VERSION "HNNBNNNYNNNNNNNNNNNNNNNNNNNNNNNNNNNNNNNNNN/4/%%%/4/'%**4NNN///"

NS_ :

BS_:

BU_: BAP_Tester BedienDisp_vo BedienSG_hi CGS DDA Gateway Gateway_PAG GurtMikrofon OTA_FC ZR_High ZR_LIMU ZR_MIB_TOP_ab_Gen3 ZR_Standard

BO_ 1626 BCM_01: 8 Gateway
 SG_ BCM_Bremsbelag_Sensor : 12|1@1+ (1.0,0.0) [0.0|1] ""  OTA_FC,ZR_High
 SG_ BCM_Bremsfluessigkeit_Sensor : 13|1@1+ (1.0,0.0) [0.0|1] ""  ZR_High
 SG_ BCM1_Licht_Warn : 14|1@1+ (1.0,0.0) [0.0|1] ""  Vector__XXX
 SG_ BCM_Waschwasser_Sensor : 15|1@1+ (1.0,0.0) [0.0|1] ""  OTA_FC,ZR_High
 SG_ BCM_Kuehlmittel_Sensor : 16|1@1+ (1.0,0.0) [0.0|1] ""  ZR_High
 SG_ BCM1_Kl_15_HW_erkannt : 17|1@1+ (1.0,0.0) [0.0|1] ""  Vector__XXX
 SG_ BCM1_Kl_15_Sig_HW_erkannt : 18|1@1+ (1.0,0.0) [0.0|1] ""  Vector__XXX
 SG_ BCM_Kuehlmittel_Sensor_02 : 19|1@1+ (1.0,0.0) [0.0|1] ""  ZR_High
 SG_ BCM1_Hinweis_Lichtnachlauf : 20|1@1+ (1.0,0.0) [0.0|1] ""  Vector__XXX
 SG_ BCM_Offroad_Taste : 21|1@1+ (1.0,0.0) [0.0|1] ""  Vector__XXX
 SG_ BCM_Hybrid_StSt_Taste_Fehler : 23|1@1+ (1.0,0.0) [0.0|1] ""  ZR_High
 SG_ BCM_Hybrid_StartStopp_Taste : 24|1@1+ (1.0,0.0) [0.0|1] ""  ZR_High
 SG_ BCM1_Warnblink_Taster : 25|1@1+ (1.0,0.0) [0.0|1] ""  ZR_High
 SG_ BCM1_Valet_Parking_Taster : 26|1@1+ (1.0,0.0) [0.0|1] ""  ZR_High
 SG_ BCM1_LDS_Stellung : 27|3@1+ (1.0,0.0) [0.0|7] ""  Vector__XXX
 SG_ BCM1_Rueckfahrlicht_Schalter : 30|1@1+ (1.0,0.0) [0.0|1] ""  Vector__XXX
 SG_ BCM1_MH_Schalter : 31|1@1+ (1.0,0.0) [0.0|1] ""  DDA,OTA_FC,ZR_High
 SG_ BCM1_MH_WIV_Schalter : 32|1@1+ (1.0,0.0) [0.0|1] ""  ZR_High
 SG_ BCM_Eco_Charisma_Taste : 33|1@1+ (1.0,0.0) [0.0|1] ""  Vector__XXX
 SG_ BCM1_NV_Taster : 34|1@1+ (1.0,0.0) [0.0|1] ""  ZR_High
 SG_ BCM1_AFS_Lampe : 35|1@1+ (1.0,0.0) [0.0|1] ""  ZR_High
 SG_ BCM1_Reisemodus_Texte : 36|2@1+ (1.0,0.0) [0.0|3] ""  ZR_High
 SG_ BCM1_Lichtwarn_Texte : 38|2@1+ (1.0,0.0) [0.0|3] ""  Vector__XXX
 SG_ Gong_TFL_Umschaltung : 40|1@1+ (1.0,0.0) [0.0|1] ""  Vector__XXX
 SG_ UGDO_Function_01 : 41|3@1+ (1.0,0.0) [0.0|7] ""  Vector__XXX
 SG_ APS_Tongeber_defekt : 44|1@1+ (1.0,0.0) [0.0|1] ""  Vector__XXX
 SG_ BCM1_EasyEntry_Status : 45|1@1+ (1.0,0.0) [0.0|1] ""  ZR_High
 SG_ BCM1_Lenksaeule_aktiv : 46|1@1+ (1.0,0.0) [0.0|1] ""  ZR_High
 SG_ BCM1_St_SW_Diebstahl_links : 47|1@1+ (1.0,0.0) [0.0|1] ""  ZR_High
 SG_ BCM1_St_SW_Diebstahl_rechts : 48|1@1+ (1.0,0.0) [0.0|1] ""  ZR_High
 SG_ ISP_Dimmung_ASP_02 : 49|6@1+ (0.0226,0) [0.0000|1.4012] "Unit_Volt"  Vector__XXX
 SG_ BCM1_Schluesselsuche_Anf : 55|1@1+ (1.0,0.0) [0.0|1] ""  Vector__XXX
 SG_ BCM1_Fahrlicht_Hinweis : 62|1@1+ (1.0,0.0) [0.0|1] ""  Vector__XXX
 SG_ BCM_HDF_betaetigt : 63|1@1+ (1.0,0.0) [0.0|1] ""  Vector__XXX

BO_ 672 BCM_02: 8 Gateway
 SG_ BCM_02_CRC : 0|8@1+ (1,0) [0|255] ""  Vector__XXX
 SG_ BCM_02_BZ : 8|4@1+ (1,0) [0|15] ""  Vector__XXX
 SG_ BCM2_Crashfall_erkannt : 12|1@1+ (1.0,0.0) [0.0|1] ""  Vector__XXX
 SG_ ZZH_Endlage_oben : 13|1@1+ (1.0,0.0) [0.0|1] ""  ZR_High
 SG_ ZZH_Endlage_unplausibel : 14|1@1+ (1.0,0.0) [0.0|1] ""  Vector__XXX
 SG_ ZZH_Endlage_unten : 15|1@1+ (1.0,0.0) [0.0|1] ""  ZR_High
 SG_ BCM2_Unterdr_Zuendungsmeldung : 16|1@1+ (1.0,0.0) [0.0|1] ""  Vector__XXX
 SG_ BCM2_SST_gedrueckt : 17|1@1+ (1.0,0.0) [0.0|1] ""  Vector__XXX
 SG_ BCM_Waehlhebel_P_Hinweis : 18|1@1+ (1.0,0.0) [0.0|1] ""  ZR_High
 SG_ BCM_ValetTaster_Fkts_LED : 19|1@1+ (1.0,0.0) [0.0|1] ""  ZR_High,ZR_LIMU,ZR_MIB_TOP_ab_Gen3,ZR_Standard
 SG_ BCM2_KL15_Absch_FT : 20|1@1+ (1.0,0.0) [0.0|1] ""  Vector__XXX
 SG_ Heckwischer_Status : 21|2@1+ (1.0,0.0) [0.0|3] ""  OTA_FC,ZR_High
 SG_ BCM2_P_verriegelt : 23|1@1+ (1.0,0.0) [0.0|1] ""  ZR_High
 SG_ FSH_LED : 24|1@1+ (1.0,0.0) [0.0|1] ""  ZR_High
 SG_ HSH_LED : 25|1@1+ (1.0,0.0) [0.0|1] ""  ZR_High
 SG_ Niveausensor_VL_verbaut : 26|1@1+ (1.0,0.0) [0.0|1] ""  Vector__XXX
 SG_ Niveausensor_HL_verbaut : 27|1@1+ (1.0,0.0) [0.0|1] ""  Vector__XXX
 SG_ FA_Hoehenwert_VL_01 : 28|8@1+ (0.4,0) [0.0|100.0] "Unit_PerCent"  Vector__XXX
 SG_ FA_Hoehenwert_HL_01 : 36|8@1+ (0.4,0) [0.0|100.0] "Unit_PerCent"  Vector__XXX
 SG_ BCM_Anf_Aussenwarnung : 44|1@1+ (1.0,0.0) [0.0|1] ""  Vector__XXX
 SG_ BCM_Aussenwarnung_Konfig : 45|3@1+ (1.0,0.0) [0.0|7] ""  Vector__XXX
 SG_ BCM2_Freigabe_Kofferr_Innenentr : 48|1@1+ (1.0,0.0) [0.0|1] ""  ZR_High
 SG_ BCM_RLU_Wakeup_Anforderung : 49|1@1+ (1.0,0.0) [0.0|1] ""  ZR_High,ZR_Standard
 SG_ Heckrollo_Privacy_aktiv : 50|1@1+ (1.0,0.0) [0.0|1] ""  BedienDisp_vo,ZR_High
 SG_ Heckrollo_Verfahrrichtung : 51|3@1+ (1.0,0.0) [0.0|7] ""  BedienDisp_vo,BedienSG_hi
 SG_ BCM2_TrunkEntrapment_Warn : 54|1@1+ (1.0,0.0) [0.0|1] ""  Vector__XXX
 SG_ BCM2_Quittierung_Warnton_aktiv : 55|1@1+ (1.0,0.0) [0.0|1] ""  Vector__XXX
 SG_ BCM_Handbremse_Hinweis : 56|1@1+ (1.0,0.0) [0.0|1] ""  Vector__XXX
 SG_ Remote_Rollo_HBFS_hoch : 57|1@1+ (1.0,0.0) [0.0|1] ""  Vector__XXX
 SG_ Remote_Rollo_HBFS_tief : 58|1@1+ (1.0,0.0) [0.0|1] ""  Vector__XXX
 SG_ Remote_Rollo_HFS_hoch : 59|1@1+ (1.0,0.0) [0.0|1] ""  Vector__XXX
 SG_ Remote_Rollo_HFS_tief : 60|1@1+ (1.0,0.0) [0.0|1] ""  Vector__XXX
 SG_ BCM2_T_Deckel_Vorne : 61|1@1+ (1.0,0.0) [0.0|1] ""  Vector__XXX

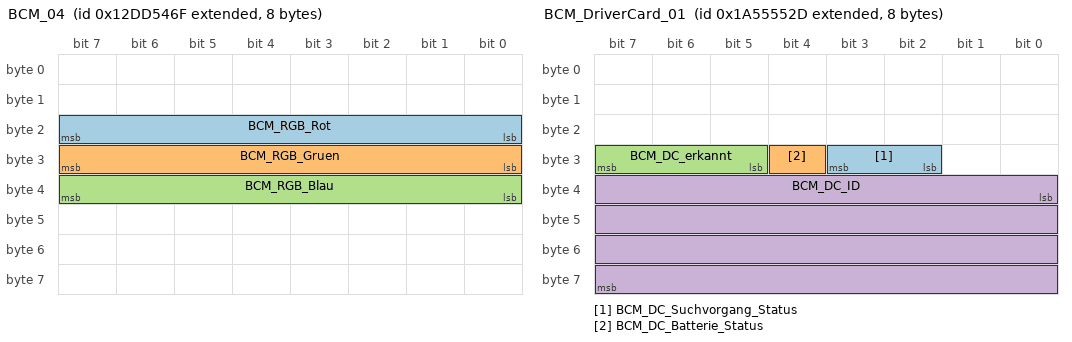
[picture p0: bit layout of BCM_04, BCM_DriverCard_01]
BO_ 2463978607 BCM_04: 8 Gateway
 SG_ BCM_RGB_Rot : 16|8@1+ (1,0) [0|255] ""  ZR_High
 SG_ BCM_RGB_Gruen : 24|8@1+ (1,0) [0|255] ""  ZR_High
 SG_ BCM_RGB_Blau : 32|8@1+ (1,0) [0|255] ""  ZR_High

BO_ 2589283629 BCM_DriverCard_01: 8 Gateway
 SG_ BCM_DC_Suchvorgang_Status : 26|2@1+ (1.0,0.0) [0.0|3] ""  ZR_High
 SG_ BCM_DC_Batterie_Status : 28|1@1+ (1.0,0.0) [0.0|1] ""  ZR_High
 SG_ BCM_DC_erkannt : 29|3@1+ (1.0,0.0) [0.0|7] ""  ZR_High
 SG_ BCM_DC_ID : 32|32@1+ (1,0) [0|4294967294] ""  Vector__XXX

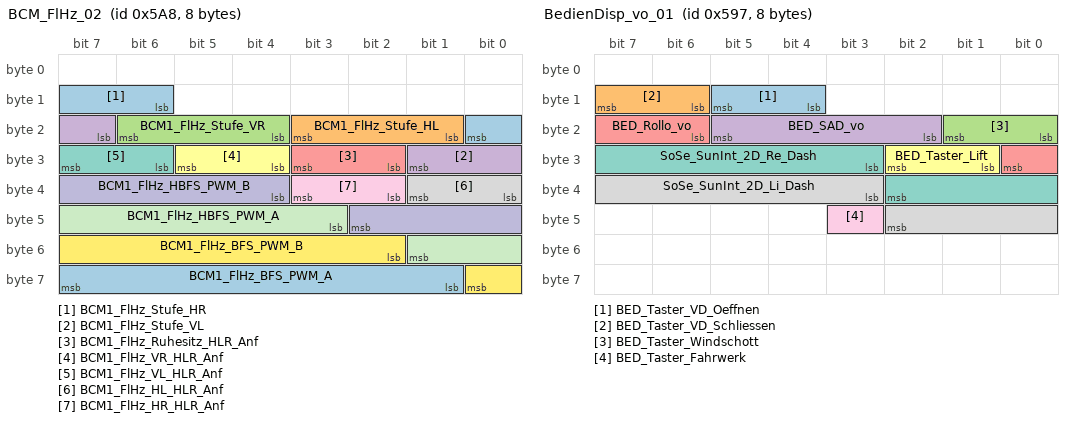
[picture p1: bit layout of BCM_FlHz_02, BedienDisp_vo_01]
BO_ 1448 BCM_FlHz_02: 8 Gateway
 SG_ BCM1_FlHz_Stufe_HR : 14|3@1+ (1.0,0.0) [0.0|7] ""  ZR_High
 SG_ BCM1_FlHz_Stufe_HL : 17|3@1+ (1.0,0.0) [0.0|7] ""  ZR_High
 SG_ BCM1_FlHz_Stufe_VR : 20|3@1+ (1.0,0.0) [0.0|7] ""  ZR_High
 SG_ BCM1_FlHz_Stufe_VL : 23|3@1+ (1.0,0.0) [0.0|7] ""  ZR_High
 SG_ BCM1_FlHz_Ruhesitz_HLR_Anf : 26|2@1+ (1.0,0.0) [0.0|3] ""  ZR_High
 SG_ BCM1_FlHz_VR_HLR_Anf : 28|2@1+ (1.0,0.0) [0.0|3] ""  ZR_High
 SG_ BCM1_FlHz_VL_HLR_Anf : 30|2@1+ (1.0,0.0) [0.0|3] ""  ZR_High
 SG_ BCM1_FlHz_HL_HLR_Anf : 32|2@1+ (1.0,0.0) [0.0|3] ""  ZR_High
 SG_ BCM1_FlHz_HR_HLR_Anf : 34|2@1+ (1.0,0.0) [0.0|3] ""  ZR_High
 SG_ BCM1_FlHz_HBFS_PWM_B : 36|7@1+ (1,0) [0|100] "Unit_PerCent"  Vector__XXX
 SG_ BCM1_FlHz_HBFS_PWM_A : 43|7@1+ (1,0) [0|100] "Unit_PerCent"  Vector__XXX
 SG_ BCM1_FlHz_BFS_PWM_B : 50|7@1+ (1,0) [0|100] "Unit_PerCent"  Vector__XXX
 SG_ BCM1_FlHz_BFS_PWM_A : 57|7@1+ (1,0) [0|100] "Unit_PerCent"  Vector__XXX

BO_ 961 BCM_Taster_01: 8 Gateway
 SG_ Heckrollo_2_Taster : 10|2@1+ (1.0,0.0) [0.0|3] ""  Vector__XXX
 SG_ APS_Taster : 12|2@1+ (1.0,0.0) [0.0|3] ""  ZR_High
 SG_ PLA_Taster : 14|2@1+ (1.0,0.0) [0.0|3] ""  ZR_High,ZR_LIMU,ZR_MIB_TOP_ab_Gen3,ZR_Standard
 SG_ ESP_Off_Taster : 16|2@1+ (1.0,0.0) [0.0|3] ""  OTA_FC,ZR_High
 SG_ HDC_Taster : 18|2@1+ (1.0,0.0) [0.0|3] ""  ZR_High
 SG_ AVH_Taster : 20|2@1+ (1.0,0.0) [0.0|3] ""  ZR_High
 SG_ Display_Taster : 22|2@1+ (1.0,0.0) [0.0|3] ""  ZR_High,ZR_LIMU,ZR_MIB_TOP_ab_Gen3,ZR_Standard
 SG_ Heckrollo_Taster : 24|2@1+ (1.0,0.0) [0.0|3] ""  ZR_High
 SG_ Spoiler_Taster : 26|2@1+ (1.0,0.0) [0.0|3] ""  OTA_FC,ZR_High
 SG_ Drivesel_1_Taster : 28|2@1+ (1.0,0.0) [0.0|3] ""  ZR_High
 SG_ Drivesel_2_Taster : 30|2@1+ (1.0,0.0) [0.0|3] ""  ZR_High
 SG_ Sideview_Taster : 32|2@1+ (1.0,0.0) [0.0|3] ""  ZR_High
 SG_ LIM_PAO_Alivesignal : 34|4@1+ (1,0) [0|15] ""  Vector__XXX
 SG_ LKS_Taster : 38|2@1+ (1.0,0.0) [0.0|3] ""  Vector__XXX
 SG_ SWA_Taster : 40|2@1+ (1.0,0.0) [0.0|3] ""  ZR_High
 SG_ LIM_bCall_Taster : 42|1@1+ (1.0,0.0) [0.0|1] ""  ZR_High
 SG_ eCall_Taste : 43|2@1+ (1.0,0.0) [0.0|3] ""  ZR_High,ZR_LIMU,ZR_MIB_TOP_ab_Gen3
 SG_ PLA_Taster_Fehler_Roh : 45|1@1+ (1.0,0.0) [0.0|1] ""  Vector__XXX
 SG_ LIM_PAO_ON_Status : 46|2@1+ (1.0,0.0) [0.0|3] ""  Vector__XXX
 SG_ LIM_PAO_OFF_Status : 48|2@1+ (1.0,0.0) [0.0|3] ""  Vector__XXX
 SG_ LIM_PAO_Schriftzug_Status : 50|2@1+ (1.0,0.0) [0.0|3] ""  Vector__XXX
 SG_ Spoiler_LED_Status : 52|2@1+ (1.0,0.0) [0.0|3] ""  Vector__XXX
 SG_ AVH_LED_Status : 54|2@1+ (1.0,0.0) [0.0|3] ""  Vector__XXX
 SG_ HDC_LED_Status : 56|2@1+ (1.0,0.0) [0.0|3] ""  Vector__XXX
 SG_ PLA_LED_Status : 60|2@1+ (1.0,0.0) [0.0|3] ""  Vector__XXX
 SG_ APS_LED_Status : 62|2@1+ (1.0,0.0) [0.0|3] ""  Vector__XXX

BO_ 1432 BCM_Taster_02: 8 Gateway
 SG_ BCM_BFS_Fernsteuerung_aktiv : 28|1@1+ (1.0,0.0) [0.0|1] ""  Vector__XXX
 SG_ BCM_Soundklappe_Taster : 29|1@1+ (1.0,0.0) [0.0|1] ""  Vector__XXX
 SG_ E_Sound_LED_Status : 30|2@1+ (1.0,0.0) [0.0|3] ""  Vector__XXX
 SG_ Pilot_Taster : 32|2@1+ (1.0,0.0) [0.0|3] ""  ZR_High
 SG_ BCM1_eSound_Taster : 34|2@1+ (1.0,0.0) [0.0|3] ""  ZR_High
 SG_ BCM_FS_Programmwippe : 37|1@1+ (1.0,0.0) [0.0|1] ""  ZR_High
 SG_ BCM_BFS_Programmwippe : 38|1@1+ (1.0,0.0) [0.0|1] ""  ZR_High
 SG_ BCM_FS_Multif_Taster : 39|1@1+ (1.0,0.0) [0.0|1] ""  ZR_High
 SG_ BCM_BFS_Multif_Taster : 40|1@1+ (1.0,0.0) [0.0|1] ""  ZR_High
 SG_ BCM_FS_Massage_Taster : 41|1@1+ (1.0,0.0) [0.0|1] ""  ZR_High
 SG_ BCM_BFS_Massage_Taster : 42|1@1+ (1.0,0.0) [0.0|1] ""  ZR_High
 SG_ BCM_FS_Pneumatik_Verstellung : 43|1@1+ (1.0,0.0) [0.0|1] ""  ZR_High
 SG_ BCM_BFS_Pneumatik_Verstellung : 44|1@1+ (1.0,0.0) [0.0|1] ""  ZR_High
 SG_ LIM_Rear_Mode : 45|1@1+ (1.0,0.0) [0.0|1] ""  Vector__XXX
 SG_ BCM1_NR_Ride_Height_Up_Taster : 46|2@1+ (1.0,0.0) [0.0|3] ""  ZR_High
 SG_ BCM1_NR_Ride_Height_Down_Taster : 48|2@1+ (1.0,0.0) [0.0|3] ""  ZR_High
 SG_ LIM_S_Rollo_vo : 50|3@1+ (1.0,0.0) [0.0|7] ""  ZR_High
 SG_ LIM_S_Rollo_hi : 53|3@1+ (1.0,0.0) [0.0|7] ""  ZR_High
 SG_ LIM_S_SAD_Vo : 56|4@1+ (1.0,0.0) [0.0|15] ""  ZR_High
 SG_ LIM_S_SAD_hi : 60|4@1+ (1.0,0.0) [0.0|15] ""  ZR_High

BO_ 1462 BEB_hi_01: 8 BedienDisp_vo
 SG_ BEB_hi_SAD_Rollo_AutoAuf : 12|1@1+ (1.0,0.0) [0.0|1] ""  Gateway,Gateway_PAG,ZR_High
 SG_ BEB_hi_SAD_Rollo_AutoZu : 13|1@1+ (1.0,0.0) [0.0|1] ""  Gateway,Gateway_PAG,ZR_High
 SG_ BEB_hi_SAD_Rollo_ManAuf : 14|1@1+ (1.0,0.0) [0.0|1] ""  Gateway,Gateway_PAG,ZR_High
 SG_ BEB_hi_SAD_Rollo_ManZu : 15|1@1+ (1.0,0.0) [0.0|1] ""  Gateway,Gateway_PAG,ZR_High
 SG_ BEB_hi_T_SIH_HL : 16|1@1+ (1.0,0.0) [0.0|1] ""  Gateway,Gateway_PAG,ZR_High
 SG_ BEB_hi_T_SIH_HR : 17|1@1+ (1.0,0.0) [0.0|1] ""  Gateway,Gateway_PAG,ZR_High
 SG_ BEB_hi_T_SIL_HL : 18|1@1+ (1.0,0.0) [0.0|1] ""  Gateway,Gateway_PAG,ZR_High
 SG_ BEB_hi_T_SIL_HR : 19|1@1+ (1.0,0.0) [0.0|1] ""  Gateway,Gateway_PAG,ZR_High
 SG_ SL1_Heckrollo_Taster : 20|2@1+ (1.0,0.0) [0.0|3] ""  Gateway,Gateway_PAG,ZR_High
 SG_ BEB_hi_SAD_Rollo_defekt : 22|1@1+ (1.0,0.0) [0.0|1] ""  Gateway,Gateway_PAG,ZR_High
 SG_ BEB_hi_SAD_Rollo_haengt : 23|1@1+ (1.0,0.0) [0.0|1] ""  Gateway,Gateway_PAG,ZR_High
 SG_ BEB_hi_T_Lueftung : 24|1@1+ (1.0,0.0) [0.0|1] ""  Gateway,Gateway_PAG,ZR_High
 SG_ BEB_hi_T_Lueftung_oben : 25|1@1+ (1.0,0.0) [0.0|1] ""  Gateway,Gateway_PAG,ZR_High
 SG_ BEB_hi_T_Lueftung_unten : 26|1@1+ (1.0,0.0) [0.0|1] ""  Gateway,Gateway_PAG,ZR_High
 SG_ BEB_hi_T_Lueftung_LZ_links : 27|1@1+ (1.0,0.0) [0.0|1] ""  Gateway,Gateway_PAG,ZR_High
 SG_ BEB_hi_T_Lueftung_LZ_rechts : 28|1@1+ (1.0,0.0) [0.0|1] ""  Gateway,Gateway_PAG,ZR_High
 SG_ BEB_hi_T_Lueftung_RZ_links : 29|1@1+ (1.0,0.0) [0.0|1] ""  Gateway,Gateway_PAG,ZR_High
 SG_ BEB_hi_T_Lueftung_RZ_rechts : 30|1@1+ (1.0,0.0) [0.0|1] ""  Gateway,Gateway_PAG,ZR_High
 SG_ BEB_hi_ResponseError : 63|1@1+ (1.0,0.0) [0.0|1] ""  Gateway,Gateway_PAG

BO_ 1431 BedienDisp_vo_01: 8 BedienDisp_vo
 SG_ BED_Taster_VD_Oeffnen : 12|2@1+ (1.0,0.0) [0.0|3] ""  Gateway,Gateway_PAG
 SG_ BED_Taster_VD_Schliessen : 14|2@1+ (1.0,0.0) [0.0|3] ""  Gateway,Gateway_PAG
 SG_ BED_Taster_Windschott : 16|2@1+ (1.0,0.0) [0.0|3] ""  Gateway,Gateway_PAG
 SG_ BED_SAD_vo : 18|4@1+ (1.0,0.0) [0.0|15] ""  Gateway,Gateway_PAG
 SG_ BED_Rollo_vo : 22|3@1+ (1.0,0.0) [0.0|7] ""  Gateway,Gateway_PAG
 SG_ BED_Taster_Lift : 25|2@1+ (1.0,0.0) [0.0|3] ""  Gateway,Gateway_PAG
 SG_ SoSe_SunInt_2D_Re_Dash : 27|8@1+ (5,0) [0|1200] "Unit_WattPerMeterSquar"  Gateway,Gateway_PAG
 SG_ SoSe_SunInt_2D_Li_Dash : 35|8@1+ (5,0) [0|1200] "Unit_WattPerMeterSquar"  Gateway,Gateway_PAG
 SG_ BED_Taster_Fahrwerk : 43|1@1+ (1.0,0.0) [0.0|1] ""  Gateway,Gateway_PAG

BO_ 870 Blinkmodi_02: 8 Gateway
 SG_ BM_ZV_auf : 12|1@1+ (1.0,0.0) [0.0|1] ""  ZR_High
 SG_ BM_ZV_zu : 13|1@1+ (1.0,0.0) [0.0|1] ""  ZR_High
 SG_ BM_DWA_ein : 14|1@1+ (1.0,0.0) [0.0|1] ""  ZR_High
 SG_ BM_DWA_Alarm : 15|1@1+ (1.0,0.0) [0.0|1] ""  ZR_High
 SG_ BM_Crash : 16|1@1+ (1.0,0.0) [0.0|1] ""  ZR_High
 SG_ BM_Panik : 17|1@1+ (1.0,0.0) [0.0|1] ""  ZR_High
 SG_ BM_Not_Bremsung : 18|1@1+ (1.0,0.0) [0.0|1] ""  ZR_High
 SG_ BM_GDO : 19|1@1+ (1.0,0.0) [0.0|1] ""  Vector__XXX
 SG_ BM_Warnblinken : 20|1@1+ (1.0,0.0) [0.0|1] ""  ZR_High
 SG_ BM_Taxi_Notalarm : 21|1@1+ (1.0,0.0) [0.0|1] ""  ZR_High
 SG_ BM_Telematik : 22|1@1+ (1.0,0.0) [0.0|1] ""  ZR_High
 SG_ BM_links : 23|1@1+ (1.0,0.0) [0.0|1] ""  ZR_High
 SG_ BM_rechts : 24|1@1+ (1.0,0.0) [0.0|1] ""  ZR_High
 SG_ Blinken_li_Fzg_Takt : 25|1@1+ (1.0,0.0) [0.0|1] ""  ZR_High
 SG_ Blinken_re_Fzg_Takt : 26|1@1+ (1.0,0.0) [0.0|1] ""  ZR_High
 SG_ Blinken_li_Kombi_Takt : 27|1@1+ (1.0,0.0) [0.0|1] ""  ZR_High,ZR_LIMU,ZR_MIB_TOP_ab_Gen3,ZR_Standard
 SG_ Blinken_re_Kombi_Takt : 28|1@1+ (1.0,0.0) [0.0|1] ""  ZR_High,ZR_LIMU,ZR_MIB_TOP_ab_Gen3,ZR_Standard
 SG_ BM_NBA_n_codiert_n_aktiv : 29|1@1+ (1.0,0.0) [0.0|1] ""  Vector__XXX
 SG_ BM_NBA_Status : 30|2@1+ (1.0,0.0) [0.0|3] ""  Vector__XXX
 SG_ BM_WBT_Beleuchtung : 32|1@1+ (1.0,0.0) [0.0|1] ""  ZR_High
 SG_ BM_HD_Oeffnung_angelernt : 33|1@1+ (1.0,0.0) [0.0|1] ""  Vector__XXX
 SG_ BM_Autobahn : 34|1@1+ (1.0,0.0) [0.0|1] ""  ZR_High,ZR_LIMU,ZR_MIB_TOP_ab_Gen3
 SG_ BM_Rollenmodus_Blinken : 35|1@1+ (1.0,0.0) [0.0|1] ""  Vector__XXX
 SG_ BM_Recas : 36|1@1+ (1.0,0.0) [0.0|1] ""  ZR_High
 SG_ BM_Wischblinken : 37|1@1+ (1.0,0.0) [0.0|1] ""  ZR_High
 SG_ BM_Telematik_Abbruchgrund : 38|6@1+ (1.0,0.0) [0.0|63] ""  Vector__XXX
 SG_ BM_PiloPa : 44|1@1+ (1.0,0.0) [0.0|1] ""  ZR_High
 SG_ DWA_Alarmquelle : 59|5@1+ (1.0,0.0) [0.0|31] ""  ZR_High

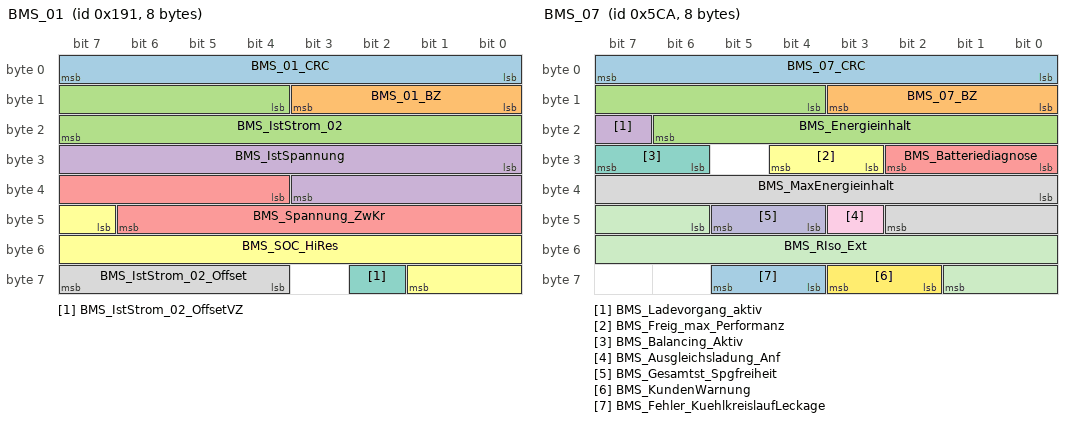
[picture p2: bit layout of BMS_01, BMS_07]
BO_ 401 BMS_01: 8 Gateway
 SG_ BMS_01_CRC : 0|8@1+ (1,0) [0|255] ""  Vector__XXX
 SG_ BMS_01_BZ : 8|4@1+ (1,0) [0|15] ""  Vector__XXX
 SG_ BMS_IstStrom_02 : 12|12@1+ (1,-2047) [-2047|2046] "Unit_Amper"  OTA_FC,ZR_High
 SG_ BMS_IstSpannung : 24|12@1+ (0.25,0) [0.00|1023.25] "Unit_Volt"  BedienSG_hi,OTA_FC,ZR_High
 SG_ BMS_Spannung_ZwKr : 36|11@1+ (0.5,0) [0.0|1022.5] "Unit_Volt"  OTA_FC,ZR_High
 SG_ BMS_SOC_HiRes : 47|11@1+ (0.05,0) [0.00|100.00] "Unit_PerCent"  OTA_FC,ZR_High
 SG_ BMS_IstStrom_02_OffsetVZ : 58|1@1+ (1.0,0.0) [0.0|1] ""  OTA_FC
 SG_ BMS_IstStrom_02_Offset : 60|4@1+ (0.0625,0) [0.0000|0.9375] "Unit_Amper"  OTA_FC

BO_ 1482 BMS_07: 8 Gateway
 SG_ BMS_07_CRC : 0|8@1+ (1,0) [0|255] ""  Vector__XXX
 SG_ BMS_07_BZ : 8|4@1+ (1,0) [0|15] ""  Vector__XXX
 SG_ BMS_Energieinhalt : 12|11@1+ (50,0) [0|102250] "Unit_WattHour"  OTA_FC
 SG_ BMS_Ladevorgang_aktiv : 23|1@1+ (1.0,0.0) [0.0|1] ""  OTA_FC,ZR_LIMU,ZR_MIB_TOP_ab_Gen3
 SG_ BMS_Batteriediagnose : 24|3@1+ (1.0,0.0) [0.0|7] ""  Vector__XXX
 SG_ BMS_Freig_max_Performanz : 27|2@1+ (1.0,0.0) [0.0|3] ""  Vector__XXX
 SG_ BMS_Balancing_Aktiv : 30|2@1+ (1.0,0.0) [0.0|3] ""  Vector__XXX
 SG_ BMS_MaxEnergieinhalt : 32|11@1+ (50,0) [0|102250] "Unit_WattHour"  OTA_FC
 SG_ BMS_Ausgleichsladung_Anf : 43|1@1+ (1.0,0.0) [0.0|1] ""  Vector__XXX
 SG_ BMS_Gesamtst_Spgfreiheit : 44|2@1+ (1.0,0.0) [0.0|3] ""  Vector__XXX
 SG_ BMS_RIso_Ext : 46|12@1+ (5,0) [0|20465] "Unit_KiloOhm"  Vector__XXX
 SG_ BMS_KundenWarnung : 58|2@1+ (1.0,0.0) [0.0|3] ""  Vector__XXX
 SG_ BMS_Fehler_KuehlkreislaufLeckage : 60|2@1+ (1.0,0.0) [0.0|3] ""  Vector__XXX

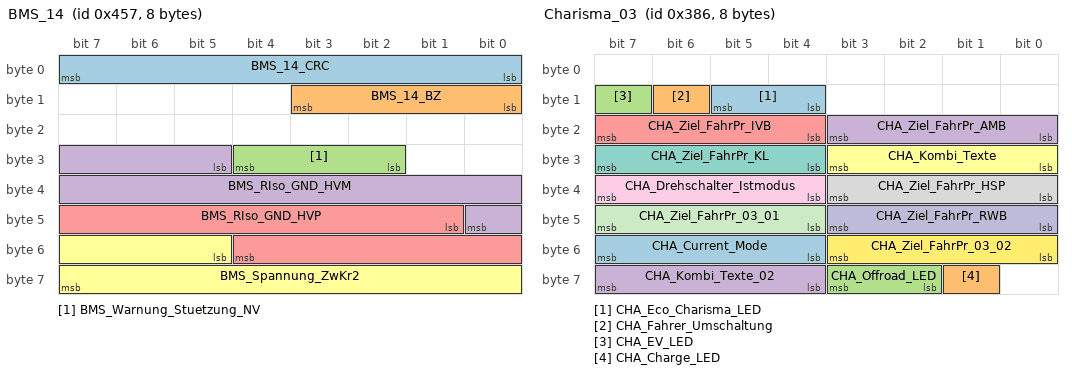
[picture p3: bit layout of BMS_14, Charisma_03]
BO_ 1111 BMS_14: 8 Gateway
 SG_ BMS_14_CRC : 0|8@1+ (1,0) [0|255] ""  Vector__XXX
 SG_ BMS_14_BZ : 8|4@1+ (1,0) [0|15] ""  Vector__XXX
 SG_ BMS_Warnung_Stuetzung_NV : 26|3@1+ (1.0,0.0) [0.0|7] ""  Vector__XXX
 SG_ BMS_RIso_GND_HVM : 29|12@1+ (5,-20465) [-20465|0] "Unit_KiloOhm"  Vector__XXX
 SG_ BMS_RIso_GND_HVP : 41|12@1+ (5,0) [0|20465] "Unit_KiloOhm"  Vector__XXX
 SG_ BMS_Spannung_ZwKr2 : 53|11@1+ (0.5,0) [0.0|1022.5] "Unit_Volt"  ZR_High

BO_ 823 CC_Einzelhindernis_01: 8 Gateway
 SG_ CC_MessZeitpunkt_OffsetHindernis : 0|2@1+ (5.08,0) [0.00|15.24] "Unit_Secon"  ZR_High,ZR_LIMU,ZR_MIB_TOP_ab_Gen3
 SG_ CC_MessZeitpunkt_Hindernis : 2|7@1+ (0.04,0) [0.00|5.04] "Unit_None"  ZR_High,ZR_LIMU,ZR_MIB_TOP_ab_Gen3
 SG_ CC_MessZeitpunkt_ms_Hindernis : 9|6@1+ (1,0) [0|39] "Unit_MilliSecon"  ZR_High,ZR_LIMU,ZR_MIB_TOP_ab_Gen3
 SG_ CC_Einzelhindernis_01 : 16|4@1+ (1.0,0.0) [0.0|15] ""  ZR_High,ZR_LIMU,ZR_MIB_TOP_ab_Gen3
 SG_ CC_CF_Einzelhindernis_01 : 20|2@1+ (1.0,0.0) [0.0|3] ""  ZR_High,ZR_LIMU,ZR_MIB_TOP_ab_Gen3
 SG_ CC_Einzelhindernis_02 : 22|4@1+ (1.0,0.0) [0.0|15] ""  ZR_High,ZR_LIMU,ZR_MIB_TOP_ab_Gen3
 SG_ CC_CF_Einzelhindernis_02 : 26|2@1+ (1.0,0.0) [0.0|3] ""  ZR_High,ZR_LIMU,ZR_MIB_TOP_ab_Gen3
 SG_ CC_Einzelhindernis_03 : 28|4@1+ (1.0,0.0) [0.0|15] ""  ZR_High,ZR_LIMU,ZR_MIB_TOP_ab_Gen3
 SG_ CC_CF_Einzelhindernis_03 : 32|2@1+ (1.0,0.0) [0.0|3] ""  ZR_High,ZR_LIMU,ZR_MIB_TOP_ab_Gen3
 SG_ CC_Einzelhindernis_04 : 34|4@1+ (1.0,0.0) [0.0|15] ""  ZR_High,ZR_LIMU,ZR_MIB_TOP_ab_Gen3
 SG_ CC_CF_Einzelhindernis_04 : 38|2@1+ (1.0,0.0) [0.0|3] ""  ZR_High,ZR_LIMU,ZR_MIB_TOP_ab_Gen3
 SG_ CC_Einzelhindernis_05 : 40|4@1+ (1.0,0.0) [0.0|15] ""  ZR_High,ZR_LIMU,ZR_MIB_TOP_ab_Gen3
 SG_ CC_CF_Einzelhindernis_05 : 44|2@1+ (1.0,0.0) [0.0|3] ""  ZR_High,ZR_LIMU,ZR_MIB_TOP_ab_Gen3
 SG_ CC_Einzelhindernis_06 : 46|4@1+ (1.0,0.0) [0.0|15] ""  ZR_High,ZR_LIMU,ZR_MIB_TOP_ab_Gen3
 SG_ CC_CF_Einzelhindernis_06 : 50|2@1+ (1.0,0.0) [0.0|3] ""  ZR_High,ZR_LIMU,ZR_MIB_TOP_ab_Gen3
 SG_ CC_Einzelhindernis_07 : 52|4@1+ (1.0,0.0) [0.0|15] ""  ZR_High,ZR_LIMU,ZR_MIB_TOP_ab_Gen3
 SG_ CC_CF_Einzelhindernis_07 : 56|2@1+ (1.0,0.0) [0.0|3] ""  ZR_High,ZR_LIMU,ZR_MIB_TOP_ab_Gen3
 SG_ CC_Einzelhindernis_08 : 58|4@1+ (1.0,0.0) [0.0|15] ""  ZR_High,ZR_LIMU,ZR_MIB_TOP_ab_Gen3
 SG_ CC_CF_Einzelhindernis_08 : 62|2@1+ (1.0,0.0) [0.0|3] ""  ZR_High,ZR_LIMU,ZR_MIB_TOP_ab_Gen3

BO_ 824 CC_Strassenkategorie_01: 8 Gateway
 SG_ CC_MessZeitpunkt_OffsetStrZustan : 0|2@1+ (5.08,0) [0.00|15.24] "Unit_Secon"  ZR_High,ZR_LIMU,ZR_MIB_TOP_ab_Gen3
 SG_ CC_MessZeitpunkt_Strassenzustand : 2|7@1+ (0.04,0) [0.00|5.04] "Unit_None"  ZR_High,ZR_LIMU,ZR_MIB_TOP_ab_Gen3
 SG_ CC_MessZeitpunkt_ms_StrZustand : 9|6@1+ (1,0) [0|39] "Unit_MilliSecon"  ZR_High,ZR_LIMU,ZR_MIB_TOP_ab_Gen3
 SG_ CC_Strassenkategorie_01 : 16|4@1+ (1.0,0.0) [0.0|15] ""  ZR_High,ZR_LIMU,ZR_MIB_TOP_ab_Gen3
 SG_ CC_CF_Strassenkategorie_01 : 20|2@1+ (1.0,0.0) [0.0|3] ""  ZR_High,ZR_LIMU,ZR_MIB_TOP_ab_Gen3
 SG_ CC_Strassenkategorie_02 : 22|4@1+ (1.0,0.0) [0.0|15] ""  ZR_High,ZR_LIMU,ZR_MIB_TOP_ab_Gen3
 SG_ CC_CF_Strassenkategorie_02 : 26|2@1+ (1.0,0.0) [0.0|3] ""  ZR_High,ZR_LIMU,ZR_MIB_TOP_ab_Gen3
 SG_ CC_Strassenkategorie_03 : 28|4@1+ (1.0,0.0) [0.0|15] ""  ZR_High,ZR_LIMU,ZR_MIB_TOP_ab_Gen3
 SG_ CC_CF_Strassenkategorie_03 : 32|2@1+ (1.0,0.0) [0.0|3] ""  ZR_High,ZR_LIMU,ZR_MIB_TOP_ab_Gen3
 SG_ CC_Strassenkategorie_04 : 34|4@1+ (1.0,0.0) [0.0|15] ""  ZR_High,ZR_LIMU,ZR_MIB_TOP_ab_Gen3
 SG_ CC_CF_Strassenkategorie_04 : 38|2@1+ (1.0,0.0) [0.0|3] ""  ZR_High,ZR_LIMU,ZR_MIB_TOP_ab_Gen3
 SG_ CC_Strassenkategorie_05 : 40|4@1+ (1.0,0.0) [0.0|15] ""  ZR_High,ZR_LIMU,ZR_MIB_TOP_ab_Gen3
 SG_ CC_CF_Strassenkategorie_05 : 44|2@1+ (1.0,0.0) [0.0|3] ""  ZR_High,ZR_LIMU,ZR_MIB_TOP_ab_Gen3
 SG_ CC_Strassenkategorie_06 : 46|4@1+ (1.0,0.0) [0.0|15] ""  ZR_High,ZR_LIMU,ZR_MIB_TOP_ab_Gen3
 SG_ CC_CF_Strassenkategorie_06 : 50|2@1+ (1.0,0.0) [0.0|3] ""  ZR_High,ZR_LIMU,ZR_MIB_TOP_ab_Gen3
 SG_ CC_Strassenkategorie_07 : 52|4@1+ (1.0,0.0) [0.0|15] ""  ZR_High,ZR_LIMU,ZR_MIB_TOP_ab_Gen3
 SG_ CC_CF_Strassenkategorie_07 : 56|2@1+ (1.0,0.0) [0.0|3] ""  ZR_High,ZR_LIMU,ZR_MIB_TOP_ab_Gen3
 SG_ CC_Strassenkategorie_08 : 58|4@1+ (1.0,0.0) [0.0|15] ""  ZR_High,ZR_LIMU,ZR_MIB_TOP_ab_Gen3
 SG_ CC_CF_Strassenkategorie_08 : 62|2@1+ (1.0,0.0) [0.0|3] ""  ZR_High,ZR_LIMU,ZR_MIB_TOP_ab_Gen3

BO_ 825 CC_Version_01: 8 Gateway
 SG_ CC_Version_Hindernis : 0|7@1+ (1,0) [1|127] "Unit_None"  ZR_High,ZR_LIMU,ZR_MIB_TOP_ab_Gen3
 SG_ CC_Version_Strassenkategorie : 7|7@1+ (1,0) [1|127] "Unit_None"  ZR_High,ZR_LIMU,ZR_MIB_TOP_ab_Gen3

BO_ 901 Charisma_01: 8 Gateway
 SG_ CHA_Ziel_FahrPr_AGA : 0|4@1+ (1.0,0.0) [0.0|15] ""  OTA_FC,ZR_High
 SG_ CHA_Ziel_FahrPr_ESP : 4|4@1+ (1.0,0.0) [0.0|15] ""  ZR_High
 SG_ CHA_Ziel_FahrPr_Freilauf : 8|4@1+ (1.0,0.0) [0.0|15] ""  ZR_High
 SG_ CHA_Fahrer_Umschaltung : 14|1@1+ (1.0,0.0) [0.0|1] ""  ZR_High
 SG_ CHA_Fahrer_Umschaltung_BMA : 15|1@1+ (1.0,0.0) [0.0|1] ""  ZR_High
 SG_ CHA_Ziel_FahrPr_MO : 16|4@1+ (1.0,0.0) [0.0|15] ""  ZR_High
 SG_ CHA_Ziel_FahrPr_GE : 20|4@1+ (1.0,0.0) [0.0|15] ""  ZR_High
 SG_ CHA_Ziel_FahrPr_ALR : 24|4@1+ (1.0,0.0) [0.0|15] ""  ZR_High
 SG_ CHA_Ziel_FahrPr_MO_BZS : 28|4@1+ (1.0,0.0) [0.0|15] ""  ZR_High
 SG_ CHA_Ziel_FahrPr_DR : 32|4@1+ (1.0,0.0) [0.0|15] ""  ZR_High
 SG_ CHA_Ziel_FahrPr_VAQ : 36|4@1+ (1.0,0.0) [0.0|15] ""  Vector__XXX
 SG_ CHA_Ziel_FahrPr_AFS : 40|4@1+ (1.0,0.0) [0.0|15] ""  ZR_High
 SG_ CHA_Ziel_FahrPr_PreCrash : 44|4@1+ (1.0,0.0) [0.0|15] ""  ZR_High
 SG_ CHA_Ziel_FahrPr_EPS : 48|4@1+ (1.0,0.0) [0.0|15] ""  ZR_High
 SG_ CHA_Ziel_FahrPr_ACC : 52|4@1+ (1.0,0.0) [0.0|15] ""  OTA_FC,ZR_High
 SG_ CHA_Ziel_FahrPr_SAK : 56|4@1+ (1.0,0.0) [0.0|15] ""  OTA_FC,ZR_High
 SG_ CHA_Ziel_FahrPr_MO_StSt : 60|4@1+ (1.0,0.0) [0.0|15] ""  ZR_High

BO_ 902 Charisma_03: 8 Gateway
 SG_ CHA_Eco_Charisma_LED : 12|2@1+ (1.0,0.0) [0.0|3] ""  Vector__XXX
 SG_ CHA_Fahrer_Umschaltung : 14|1@1+ (1.0,0.0) [0.0|1] ""  Vector__XXX
 SG_ CHA_EV_LED : 15|1@1+ (1.0,0.0) [0.0|1] ""  Vector__XXX
 SG_ CHA_Ziel_FahrPr_AMB : 16|4@1+ (1.0,0.0) [0.0|15] ""  Vector__XXX
 SG_ CHA_Ziel_FahrPr_IVB : 20|4@1+ (1.0,0.0) [0.0|15] ""  Vector__XXX
 SG_ CHA_Kombi_Texte : 24|4@1+ (1.0,0.0) [0.0|15] ""  Vector__XXX
 SG_ CHA_Ziel_FahrPr_KL : 28|4@1+ (1.0,0.0) [0.0|15] ""  Vector__XXX
 SG_ CHA_Ziel_FahrPr_HSP : 32|4@1+ (1.0,0.0) [0.0|15] ""  OTA_FC
 SG_ CHA_Drehschalter_Istmodus : 36|4@1+ (1.0,0.0) [0.0|15] ""  Vector__XXX
 SG_ CHA_Ziel_FahrPr_RWB : 40|4@1+ (1.0,0.0) [0.0|15] ""  OTA_FC
 SG_ CHA_Ziel_FahrPr_03_01 : 44|4@1+ (1.0,0.0) [0.0|15] ""  Vector__XXX
 SG_ CHA_Ziel_FahrPr_03_02 : 48|4@1+ (1.0,0.0) [0.0|15] ""  Vector__XXX
 SG_ CHA_Current_Mode : 52|4@1+ (1.0,0.0) [0.0|15] ""  OTA_FC
 SG_ CHA_Charge_LED : 57|1@1+ (1.0,0.0) [0.0|1] ""  Vector__XXX
 SG_ CHA_Offroad_LED : 58|2@1+ (1.0,0.0) [0.0|3] ""  ZR_High
 SG_ CHA_Kombi_Texte_02 : 60|4@1+ (1.0,0.0) [0.0|15] ""  Vector__XXX

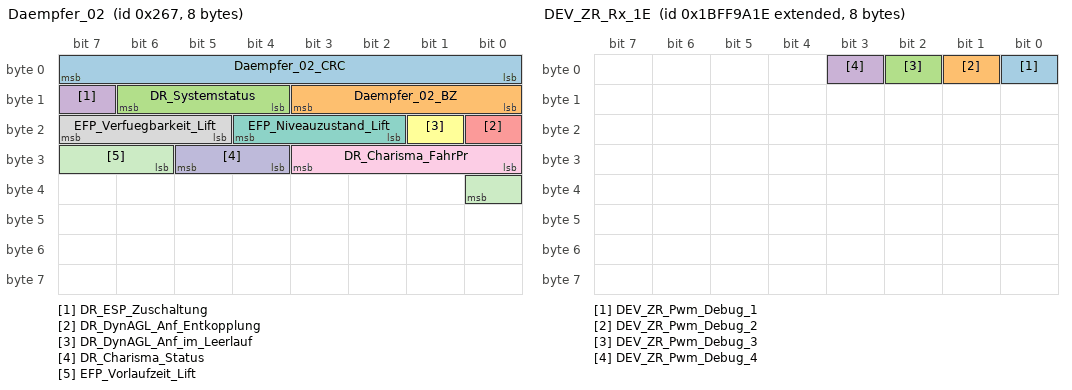
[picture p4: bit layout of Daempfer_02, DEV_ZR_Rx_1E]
BO_ 615 Daempfer_02: 8 Gateway
 SG_ Daempfer_02_CRC : 0|8@1+ (1,0) [0|255] ""  Vector__XXX
 SG_ Daempfer_02_BZ : 8|4@1+ (1,0) [0|15] ""  Vector__XXX
 SG_ DR_Systemstatus : 12|3@1+ (1.0,0.0) [0.0|7] ""  OTA_FC,ZR_High
 SG_ DR_ESP_Zuschaltung : 15|1@1+ (1.0,0.0) [0.0|1] ""  ZR_High
 SG_ DR_DynAGL_Anf_Entkopplung : 16|1@1+ (1.0,0.0) [0.0|1] ""  Vector__XXX
 SG_ DR_DynAGL_Anf_im_Leerlauf : 17|1@1+ (1.0,0.0) [0.0|1] ""  Vector__XXX
 SG_ EFP_Niveauzustand_Lift : 18|3@1+ (1.0,0.0) [0.0|7] ""  Vector__XXX
 SG_ EFP_Verfuegbarkeit_Lift : 21|3@1+ (1.0,0.0) [0.0|7] ""  Vector__XXX
 SG_ DR_Charisma_FahrPr : 24|4@1+ (1.0,0.0) [0.0|15] ""  OTA_FC
 SG_ DR_Charisma_Status : 28|2@1+ (1.0,0.0) [0.0|3] ""  Vector__XXX
 SG_ EFP_Vorlaufzeit_Lift : 30|3@1+ (1,3) [3|8] "Unit_Secon"  Vector__XXX

BO_ 2617012992 DEV_BedienDisp_vo_Resp_00: 8 BedienDisp_vo
 SG_ DEV_BedienDisp_vo_Resp_00_Data : 0|64@1+ (1.0,0.0) [0.0|18446744073709551615] ""  Vector__XXX

BO_ 2617013247 DEV_BedienDisp_vo_Resp_FF: 8 BedienDisp_vo
 SG_ DEV_BedienDisp_vo_Resp_FF_Data : 0|64@1+ (1.0,0.0) [0.0|18446744073709551615] ""  Vector__XXX

BO_ 2617023232 DEV_BedienSG_hi_Resp_00: 8 BedienSG_hi
 SG_ DEV_BedienSG_hi_Resp_00_Data : 0|64@1+ (1.0,0.0) [0.0|18446744073709551615] ""  Vector__XXX

BO_ 2617023487 DEV_BedienSG_hi_Resp_FF: 8 BedienSG_hi
 SG_ DEV_BedienSG_hi_Resp_FF_Data : 0|64@1+ (1.0,0.0) [0.0|18446744073709551615] ""  Vector__XXX

BO_ 2617103104 DEV_DDA_Req_00: 8 Vector__XXX
 SG_ DEV_DDA_Req_00_Data : 0|64@1+ (1.0,0.0) [0.0|18446744073709551615] ""  DDA

BO_ 2617103359 DEV_DDA_Resp_FF: 8 DDA
 SG_ DEV_DDA_Resp_FF_Data : 0|64@1+ (1.0,0.0) [0.0|18446744073709551615] ""  Vector__XXX

BO_ 2617219613 DEV_ZR_Produktion_1_Rx_1D: 8 Vector__XXX
 SG_ DEV_ZR_Produktion_1_Rx_1D_Data : 0|64@1+ (1,0) [0|1] ""  ZR_High,ZR_MIB_TOP_ab_Gen3,ZR_Standard

BO_ 2617219612 DEV_ZR_Produktion_1_Tx_1C: 8 ZR_High
 SG_ DEV_ZR_Produktion_1_Tx_1C_Data : 0|64@1+ (1,0) [0|1] ""  Vector__XXX

BO_ 2617219597 DEV_ZR_Req_0D: 8 Vector__XXX
 SG_ DEV_ZR_Req_0D_Data : 0|64@1+ (1,0) [0|1] ""  ZR_High,ZR_MIB_TOP_ab_Gen3,ZR_Standard

BO_ 2617219584 DEV_ZR_Resp_00: 8 ZR_High
 SG_ DEV_ZR_Resp_00_Data : 0|64@1+ (1,0) [0|1] ""  Vector__XXX

BO_ 2617219614 DEV_ZR_Rx_1E: 8 Vector__XXX
 SG_ DEV_ZR_Pwm_Debug_1 : 0|1@1+ (1.0,0.0) [0.0|1] ""  ZR_High,ZR_MIB_TOP_ab_Gen3,ZR_Standard
 SG_ DEV_ZR_Pwm_Debug_2 : 1|1@1+ (1.0,0.0) [0.0|1] ""  ZR_High,ZR_MIB_TOP_ab_Gen3,ZR_Standard
 SG_ DEV_ZR_Pwm_Debug_3 : 2|1@1+ (1.0,0.0) [0.0|1] ""  ZR_High,ZR_MIB_TOP_ab_Gen3,ZR_Standard
 SG_ DEV_ZR_Pwm_Debug_4 : 3|1@1+ (1.0,0.0) [0.0|1] ""  ZR_High,ZR_MIB_TOP_ab_Gen3,ZR_Standard

BO_ 2617219604 DEV_ZR_Tx_14: 8 ZR_High
 SG_ DEV_ZR_Tx_14_Data : 0|64@1+ (1,0) [0|1] ""  Vector__XXX

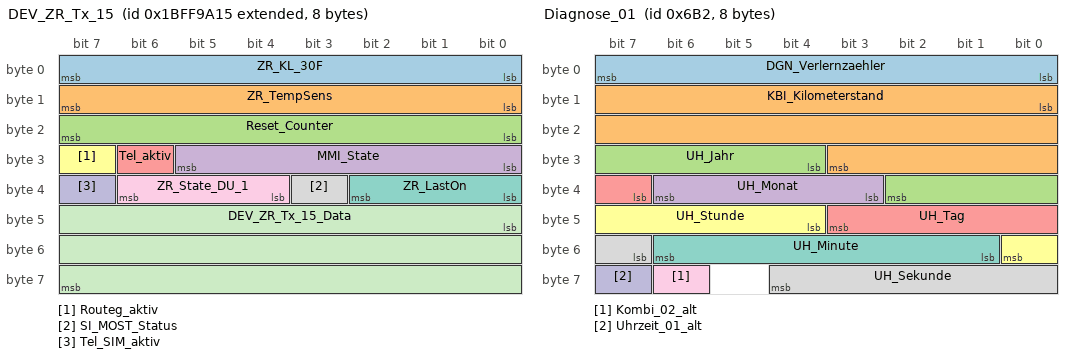
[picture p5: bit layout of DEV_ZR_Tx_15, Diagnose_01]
BO_ 2617219605 DEV_ZR_Tx_15: 8 ZR_High
 SG_ ZR_KL_30F : 0|8@1+ (0.1,0) [0.0|25.3] "Unit_Volt"  Vector__XXX
 SG_ ZR_TempSens : 8|8@1+ (1,-55) [-55|127] "Unit_DegreCelsi"  Vector__XXX
 SG_ Reset_Counter : 16|8@1+ (1,0) [0|253] ""  Vector__XXX
 SG_ MMI_State : 24|6@1+ (1.0,0.0) [0.0|63] ""  Vector__XXX
 SG_ Tel_aktiv : 30|1@1+ (1.0,0.0) [0.0|1] ""  Vector__XXX
 SG_ Routeg_aktiv : 31|1@1+ (1.0,0.0) [0.0|1] ""  Vector__XXX
 SG_ ZR_LastOn : 32|3@1+ (1,0) [0|6] ""  Vector__XXX
 SG_ SI_MOST_Status : 35|1@1+ (1.0,0.0) [0.0|1] ""  Vector__XXX
 SG_ ZR_State_DU_1 : 36|3@1+ (1.0,0.0) [0.0|7] ""  Vector__XXX
 SG_ Tel_SIM_aktiv : 39|1@1+ (1.0,0.0) [0.0|1] ""  Vector__XXX
 SG_ DEV_ZR_Tx_15_Data : 40|24@1+ (1,0) [0|1] ""  Vector__XXX

BO_ 2549880610 DIA_SCON1_Req: 8 Gateway
 SG_ DIA_SCON1_Req_Data : 0|64@1+ (1.0,0.0) [0.0|18446744073709551615] ""  ZR_High,ZR_MIB_TOP_ab_Gen3

BO_ 2550011682 DIA_SCON1_Resp: 8 ZR_High
 SG_ DIA_SCON1_Resp_Data : 0|64@1+ (1.0,0.0) [0.0|18446744073709551615] ""  Gateway,Gateway_PAG

BO_ 2549880611 DIA_SCON2_Req: 8 Gateway
 SG_ DIA_SCON2_Req_Data : 0|64@1+ (1.0,0.0) [0.0|18446744073709551615] ""  ZR_High,ZR_MIB_TOP_ab_Gen3

BO_ 2550011683 DIA_SCON2_Resp: 8 ZR_High
 SG_ DIA_SCON2_Resp_Data : 0|64@1+ (1.0,0.0) [0.0|18446744073709551615] ""  Gateway,Gateway_PAG

BO_ 2549880473 DIA_SD3_Req: 8 Gateway
 SG_ DIA_SD3_Req_Data : 0|64@1+ (1.0,0.0) [0.0|18446744073709551615] ""  ZR_High,ZR_MIB_TOP_ab_Gen3

BO_ 2550011545 DIA_SD3_Resp: 8 ZR_High
 SG_ DIA_SD3_Resp_Data : 0|64@1+ (1.0,0.0) [0.0|18446744073709551615] ""  Gateway,Gateway_PAG

BO_ 2549880474 DIA_SD4_Req: 8 Gateway
 SG_ DIA_SD4_Req_Data : 0|64@1+ (1.0,0.0) [0.0|18446744073709551615] ""  ZR_High,ZR_MIB_TOP_ab_Gen3

BO_ 2550011546 DIA_SD4_Resp: 8 ZR_High
 SG_ DIA_SD4_Resp_Data : 0|64@1+ (1.0,0.0) [0.0|18446744073709551615] ""  Gateway,Gateway_PAG

BO_ 1714 Diagnose_01: 8 Gateway
 SG_ DGN_Verlernzaehler : 0|8@1+ (1,0) [0|254] ""  BedienDisp_vo,BedienSG_hi,DDA,GurtMikrofon,OTA_FC,ZR_High,ZR_LIMU,ZR_MIB_TOP_ab_Gen3,ZR_Standard
 SG_ KBI_Kilometerstand : 8|20@1+ (1,0) [0|1048573] "Unit_KiloMeter"  BedienDisp_vo,BedienSG_hi,DDA,GurtMikrofon,OTA_FC,ZR_High,ZR_LIMU,ZR_MIB_TOP_ab_Gen3,ZR_Standard
 SG_ UH_Jahr : 28|7@1+ (1,2000) [2000|2127] "Unit_Year"  BedienDisp_vo,BedienSG_hi,DDA,GurtMikrofon,OTA_FC,ZR_High,ZR_LIMU,ZR_MIB_TOP_ab_Gen3,ZR_Standard
 SG_ UH_Monat : 35|4@1+ (1,0) [1|12] "Unit_Month"  BedienDisp_vo,BedienSG_hi,DDA,GurtMikrofon,OTA_FC,ZR_High,ZR_LIMU,ZR_MIB_TOP_ab_Gen3,ZR_Standard
 SG_ UH_Tag : 39|5@1+ (1,0) [1|31] "Unit_Day"  BedienDisp_vo,BedienSG_hi,DDA,GurtMikrofon,OTA_FC,ZR_High,ZR_LIMU,ZR_MIB_TOP_ab_Gen3,ZR_Standard
 SG_ UH_Stunde : 44|5@1+ (1,0) [0|23] "Unit_Hours"  BedienDisp_vo,BedienSG_hi,DDA,GurtMikrofon,OTA_FC,ZR_High,ZR_LIMU,ZR_MIB_TOP_ab_Gen3,ZR_Standard
 SG_ UH_Minute : 49|6@1+ (1,0) [0|59] "Unit_Minut"  BedienDisp_vo,BedienSG_hi,DDA,GurtMikrofon,OTA_FC,ZR_High,ZR_LIMU,ZR_MIB_TOP_ab_Gen3,ZR_Standard
 SG_ UH_Sekunde : 55|6@1+ (1,0) [0|59] "Unit_Secon"  BedienDisp_vo,BedienSG_hi,DDA,GurtMikrofon,OTA_FC,ZR_High,ZR_LIMU,ZR_MIB_TOP_ab_Gen3,ZR_Standard
 SG_ Kombi_02_alt : 62|1@1+ (1.0,0.0) [0.0|1] ""  OTA_FC,ZR_High,ZR_LIMU,ZR_MIB_TOP_ab_Gen3
 SG_ Uhrzeit_01_alt : 63|1@1+ (1.0,0.0) [0.0|1] ""  BedienDisp_vo,OTA_FC,ZR_High,ZR_LIMU,ZR_MIB_TOP_ab_Gen3

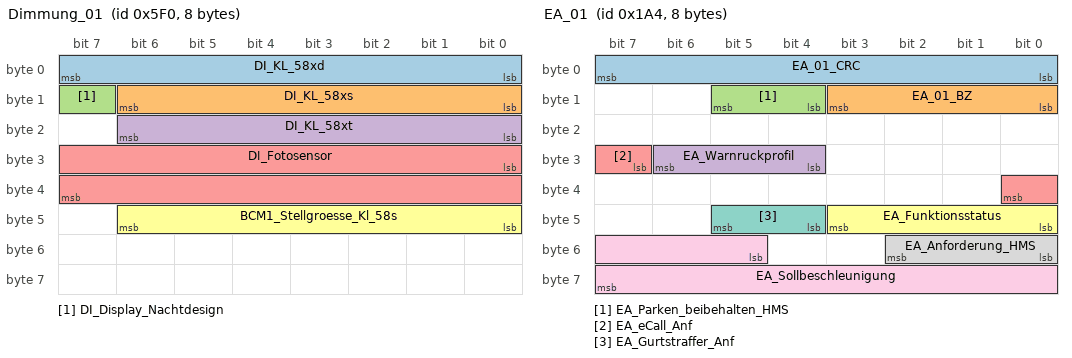
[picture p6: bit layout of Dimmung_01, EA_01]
BO_ 1520 Dimmung_01: 8 Gateway
 SG_ DI_KL_58xd : 0|8@1+ (1,0) [0|253] ""  BedienDisp_vo,BedienSG_hi,OTA_FC,ZR_High,ZR_LIMU,ZR_MIB_TOP_ab_Gen3,ZR_Standard
 SG_ DI_KL_58xs : 8|7@1+ (1,0) [0|100] "Unit_PerCent"  BedienDisp_vo,BedienSG_hi,ZR_High,ZR_LIMU,ZR_MIB_TOP_ab_Gen3,ZR_Standard
 SG_ DI_Display_Nachtdesign : 15|1@1+ (1.0,0.0) [0.0|1] ""  BedienSG_hi,ZR_High,ZR_LIMU,ZR_MIB_TOP_ab_Gen3,ZR_Standard
 SG_ DI_KL_58xt : 16|7@1+ (1,0) [0|100] "Unit_PerCent"  BedienDisp_vo,BedienSG_hi,ZR_High,ZR_LIMU,ZR_MIB_TOP_ab_Gen3,ZR_Standard
 SG_ DI_Fotosensor : 24|16@1+ (1,0) [0|65535] ""  BedienSG_hi,ZR_High,ZR_LIMU,ZR_MIB_TOP_ab_Gen3,ZR_Standard
 SG_ BCM1_Stellgroesse_Kl_58s : 40|7@1+ (1,0) [0|100] ""  ZR_High,ZR_LIMU,ZR_MIB_TOP_ab_Gen3,ZR_Standard

BO_ 420 EA_01: 8 Gateway
 SG_ EA_01_CRC : 0|8@1+ (1,0) [0|255] ""  Vector__XXX
 SG_ EA_01_BZ : 8|4@1+ (1,0) [0|15] ""  Vector__XXX
 SG_ EA_Parken_beibehalten_HMS : 12|2@1+ (1.0,0.0) [0.0|3] ""  Vector__XXX
 SG_ EA_Warnruckprofil : 28|3@1+ (1.0,0.0) [0.0|7] ""  Vector__XXX
 SG_ EA_eCall_Anf : 31|2@1+ (1.0,0.0) [0.0|3] ""  ZR_High
 SG_ EA_Funktionsstatus : 40|4@1+ (1.0,0.0) [0.0|15] ""  ZR_High
 SG_ EA_Gurtstraffer_Anf : 44|2@1+ (1.0,0.0) [0.0|3] ""  Vector__XXX
 SG_ EA_Anforderung_HMS : 48|3@1+ (1.0,0.0) [0.0|7] ""  Vector__XXX
 SG_ EA_Sollbeschleunigung : 53|11@1+ (0.005,-7.22) [-7.220|3.005] "Unit_MeterPerSeconSquar"  Vector__XXX

BO_TX_BU_ 1626 :Gateway,Gateway_PAG;
BO_TX_BU_ 672 :Gateway,Gateway_PAG;
BO_TX_BU_ 2463978607 :Gateway,Gateway_PAG;
BO_TX_BU_ 2589283629 :Gateway,Gateway_PAG;
BO_TX_BU_ 1448 :Gateway,Gateway_PAG;
BO_TX_BU_ 961 :Gateway,Gateway_PAG;
BO_TX_BU_ 1432 :Gateway,Gateway_PAG;
BO_TX_BU_ 1462 :BedienDisp_vo,BedienSG_hi;
BO_TX_BU_ 870 :Gateway,Gateway_PAG;
BO_TX_BU_ 401 :Gateway,Gateway_PAG;
BO_TX_BU_ 1482 :Gateway,Gateway_PAG;
BO_TX_BU_ 1111 :Gateway,Gateway_PAG;
BO_TX_BU_ 823 :Gateway,Gateway_PAG;
BO_TX_BU_ 824 :Gateway,Gateway_PAG;
BO_TX_BU_ 825 :Gateway,Gateway_PAG;
BO_TX_BU_ 902 :Gateway,Gateway_PAG;
BO_TX_BU_ 615 :Gateway,Gateway_PAG;
BO_TX_BU_ 2617219612 :ZR_High,ZR_MIB_TOP_ab_Gen3,ZR_Standard;
BO_TX_BU_ 2617219584 :ZR_High,ZR_MIB_TOP_ab_Gen3,ZR_Standard;
BO_TX_BU_ 2617219604 :ZR_High,ZR_MIB_TOP_ab_Gen3,ZR_Standard;
BO_TX_BU_ 2617219605 :ZR_High,ZR_MIB_TOP_ab_Gen3,ZR_Standard;
BO_TX_BU_ 2549880610 :Gateway,Gateway_PAG;
BO_TX_BU_ 2550011682 :ZR_High,ZR_MIB_TOP_ab_Gen3;
BO_TX_BU_ 2549880611 :Gateway,Gateway_PAG;
BO_TX_BU_ 2550011683 :ZR_High,ZR_MIB_TOP_ab_Gen3;
BO_TX_BU_ 2549880473 :Gateway,Gateway_PAG;
BO_TX_BU_ 2550011545 :ZR_High,ZR_MIB_TOP_ab_Gen3;
BO_TX_BU_ 2549880474 :Gateway,Gateway_PAG;
BO_TX_BU_ 2550011546 :ZR_High,ZR_MIB_TOP_ab_Gen3;
BO_TX_BU_ 1714 :Gateway,Gateway_PAG;
BO_TX_BU_ 1520 :Gateway,Gateway_PAG;
BO_TX_BU_ 420 :Gateway,Gateway_PAG;
CM_ BO_ 870 "Nur die Kombination des statischen und toggelnden Signals ergibt den Blinktakt für die Hell & Dunkelphase";
CM_ BO_ 901 "ab MQB ohne CHK und mit geänderter Sendeart";
CM_ BO_ 902 "ab MQB 7.2.1";
CM_ BO_ 2549880610 "Drahtloses Bedienteil 1 für Multimediasystem Request Channel";
CM_ BO_ 2550011682 "Drahtloses Bedienteil 1 für Multimediasystem Response Channel";
CM_ BO_ 2549880611 "Drahtloses Bedienteil 2 für Multimediasystem Request Channel";
CM_ BO_ 2550011683 "Drahtloses Bedienteil 2 für Multimediasystem Response Channel";
CM_ BO_ 2549880473 "Anzeingeeinheit 3 für Multimediasystem Request Channel";
CM_ BO_ 2550011545 "Anzeingeeinheit 3 für Multimediasystem Response Channel";
CM_ BO_ 2549880474 "Anzeingeeinheit 4 für Multimediasystem Request Channel";
CM_ BO_ 2550011546 "Anzeingeeinheit 4 für Multimediasystem Response Channel";
CM_ BO_ 1520 "ab MQB nach abgestimmten FLH Dimmung";

CM_ SG_ 1626 APS_Tongeber_defekt "Status APS-Tongeber zur HMI-Ansteuerng der RCTA-Funktion";
CM_ SG_ 1626 BCM1_AFS_Lampe "Ansteuerung der AFS-Fehlermeldung im Kombi";
CM_ SG_ 1626 BCM1_EasyEntry_Status "Status EasyEntry für Lenksäule (wird auch von IVB verwendet)";
CM_ SG_ 1626 BCM1_Fahrlicht_Hinweis "Signal zum Kombi um den Hinweis 'Bitte Fahrlicht einschalten' anzufordern";
CM_ SG_ 1626 BCM1_Hinweis_Lichtnachlauf "Signal dient der Anzeige eines aktiven Lichtnachlaufes beim automatischen Abschalten der Klemme S und Klemme 15. Der Lichtnachlauf wird gestartet, wenn die Klemme 15 bei aktivem Fahrlicht deaktiviert wird.";
CM_ SG_ 1626 BCM1_Kl_15_HW_erkannt "Erkennung Klemme 15 (Hardware) vom BCM1
";
CM_ SG_ 1626 BCM1_Kl_15_Sig_HW_erkannt "Erkennung Klemme 15 Signal (Hardware) vom BCM1";
CM_ SG_ 1626 BCM1_LDS_Stellung "Das Signal wird vom AFS / LWR Steuergerät empfangen und dient der Verifizierung der Lichtdrehschalterstellung. Intelligente Lichtfunktionen wie dyn. KL und gleitende Leuchtweite (GLW) nur bei LDS = 'AUTO'.";
CM_ SG_ 1626 BCM1_Lenksaeule_aktiv "Lenksaeulenverstellung aktiv";
CM_ SG_ 1626 BCM1_Licht_Warn "Lichtwarnung";
CM_ SG_ 1626 BCM1_Lichtwarn_Texte "Anforderung von Lichtwarnungen vom BCM1 zum Kombi
MLB: nur Werte 0..2";
CM_ SG_ 1626 BCM1_MH_Schalter "Motorhaubenkontakt";
CM_ SG_ 1626 BCM1_MH_WIV_Schalter "Bewerteter Motorhaubenkontakt fuer WIV";
CM_ SG_ 1626 BCM1_NV_Taster "BCM1_NV_Taster gibt an, ob der NightVision-Taster im Lichtdrehschalter-Modul aktuell betaetigt wird.";
CM_ SG_ 1626 BCM1_Reisemodus_Texte "Ansteuerung der Reisemodus-Texte im Kombi";
CM_ SG_ 1626 BCM1_Rueckfahrlicht_Schalter "Rückfahrlichtschalter
ab MQB/ MLBevo: Die Ganginformation wird unentprellt übertragen, im AT-Getriebe wird evtl. kurzzeitig der R-Gang angezeigt. Eine Entprellung muß im Empfänger erfolgen (typisch 400ms).";
CM_ SG_ 1626 BCM1_Schluesselsuche_Anf "Anforderung von BCM1 an BCM2:
Schlüsselpolling aktivieren

Nötig bei z.B. aktiviertem Annäherungslicht";
CM_ SG_ 1626 BCM1_St_SW_Diebstahl_links "Signal zur Anzeige, dass der linke Scheinwerfer gestohlen wurde";
CM_ SG_ 1626 BCM1_St_SW_Diebstahl_rechts "Signal zur Anzeige, dass der rechte Scheinwerfer gestohlen wurde";
CM_ SG_ 1626 BCM1_Valet_Parking_Taster "Valet Parking Taster ";
CM_ SG_ 1626 BCM1_Warnblink_Taster "Warnblinktaster";
CM_ SG_ 1626 BCM_Bremsbelag_Sensor "Sensorsignal der Stromschleife  für Bremsbelagverschleiß aktuell, entstört, unbewertet";
CM_ SG_ 1626 BCM_Bremsfluessigkeit_Sensor "Kontaktsignal des Sensorschalters für die Bremsflüssigkeitsreserve aktuell, entstört, unbewertet";
CM_ SG_ 1626 BCM_Eco_Charisma_Taste "Betätigung Taster ECO alias BlueKey oder Charisma";
CM_ SG_ 1626 BCM_HDF_betaetigt "Betätigung Taster für Heckdeckelfernentriegelung in Mittelkonsole";
CM_ SG_ 1626 BCM_Hybrid_StartStopp_Taste "Betaetigung Taster 'Hybrid' oder alternativ Taster 'Start/Stopp Deaktivierung', je nach Verbau";
CM_ SG_ 1626 BCM_Hybrid_StSt_Taste_Fehler "Fehlerflag, wenn Tasterdiagnose im BCM für den StSt-Taster anschlägt.";
CM_ SG_ 1626 BCM_Kuehlmittel_Sensor "Signal der Sensorelektroden für die Kühlmittelreserve aktuell, entstört, bewertet (OK/Mangel)";
CM_ SG_ 1626 BCM_Kuehlmittel_Sensor_02 "Signal der zweiten Sensorelektroden für die Kühlmittelreserve aktuell, entstört, bewertet (OK/Mangel)";
CM_ SG_ 1626 BCM_Offroad_Taste "Betätigung der Offroad-Taste";
CM_ SG_ 1626 BCM_Waschwasser_Sensor "Signal der Sensorelektroden für die Waschwasserreserve aktuell, entstört, bewertet (OK/Mangel)";
CM_ SG_ 1626 Gong_TFL_Umschaltung "Aktivierung / Deaktivierung des TFL per Affengriff wird mit einem Gong im Kombi quittiert.";
CM_ SG_ 1626 ISP_Dimmung_ASP_02 "Dimmwertvorgabe für Aussenspiegel
Es wird 1:1 die Spannung am Innenspiegel nach außen übertragen.";
CM_ SG_ 1626 UGDO_Function_01 "UGDO_Sender = LIN-Slave BCM1
bei Kl.15 AUS wird für 4s noch der letzte Wert gesendet, danach wird der Wert 7 (= Fehler gesendet)";

CM_ SG_ 672 BCM2_Crashfall_erkannt "Crasherkennung BCM2";
CM_ SG_ 672 BCM2_Freigabe_Kofferr_Innenentr "Freigabe Kofferraum-Innenentriegelung (TrunkEntrapment)

Das iEZS prüft als 2. Instanz die Geschwindigkeit und kann die Ansteuerung der Sekundärverriegelung freigeben (FUSI-Anforderungen).
Das Signal muss über eine E2E-Absicherung verfügen.";
CM_ SG_ 672 BCM2_KL15_Absch_FT "Signalisierung, dass die KL15 über das Verlassen des Fahrzeuges deaktiviert wurde (über Fahrertürtrigger).";
CM_ SG_ 672 BCM2_P_verriegelt "Nicht plausibilisiertes Rohsignal des P-Verriegeltschalters vom Wählhebel zur exklusiven Nutzung für Getriebesteuergeräte:
";
CM_ SG_ 672 BCM2_Quittierung_Warnton_aktiv "Quittierungs-/Warnton Sounder/Einfachhorn aktiv

Info:
- Ausgelöst durch akustische Rückmeldung der Zentralverriegelung
- Aussenwarnung KlSt
- Akustische Rückmeldung bei offenem Alarmkontakt 
- etc.";
CM_ SG_ 672 BCM2_SST_gedrueckt "Betätigung Start-Stop-Taster (Kessy-Fahrzeug)";
CM_ SG_ 672 BCM2_T_Deckel_Vorne "Taster Deckel vorne betätigt";
CM_ SG_ 672 BCM2_TrunkEntrapment_Warn "Das Signal triggert eine Warnmeldung im Kombi zur Anzeige von diagnostizierten schleichenden Fehlern an den Aktoren oder Sensoren von TrunkEntrapment.";
CM_ SG_ 672 BCM2_Unterdr_Zuendungsmeldung "Bei aktivem Signal soll die Zündungsmeldung durch das Kombi unterdrückt werden.";
CM_ SG_ 672 BCM_02_BZ "4bit Botschaftszaehler; wird in jeder Sendebotschaft inkrementiert";
CM_ SG_ 672 BCM_02_CRC "Für MLB:
'Berechnung siehe Lastenheft 'Kommunikationsabsicherung für FlexRay und CAN''

Ab MQB und MLBevo:
'Berechnung siehe Lastenheft 'End-to-End Kommunikationsabsicherung''

Endwerte siehe Begleitdokument 'S-PDU Kennungsfolgen'
";
CM_ SG_ 672 BCM_Anf_Aussenwarnung "Anforderung einer akustischen Aussenwarnung über Hupe an das BCM1";
CM_ SG_ 672 BCM_Aussenwarnung_Konfig "Konfigurationsbyte für die Aussenwarnung
0: Anforderungssignal wird 1:1 übernommen
1..6: Anzahl der Warntöne
7: Sequenz des BCM1 wird solange wiederholt, wie das Anforderungssignal ansteht ";
CM_ SG_ 672 BCM_Handbremse_Hinweis "Infotext fuer das Kombiinstrument zur Oeffnung der elektr. Heckklappe.";
CM_ SG_ 672 BCM_RLU_Wakeup_Anforderung "Anforderung an MIB das Telefonmodul zu aktivieren. Funktion Remote Lock Unlock";
CM_ SG_ 672 BCM_ValetTaster_Fkts_LED "Im MQB beschreibt das Signal nur den Zustand der Funktion Valet Parking (aktiv/ inaktiv)
Im MLBevo wird über das Signal zusätzlich die ValetTaster_Fkts_LED (an/ aus) gesteuert";
CM_ SG_ 672 BCM_Waehlhebel_P_Hinweis "Infotext NAR für die Vorbedingung 'Waehlhebel in P' für Öffnen der Heckklappe über den Fahrerrauminnentaster.";
CM_ SG_ 672 FA_Hoehenwert_HL_01 "Aktueller Höhenwert (Rohwerte) Hinten Links; ungefiltertes Signal
Einheit, Offset und Faktor sind abhänig von 'FA_Hoehenwert_kalibriert'";
CM_ SG_ 672 FA_Hoehenwert_VL_01 "Aktueller Höhenwert (Rohwerte) Vorne Links; ungefiltertes Signal
Einheit, Offset und Faktor sind abhänig von 'FA_Hoehenwert_kalibriert'";
CM_ SG_ 672 FSH_LED "LED Ansteuerung Frontscheibenheizung";
CM_ SG_ 672 Heckrollo_Privacy_aktiv "Anzeige einer aktivierten  Privacy Rollo Funktion";
CM_ SG_ 672 Heckrollo_Verfahrrichtung "Anzeige der aktuellen Heckrolloverfahrrichtung oder der erreichten Endlage.";
CM_ SG_ 672 Heckwischer_Status "Diagnosestatus des Heckwischerausgangs";
CM_ SG_ 672 HSH_LED "LED Ansteuerung Heckscheibenheizung";
CM_ SG_ 672 Niveausensor_HL_verbaut "Signal wird gesetzt, wenn Niveausensor_hinten codiert wird.";
CM_ SG_ 672 Niveausensor_VL_verbaut "Signal wird gesetzt, wenn Niveausensor_vorne codiert wird.";
CM_ SG_ 672 Remote_Rollo_HBFS_hoch "Anforderung für Seitenrollo HBFS in Richtung hoch zu verfahren";
CM_ SG_ 672 Remote_Rollo_HBFS_tief "Anforderung für Seitenrollo HBFS in Richtung tief zu verfahren";
CM_ SG_ 672 Remote_Rollo_HFS_hoch "Anforderung für Seitenrollo HFS in Richtung hoch zu verfahren";
CM_ SG_ 672 Remote_Rollo_HFS_tief "Anforderung für Seitenrollo HFS in Richtung tief zu verfahren";
CM_ SG_ 672 ZZH_Endlage_oben "obere Endlagenerkennung ZZH
";
CM_ SG_ 672 ZZH_Endlage_unplausibel "Erkennungung unplausible Endlage ZZH
";
CM_ SG_ 672 ZZH_Endlage_unten "untere Endlagenerkennung ZZH
";

CM_ SG_ 2463978607 BCM_RGB_Blau "Farbanteil 'Blau'";
CM_ SG_ 2463978607 BCM_RGB_Gruen "Farbanteil 'Grün'";
CM_ SG_ 2463978607 BCM_RGB_Rot "Farbanteil 'Rot'";

CM_ SG_ 2589283629 BCM_DC_Batterie_Status "Batteriestatus des Drivercard Schlüssels";
CM_ SG_ 2589283629 BCM_DC_erkannt "Rückmeldung gefundene Drivercard ID";
CM_ SG_ 2589283629 BCM_DC_ID "Rückmeldung einer gefundenen Drivercard (Transponder ID)
gekoppelt
BCM_St_Suche_Drivercard_ID
";
CM_ SG_ 2589283629 BCM_DC_Suchvorgang_Status "Rückmeldung Status/Fehlerfall für Drivercardsuche";

CM_ SG_ 1448 BCM1_FlHz_BFS_PWM_A "Flächenheizung: Leistungsvorgabe
0-100: PWM in Prozent (spannungskompensiert)
101: 100 % PWM nicht spannungskompensiert
";
CM_ SG_ 1448 BCM1_FlHz_BFS_PWM_B "Flächenheizung: Leistungsvorgabe
0-100: PWM in Prozent (spannungskompensiert)
101: 100 % PWM nicht spannungskompensiert
";
CM_ SG_ 1448 BCM1_FlHz_HBFS_PWM_A "Flächenheizung: Leistungsvorgabe
0-100: PWM in Prozent (spannungskompensiert)
101: 100 % PWM nicht spannungskompensiert
";
CM_ SG_ 1448 BCM1_FlHz_HBFS_PWM_B "Flächenheizung: Leistungsvorgabe
0-100: PWM in Prozent (spannungskompensiert)
101: 100 % PWM nicht spannungskompensiert
";
CM_ SG_ 1448 BCM1_FlHz_HL_HLR_Anf "Anforderung eines prozentualen Leistungskontingents für die Flächenheizung hinten links";
CM_ SG_ 1448 BCM1_FlHz_HR_HLR_Anf "Anforderung eines prozentualen Leistungskontingents für die Flächenheizung hinten rechts";
CM_ SG_ 1448 BCM1_FlHz_Ruhesitz_HLR_Anf "Anforderung eines prozentualen Leistungskontingents für die Flächenheizung des Ruhesitz";
CM_ SG_ 1448 BCM1_FlHz_Stufe_HL "Statusmeldung Flächenheizung hinten links";
CM_ SG_ 1448 BCM1_FlHz_Stufe_HR "Statusmeldung Flächenheizung hinten rechts";
CM_ SG_ 1448 BCM1_FlHz_Stufe_VL "Statusmeldung Flächenheizung vorne links";
CM_ SG_ 1448 BCM1_FlHz_Stufe_VR "Statusmeldung Flächenheizung vorne rechts";
CM_ SG_ 1448 BCM1_FlHz_VL_HLR_Anf "Anforderung eines prozentualen Leistungskontingents für die Flächenheizung vorne links";
CM_ SG_ 1448 BCM1_FlHz_VR_HLR_Anf "Anforderung eines prozentualen Leistungskontingents für die Flächenheizung vorne rechts";

CM_ SG_ 961 APS_LED_Status "Das Signal beschreibt den Zustand der APS LED für die Einparkhilfe, die im MLBevo vom BCM1 oder LIN Schalterleiste (BCM1 Slave) angesteuert wird.";
CM_ SG_ 961 APS_Taster "Das Signal beschreibt den Zustand der Taste, die im MLBevo vom BCM1 eingelesen wird.";
CM_ SG_ 961 AVH_LED_Status "Das Signal beschreibt den Zustand der AVH LED, die im MLBevo vom BCM1 oder LIN Schalterleiste (BCM1 Slave) angesteuert wird.
";
CM_ SG_ 961 AVH_Taster "Das Signal beschreibt den Zustand der AVH Taste, die im MLBevo vom BCM1 eingelesen wird.
";
CM_ SG_ 961 Display_Taster "Taster für Display Klappung";
CM_ SG_ 961 Drivesel_1_Taster "Taster 1 für Drive Select Betätigung";
CM_ SG_ 961 Drivesel_2_Taster "Taster 2 für Drive Select Betätigung";
CM_ SG_ 961 eCall_Taste "Status der eCall-Taste. 
(Emergency Call / SOS Hilferuf)";
CM_ SG_ 961 ESP_Off_Taster "Das Signal beschreibt den Zustand der ESP Taste, die im MLBevo vom BCM1 eingelesen wird.
";
CM_ SG_ 961 HDC_LED_Status "Das Signal beschreibt den Zustand der HDC LED, die im MLBevo vom BCM1 oder LIN Schalterleiste (BCM1 Slave) angesteuert wird.	";
CM_ SG_ 961 HDC_Taster "Das Signal beschreibt den Zustand der HDC Taste, die im MLBevo vom BCM1 eingelesen wird
0 = Taste nicht betätigt
1 = Taste entprellt betätigt
2 = Init oder Taste nicht verbaut
3 = Fehler";
CM_ SG_ 961 Heckrollo_2_Taster "Taster 2 für Heckrollo Betätigung";
CM_ SG_ 961 Heckrollo_Taster "Taster für Heckrollo Betätigung";
CM_ SG_ 961 LIM_bCall_Taster "Statusinformation des Service Call Tasters im Dachmodul";
CM_ SG_ 961 LIM_PAO_Alivesignal "Alive-Information zur Absicherung von Timeouterkennung bei Routing über mehrere Bussegmente";
CM_ SG_ 961 LIM_PAO_OFF_Status "Istwert für LED 'OFF' in Anzeige Passenger Airbag On/Off";
CM_ SG_ 961 LIM_PAO_ON_Status "Istwert für LED 'ON' in Anzeige Passenger Airbag On/Off";
CM_ SG_ 961 LIM_PAO_Schriftzug_Status "Istwert für LED 'PASSENGER AIRBAG' in Anzeige Passenger Airbag On/Off";
CM_ SG_ 961 LKS_Taster "Taste zum de-/aktivieren der Funktion LKS (Lane Keeping System)

0 - Taste nicht betätigt
1 - Taste betätigt
2 - INIT oder Taste nicht verbaut
3 - Fehler (Timeout, hängender Taster)";
CM_ SG_ 961 PLA_LED_Status "Das Signal beschreibt den Zustand der PLA LED, die im MLBevo vom BCM1 oder LIN Schalterleiste (BCM1 Slave) angesteuert wird.";
CM_ SG_ 961 PLA_Taster "Das Signal beschreibt den Zustand der PLA (Parklenkassisten) Taste, die im MLBevo vom BCM1 eingelesen wird.";
CM_ SG_ 961 PLA_Taster_Fehler_Roh "PLA Taster Fehlerstatus als ungefiltertes Signal für eine schnelle Fehlererkennung und Verarbeitung im IPA";
CM_ SG_ 961 Sideview_Taster "Taster für SIDEVIEW Betätigung";
CM_ SG_ 961 Spoiler_LED_Status "Status der Funktions LED SPOILER Ein/Ausfahren.";
CM_ SG_ 961 Spoiler_Taster "Taster für SPOILER Betätigung";
CM_ SG_ 961 SWA_Taster "SWA Taster vom BCM1 (quelle LDS)";

CM_ SG_ 1432 BCM1_eSound_Taster "Das Signal beschreibt den Zustand der eSound Taste, die im MLBevo vom BCM1 eingelesen wird
0 = Taste nicht betätigt
1 = Taste entprellt betätigt
2 = Init oder Taste nicht verbaut
3 = Fehler";
CM_ SG_ 1432 BCM1_NR_Ride_Height_Down_Taster "Tastersignal zum Absenken des Fahrzeugs bei höhenverstellbaren Fahrzeugen (Taster/Bedieneinheit an Schalterleiste 2  BCM1)
";
CM_ SG_ 1432 BCM1_NR_Ride_Height_Up_Taster "Tastersignal zum Anheben des Fahrzeugs bei höhenverstellbaren Fahrzeugen (Taster/Bedieneinheit an Schalterleiste 2  BCM1";
CM_ SG_ 1432 BCM_BFS_Fernsteuerung_aktiv "Fernsteuerung BFS aktiv";
CM_ SG_ 1432 BCM_BFS_Massage_Taster "Ansteuerungs-Signalisierung der Pneumatik-Funktionen";
CM_ SG_ 1432 BCM_BFS_Multif_Taster "Ansteuerungs-Signalisierung der Pneumatik-Funktionen";
CM_ SG_ 1432 BCM_BFS_Pneumatik_Verstellung "Ansteuerungs-Signalisierung der Pneumatik-Funktionen";
CM_ SG_ 1432 BCM_BFS_Programmwippe "Ansteuerungs-Signalisierung der Pneumatik-Funktionen";
CM_ SG_ 1432 BCM_FS_Massage_Taster "Ansteuerungs-Signalisierung der Pneumatik-Funktionen";
CM_ SG_ 1432 BCM_FS_Multif_Taster "Ansteuerungs-Signalisierung der Pneumatik-Funktionen";
CM_ SG_ 1432 BCM_FS_Pneumatik_Verstellung "Ansteuerungs-Signalisierung der Pneumatik-Funktionen";
CM_ SG_ 1432 BCM_FS_Programmwippe "Ansteuerungs-Signalisierung der Pneumatik-Funktionen";
CM_ SG_ 1432 BCM_Soundklappe_Taster "Status Soundklappe Taste";
CM_ SG_ 1432 E_Sound_LED_Status "Das Signal beschreibt den Zustand der eSound LED, die im MLBevo vom BCM1 oder LIN Schalterleiste (BCM1 Slave) angesteuert wird.";
CM_ SG_ 1432 LIM_S_Rollo_hi "Schalterfeld LIM für Sonnenrolle Schiebedach hinten";
CM_ SG_ 1432 LIM_S_Rollo_vo "Schalterfeld LIM für Sonnenrolle Schiebedach vorne";
CM_ SG_ 1432 LIM_S_SAD_hi "Schalterfeld LIM für SAD hinten";
CM_ SG_ 1432 LIM_S_SAD_Vo "Schalterfeld LIM für SAD vorne";
CM_ SG_ 1432 Pilot_Taster "Das Signal beschreibt den Zustand der Pilot Taste, die im MLBevo vom BCM1 eingelesen wird
0 = Taste nicht betätigt
1 = Taste entprellt betätigt
2 = Init oder Taste nicht verbaut
3 = Fehler";

CM_ SG_ 1462 BEB_hi_ResponseError "siehe LIN2.0-Specification
(Darf nicht über ein Fehlergueltigkeitsbit abgesichtert werden!)";
CM_ SG_ 1462 BEB_hi_SAD_Rollo_AutoAuf "Rollo Fond Panoramadach öffnen Automatikmodus";
CM_ SG_ 1462 BEB_hi_SAD_Rollo_AutoZu "Bedienung Rollo Panoramadach Fond Automodus schliessen. ";
CM_ SG_ 1462 BEB_hi_SAD_Rollo_defekt "Taster für Rollo hinten defekt";
CM_ SG_ 1462 BEB_hi_SAD_Rollo_haengt "Taste für Rollo hinten haengt";
CM_ SG_ 1462 BEB_hi_SAD_Rollo_ManAuf "Rollo Panoramadach Fond manuell öffnen";
CM_ SG_ 1462 BEB_hi_SAD_Rollo_ManZu "Schliessen Rollo Panoramadach manuell";
CM_ SG_ 1462 BEB_hi_T_Lueftung "Elektrische Mitteldüse - Ausströmer öffnen/schließen";
CM_ SG_ 1462 BEB_hi_T_Lueftung_LZ_links "Einstellung der elektrischen Lüftungsdüse. Verstellung Linke Zone nach links";
CM_ SG_ 1462 BEB_hi_T_Lueftung_LZ_rechts "Einstellung der elektrischen Lüftungsdüse. Verstellung Linke Zone nach rechts";
CM_ SG_ 1462 BEB_hi_T_Lueftung_oben "Einstellung der elektrischen Lüftungsdüse. Verstellung nach oben";
CM_ SG_ 1462 BEB_hi_T_Lueftung_RZ_links "Einstellung der elektrischen Lüftungsdüse. Verstellung rechte Zone nach links";
CM_ SG_ 1462 BEB_hi_T_Lueftung_RZ_rechts "Einstellung der elektrischen Lüftungsdüse. Verstellung rechte Zone nach rechts";
CM_ SG_ 1462 BEB_hi_T_Lueftung_unten "Einstellung der elektrischen Lüftungsdüse. Verstellung nach unten";
CM_ SG_ 1462 BEB_hi_T_SIH_HL "Status Taster Sitzheizung Hinten Links im Fond MSB";
CM_ SG_ 1462 BEB_hi_T_SIH_HR "Status Taster Sitzheizung Hinten Rechts im Fond MSB";
CM_ SG_ 1462 BEB_hi_T_SIL_HL "Status Taster Sitzlueftung Hinten Links im Fond MSB";
CM_ SG_ 1462 BEB_hi_T_SIL_HR "Status Taster Sitzlueftung Hinten Rechts im Fond MSB";
CM_ SG_ 1462 SL1_Heckrollo_Taster "Status Heckrollo Taste";

CM_ SG_ 1431 BED_Rollo_vo "Schalterfeld MIKO für Sonnenrollo Schiebedach vorne";
CM_ SG_ 1431 BED_SAD_vo "Bedienschalter für Schiebe / Ausstelldach vorne";
CM_ SG_ 1431 BED_Taster_Fahrwerk "Beschreibt den Fahrwerkstaster";
CM_ SG_ 1431 BED_Taster_Lift "Betätigungsstatus der Lift - Taste";
CM_ SG_ 1431 BED_Taster_VD_Oeffnen "Signal des Verdecktasters zum Oeffnen des Verdecks";
CM_ SG_ 1431 BED_Taster_VD_Schliessen "Signal des Verdecktasters zum Schliessen des Verdecks";
CM_ SG_ 1431 BED_Taster_Windschott "Bedientaster zum Aufstellen und Ablegen des Windschott";
CM_ SG_ 1431 SoSe_SunInt_2D_Li_Dash "Sonnenintensität links (2D Sensor) Dashboard";
CM_ SG_ 1431 SoSe_SunInt_2D_Re_Dash "Sonnenintensität rechts (2D Sensor) Dashboard";

CM_ SG_ 870 Blinken_li_Fzg_Takt "Fzg-Takt Blinker links

";
CM_ SG_ 870 Blinken_li_Kombi_Takt "Kombi-Takt Blinker links

";
CM_ SG_ 870 Blinken_re_Fzg_Takt "Fzg-Takt Blinker rechts

";
CM_ SG_ 870 Blinken_re_Kombi_Takt "Kombi-Takt Blinker rechts

";
CM_ SG_ 870 BM_Autobahn "Status Autobahnblinken
";
CM_ SG_ 870 BM_Crash "Status Crashblinken
";
CM_ SG_ 870 BM_DWA_Alarm "Status DWA-Alarmblinken
";
CM_ SG_ 870 BM_DWA_ein "Status Quittierungsblinken DWA";
CM_ SG_ 870 BM_GDO "Blinken bei UGDO anlernen

";
CM_ SG_ 870 BM_HD_Oeffnung_angelernt "HD_Rueckmeld_prog eine Blinkerquittierung wird beim BCM2 angefordert.
Wenn die Geschwindigkeit kleiner einer vorgegebenen Schwelle (default 2km/h) ist wird das Signal BM_HD_Öffnung_angelernt versendet und die Blinkerquittierung ausgelöst";
CM_ SG_ 870 BM_links "Richtungsblinken links

";
CM_ SG_ 870 BM_NBA_n_codiert_n_aktiv "Notbremsanzeige nicht codiert/nicht aktiv (Fehler)";
CM_ SG_ 870 BM_NBA_Status "Notbremsanzeige Status nicht aktiv / BRL Dunkelphase / BRL Hellphase";
CM_ SG_ 870 BM_Not_Bremsung "Notbremsblinken

";
CM_ SG_ 870 BM_Panik "Panikblinken
";
CM_ SG_ 870 BM_PiloPa "Quittierungsblinken bei pilotierten Parkvorgängen";
CM_ SG_ 870 BM_Recas "Blinkermodus RECAS  (RearEndCollisionAlertSignal)";
CM_ SG_ 870 BM_rechts "Richtungsblinken rechts

";
CM_ SG_ 870 BM_Rollenmodus_Blinken "Das Signal wird statisch gesetzt, wenn die Blinkerart Rollenmodus_Blinken aktiv ist.";
CM_ SG_ 870 BM_Taxi_Notalarm "Blinken bei Taxi-Not-Alarm

";
CM_ SG_ 870 BM_Telematik "Telematikblinken
";
CM_ SG_ 870 BM_Telematik_Abbruchgrund "Gibt bei erwaretem aber ausbleibendem Flankenanstieg der BM_Telematik an wieso die Ausführung verhindert wurde. Bei Flankenabfall der BM_Telematik wird angegeben wieso die Ausführung beendet wurde.

Bei nicht bereitem Sender soll 'init' gesendet werden,";
CM_ SG_ 870 BM_Warnblinken "Warnblinken

";
CM_ SG_ 870 BM_WBT_Beleuchtung "Aktivierung Warnblinktasterfunktionsbeleuchtung
Warnblinktasterfunktionsbeleuchtung soll aktiviert werden (statisch auf 1)";
CM_ SG_ 870 BM_Wischblinken "Blinkermodus Wisch_Blinken";
CM_ SG_ 870 BM_ZV_auf "Blinken bei ZV auf

";
CM_ SG_ 870 BM_ZV_zu "Blinken bei ZV zu

";
CM_ SG_ 870 DWA_Alarmquelle "Signalisiert den Auslösegrund der DWA";

CM_ SG_ 401 BMS_01_BZ "Botschaft asynchron geroutet. Zählerwert kann springen.";
CM_ SG_ 401 BMS_01_CRC "Für MLB:
'Berechnung siehe Lastenheft 'Kommunikationsabsicherung für FlexRay und CAN''

Ab MQB und MLBevo:
'Berechnung siehe Lastenheft 'End-to-End Kommunikationsabsicherung''

Endwerte siehe Begleitdokument 'S-PDU Kennungsfolgen'";
CM_ SG_ 401 BMS_IstSpannung "actual voltage of the battery / Momentanwert: Batteriespannung";
CM_ SG_ 401 BMS_IstStrom_02 "Momentanwert: Batteriestrom
Stromrichtung: ein Ladestrom wird mit positiven, ein Entladestrom mit negativen Werten angegeben";
CM_ SG_ 401 BMS_IstStrom_02_Offset "Nachkommastelle des BMS_IstStrom_02";
CM_ SG_ 401 BMS_IstStrom_02_OffsetVZ "Vorzeichen des Offsets, bzw. der Nachkommastelle";
CM_ SG_ 401 BMS_SOC_HiRes "State of Charge / aktueller Ladezustand der Batterie (höhere Auflösung)";
CM_ SG_ 401 BMS_Spannung_ZwKr "Momentanwert: 
Spannung an den Batterie-HV-Anschlüssen";

CM_ SG_ 1482 BMS_07_CRC "Für MLB:
'Berechnung siehe Lastenheft 'Kommunikationsabsicherung für FlexRay und CAN''

Ab MQB und MLBevo:
'Berechnung siehe Lastenheft 'End-to-End Kommunikationsabsicherung''

Endwerte siehe Begleitdokument 'S-PDU Kennungsfolgen'";
CM_ SG_ 1482 BMS_Ausgleichsladung_Anf "BMS wünscht eine Ausgleichsladung
Flag derzeit ungenutzt, da BalancingModus im Detail noch nicht geklärt.";
CM_ SG_ 1482 BMS_Balancing_Aktiv "Signal zeigt an, ob mindestens eine Zelle der HV Batterie balanciert wird";
CM_ SG_ 1482 BMS_Batteriediagnose "Anzeige von Textwarnungen";
CM_ SG_ 1482 BMS_Energieinhalt "aktuell nutzbarer Energieinhalt der HV-Batterie
(bezogen auf ein definiertes mittleres Belastungsprofil)";
CM_ SG_ 1482 BMS_Fehler_KuehlkreislaufLeckage "Bei einer Leckage im Kühlkreislauf wird dieser Fehler gesetzt.";
CM_ SG_ 1482 BMS_Freig_max_Performanz "Freigabe der Komponente, dass eine maximale Leistung zur Verfügung gestellt werden kann.";
CM_ SG_ 1482 BMS_Gesamtst_Spgfreiheit "0 = Funktion nicht aktiviert
1 = HV-System spannungsfrei (U_Zwkr von BMS, LE und Ladegerät < 20V, DCLadestecker nicht gesteckt und Service Disconnect entriegelt)
2 = HV-System nicht spannungsfrei (U_Zwkr von BMS, LE und Ladegerät >= 20V, Ladestecker ges";
CM_ SG_ 1482 BMS_KundenWarnung "Kunden Warnung aufgrund eines Batteriefehlers";
CM_ SG_ 1482 BMS_Ladevorgang_aktiv "Signalisiert aktiven Ladevorgang, Ladegerät und DC/DC aktiv.
Signal bleibt nach Kl.15 ein aktiv, bis ESP_Stillstandsflag gelöscht.

Abhängigkeit zu BMS_Energieinhalt";
CM_ SG_ 1482 BMS_MaxEnergieinhalt "maximaler nutzbarer Energieinhalt der HV-Batterie (bezogen auf Last KBI_RWDS_Lastprofil bei SOC=100%)
Abhängig von KBI_RWDS_Lastprofil";
CM_ SG_ 1482 BMS_RIso_Ext "Minimum des Isolationswiderstands zwischen Batteriegehäuse und HV+ bzw. Batteriegehäuse und HV- bei geschlossenen Schützen (externe Iso Messung)";

CM_ SG_ 1111 BMS_14_BZ "4bit Botschaftszähler, wird mit jeder Sendebotschaft inkrementiert
Botschaft asynchron geroutet. Zählerwert kann springen.";
CM_ SG_ 1111 BMS_14_CRC "Für MLB:
Berechnung siehe Lastenheft 'Kommunikationsabsicherung für FlexRay und CAN'
Ab MQB und MLBevo:
Berechnung siehe Lastenheft 'End-to-End Kommunikationsabsicherung'

Endwerte siehe Begleitdokument 'S-PDU Kennungsfolgen'";
CM_ SG_ 1111 BMS_RIso_GND_HVM "Iso-Widerstand
negative Werte = Isowiderstand GND zu HV-
Nur relevant für Fahrzeuge (z.B. PO513/xxx_B) mit HV-Ladebooster (DCDC_HV_02)";
CM_ SG_ 1111 BMS_RIso_GND_HVP "Iso-Widerstand
positive Werte = Isowiderstand GND zu HV+
Nur relevant für Fahrzeuge (z.B. PO513/xxx_B) mit HV-Ladebooster (DCDC_HV_02)";
CM_ SG_ 1111 BMS_Spannung_ZwKr2 "Momentanwert: 
Zweite Zwischenkreisspannung für Batterien mit zwei HV Abgaengen (zwei HV Kreise)
MLBevo PAG:
BMS_Spannung_ZwKr    vordere LE
BMS_Spannung_ZwKr2  hintere LE";
CM_ SG_ 1111 BMS_Warnung_Stuetzung_NV "Warnung an das Energiemanagement zur Verfügbarkeit der sicherheitsrelevanten NV-Stützung.

Bei Stuetzung_iO kann die HV-Batterie zum aktuellen Zeitpunkt für die vorgegebene Dauer die notwendige Leistung/Energie zur Stützung des NV-Systems zur Verfügung ";

CM_ SG_ 823 CC_CF_Einzelhindernis_01 "Konfidenzwert Hindernistyp/Verortung";
CM_ SG_ 823 CC_CF_Einzelhindernis_02 "Konfidenzwert Hindernishöhe";
CM_ SG_ 823 CC_CF_Einzelhindernis_03 "Konfidenzwert Hindernislänge";
CM_ SG_ 823 CC_CF_Einzelhindernis_04 "Konfidenzwert Steigung Flanke (Anfang)";
CM_ SG_ 823 CC_CF_Einzelhindernis_05 "Konfidenzwert Steigung Flanke (Ende)";
CM_ SG_ 823 CC_CF_Einzelhindernis_06 "Connected Chassis Einzelhindernis (Schlagloch/Speedbump) Confidence";
CM_ SG_ 823 CC_CF_Einzelhindernis_07 "Connected Chassis Einzelhindernis (Schlagloch/Speedbump) Confidence";
CM_ SG_ 823 CC_CF_Einzelhindernis_08 "Connected Chassis Einzelhindernis (Schlagloch/Speedbump) Confidence";
CM_ SG_ 823 CC_Einzelhindernis_01 "Hindernistyp inklusive laterale Verortung";
CM_ SG_ 823 CC_Einzelhindernis_02 "Hindernishöhe";
CM_ SG_ 823 CC_Einzelhindernis_03 "Hindernislänge";
CM_ SG_ 823 CC_Einzelhindernis_04 "Steigung Flanke (Anfang)";
CM_ SG_ 823 CC_Einzelhindernis_05 "Steigung Flanke (Ende)";
CM_ SG_ 823 CC_Einzelhindernis_06 "Connected Chassis Einzelhindernis (Schlagloch/Speedbump)";
CM_ SG_ 823 CC_Einzelhindernis_07 "Connected Chassis Einzelhindernis (Schlagloch/Speedbump)";
CM_ SG_ 823 CC_Einzelhindernis_08 "Connected Chassis Einzelhindernis (Schlagloch/Speedbump)";
CM_ SG_ 823 CC_MessZeitpunkt_Hindernis "Messzeitpunkt des Hindernisses (Anteil Sekunden) bezogen auf AirbagMastertime";
CM_ SG_ 823 CC_MessZeitpunkt_ms_Hindernis "Messzeitpunkt des Hindernisses (Anteil Millisekunden) bezogen auf AirbagMastertime";
CM_ SG_ 823 CC_MessZeitpunkt_OffsetHindernis "Messzeitpunkt des Hindernisses (Anteil Offset) bezogen auf AirbagMastertimeOffset";

CM_ SG_ 824 CC_CF_Strassenkategorie_01 "Konfidenzwert Straßenkategorie";
CM_ SG_ 824 CC_CF_Strassenkategorie_02 "Konfidenzwert (Dominante Frequenz)";
CM_ SG_ 824 CC_CF_Strassenkategorie_03 "Konfidenzwert Periodizitätsfaktor";
CM_ SG_ 824 CC_CF_Strassenkategorie_04 "Konfidenzwert Reibwert";
CM_ SG_ 824 CC_CF_Strassenkategorie_05 "Connected Chassis Strassenzustandskategorie Confidence";
CM_ SG_ 824 CC_CF_Strassenkategorie_06 "Connected Chassis Strassenzustandskategorie Confidence";
CM_ SG_ 824 CC_CF_Strassenkategorie_07 "Connected Chassis Strassenzustandskategorie Confidence";
CM_ SG_ 824 CC_CF_Strassenkategorie_08 "Connected Chassis Strassenzustandskategorie Confidence";
CM_ SG_ 824 CC_MessZeitpunkt_ms_StrZustand "Messzeitpunkt des Straßenkategorie (Anteil Millisekunden) bezogen auf AirbagMastertime";
CM_ SG_ 824 CC_MessZeitpunkt_OffsetStrZustan "Messzeitpunkt des Straßenkategorie (Anteil Offset) bezogen auf AirbagMastertimeOffset";
CM_ SG_ 824 CC_MessZeitpunkt_Strassenzustand "Messzeitpunkt des Straßenkategorie (Anteil Sekunden) bezogen auf AirbagMastertime";
CM_ SG_ 824 CC_Strassenkategorie_01 "Straßenkategorie";
CM_ SG_ 824 CC_Strassenkategorie_02 "Dominante Frequenz";
CM_ SG_ 824 CC_Strassenkategorie_03 "Periodizitätsfaktor";
CM_ SG_ 824 CC_Strassenkategorie_04 "Parameter Reibwert";
CM_ SG_ 824 CC_Strassenkategorie_05 "Connected Chassis Strassenzustandskategorie";
CM_ SG_ 824 CC_Strassenkategorie_06 "Connected Chassis Strassenzustandskategorie";
CM_ SG_ 824 CC_Strassenkategorie_07 "Connected Chassis Strassenzustandskategorie";
CM_ SG_ 824 CC_Strassenkategorie_08 "Connected Chassis Strassenzustandskategorie";

CM_ SG_ 825 CC_Version_Hindernis "Version Kodierung für Hindernistyp";
CM_ SG_ 825 CC_Version_Strassenkategorie "Version Kodierung für Straßenkategorie";

CM_ SG_ 901 CHA_Fahrer_Umschaltung "Die manuelle Umschaltung durch den Fahrer soll signalisiert werden, um zu automatischen Umschaltungen (z.B. Retries) differenzieren zu können.";
CM_ SG_ 901 CHA_Fahrer_Umschaltung_BMA "Die manuelle Umschaltung der Betriebsmodusauswahl durch den Fahrer soll signalisiert werden, um zu automatischen Umschaltungen (z.B. Retries) differenzieren zu können.";
CM_ SG_ 901 CHA_Ziel_FahrPr_ACC "MQB
Anforderung Ziel-Fahrprogramm ACC";
CM_ SG_ 901 CHA_Ziel_FahrPr_AFS "Anforderung Ziel-Fahrprogramm AFS";
CM_ SG_ 901 CHA_Ziel_FahrPr_AGA "Anforderung Ziel-Fahrprogramm AGA/SAK2 (Aussensound)";
CM_ SG_ 901 CHA_Ziel_FahrPr_ALR "Anforderung Ziel-Fahrprogramm Allrad";
CM_ SG_ 901 CHA_Ziel_FahrPr_DR "Anforderung Ziel-Fahrprogramm Dämpfer";
CM_ SG_ 901 CHA_Ziel_FahrPr_EPS "Anforderung Ziel-Fahrprogramm Elektrische Lenkhilfe";
CM_ SG_ 901 CHA_Ziel_FahrPr_ESP "Anforderung Ziel-Fahrprogramm ESP";
CM_ SG_ 901 CHA_Ziel_FahrPr_Freilauf "Anforderung Ziel-Fahrprogramm Funktion Freilauf";
CM_ SG_ 901 CHA_Ziel_FahrPr_GE "Anforderung Ziel-Fahrprogramm Getriebe";
CM_ SG_ 901 CHA_Ziel_FahrPr_MO "Anforderung Ziel-Fahrprogramm Motor";
CM_ SG_ 901 CHA_Ziel_FahrPr_MO_BZS "Anforderung Zielfahrprogramm Motor-Betriebszusände";
CM_ SG_ 901 CHA_Ziel_FahrPr_MO_StSt "Anforderung Ziel-Fahrprogramm Funktion Motor Start-Stopp";
CM_ SG_ 901 CHA_Ziel_FahrPr_PreCrash "Anforderung Ziel-Fahrprogramm PreCrash";
CM_ SG_ 901 CHA_Ziel_FahrPr_SAK "Anforderung Ziel-Fahrprogramm Soundaktuator";
CM_ SG_ 901 CHA_Ziel_FahrPr_VAQ "Anforderung Ziel-Fahrprogramm VAQ";

CM_ SG_ 902 CHA_Charge_LED "Ansteuerung der LED am Charge-Taster durch Charisma im PHEV";
CM_ SG_ 902 CHA_Current_Mode "Aktuell eingestelltes Charisma Fahrprogramm";
CM_ SG_ 902 CHA_Drehschalter_Istmodus "Aktuell eingestellte Vorgabe für Schalterposition des CHA-Drehschalters";
CM_ SG_ 902 CHA_Eco_Charisma_LED "Ansteuerung der Funktions-LED der ECO alias Bluekey Taste bzw. Charisma-Taste.
Der Master der Fahrmodus-Funktion soll die Funktionsleuchte ansteuern, in der MQB Architektur ist der Master im Gateway untergebracht.";
CM_ SG_ 902 CHA_EV_LED "Ansteuerung der LED am EV-Taster durch Charisma im PHEV";
CM_ SG_ 902 CHA_Fahrer_Umschaltung "Die manuelle Umschaltung durch den Fahrer soll signalisiert werden, um zu automatischen Umschaltungen (z.B. Retries) differenzieren zu können.";
CM_ SG_ 902 CHA_Kombi_Texte "Anzeige des aktuellen Charisma-Fahrprofiles im Kombi.
Die Texte werden HUT-Spezifisch in einem Schnittstellen-LAH definiert.";
CM_ SG_ 902 CHA_Kombi_Texte_02 "Anzeige von Hinweistexten bzgl. Charismaumschaltungen im Kombi.
Die Texte werden HUT-Spezifisch in einem Schnittstellen-LAH definiert.";
CM_ SG_ 902 CHA_Offroad_LED "Ansteuerung der Offroad-LED";
CM_ SG_ 902 CHA_Ziel_FahrPr_03_01 "reserviert für Anforderung Ziel-Fahrprogramm";
CM_ SG_ 902 CHA_Ziel_FahrPr_03_02 "reserviert für Anforderung Ziel-Fahrprogramm";
CM_ SG_ 902 CHA_Ziel_FahrPr_AMB "Anforderung Ziel-Fahrprogramm Ambientelichtmodul";
CM_ SG_ 902 CHA_Ziel_FahrPr_HSP "Anforderung Ziel-Fahrprogramm Heckspoiler";
CM_ SG_ 902 CHA_Ziel_FahrPr_IVB "Anforderung Ziel-Fahrprogramm IVB";
CM_ SG_ 902 CHA_Ziel_FahrPr_KL "Anforderung Ziel-Fahrprogramm Klima";
CM_ SG_ 902 CHA_Ziel_FahrPr_RWB "Anforderung Zielfahrprogramm Reichweitenberechnung (RWB)";

CM_ SG_ 615 Daempfer_02_BZ "Botschaft asynchron geroutet. Zählerwert kann springen.";
CM_ SG_ 615 Daempfer_02_CRC "Für MLB:
'Berechnung siehe Lastenheft 'Kommunikationsabsicherung für FlexRay und CAN''

Ab MQB und MLBevo:
'Berechnung siehe Lastenheft 'End-to-End Kommunikationsabsicherung''

Endwerte siehe Begleitdokument 'S-PDU Kennungsfolgen'";
CM_ SG_ 615 DR_Charisma_FahrPr "MLBevo: Aktuelles Fahrprogramm des Charisma-Teilnehmers (siehe Systemlastenheft Drive Select)
MQB: Istwert der Kennlinie (siehe Systemlastenheft MQB FPA)";
CM_ SG_ 615 DR_Charisma_Status "Charisma Systemstatus des Charisma-Teilnehmers

Wert 0x3 ist nur für Fahrzeuge ab MQB relevant";
CM_ SG_ 615 DR_DynAGL_Anf_Entkopplung "Nur PO44x
Dynamische Aggregatelagerung
Anforderung zusätzliche Entkopplung für Getriebelager";
CM_ SG_ 615 DR_DynAGL_Anf_im_Leerlauf "Nur PO44x
Anforderung zusätzliche Entkopplung des Motorlagers im Leerlauf";
CM_ SG_ 615 DR_ESP_Zuschaltung "Zwangsweise Aktivierung ESP-Funktionalität durch die Dämpferregelung, Anforderung erfolgt auch bei Passivtastung.";
CM_ SG_ 615 DR_Systemstatus "Bei Statusänderung wird der Soll-Zustand ausgegeben. Der Status beschreibt einen Parametersatz: Temporäre Änderung der Dämpfereinstellungen werden hier nicht abgebildet. 
";
CM_ SG_ 615 EFP_Niveauzustand_Lift "Rückmeldung Niveauzustand Liftfunktionalität";
CM_ SG_ 615 EFP_Verfuegbarkeit_Lift "Verfuegbarkeit der Liftfunktionalitaet";
CM_ SG_ 615 EFP_Vorlaufzeit_Lift "Vorlaufzeit Heben für Smartlift";

CM_ SG_ 2617219614 DEV_ZR_Pwm_Debug_1 "Powermanagement Debug 1 aktivieren";
CM_ SG_ 2617219614 DEV_ZR_Pwm_Debug_2 "Powermanagement Debug 1 aktivieren";
CM_ SG_ 2617219614 DEV_ZR_Pwm_Debug_3 "Powermanagement Debug 1 aktivieren";
CM_ SG_ 2617219614 DEV_ZR_Pwm_Debug_4 "Powermanagement Debug 1 aktivieren";

CM_ SG_ 2617219605 MMI_State "Powerstate des Zentralrechners. MMI_Off wird im Zustand dead mode gesendet.";
CM_ SG_ 2617219605 Routeg_aktiv "Routenführung aktiv
";
CM_ SG_ 2617219605 SI_MOST_Status "Das Signal gibt den Zustand des MOST wieder.";
CM_ SG_ 2617219605 Tel_aktiv "Aktives Telefonat oder mute pin aktiv
";
CM_ SG_ 2617219605 Tel_SIM_aktiv "SimKarte eingelegt

";
CM_ SG_ 2617219605 ZR_KL_30F "Gemessene Versorgungsspannung des Zentralrechners.
";
CM_ SG_ 2617219605 ZR_LastOn "LastOn state des Zentralrechners";
CM_ SG_ 2617219605 ZR_State_DU_1 "Kontrollbit für Display, Hintergrundbeleuchtung aus, Hintergrundbeleuchtung an, Energiesparmodus.
";
CM_ SG_ 2617219605 ZR_TempSens "Aktueller Temperaturwert des Zentralrechners";

CM_ SG_ 1714 DGN_Verlernzaehler "wrap around 254 --> 0";
CM_ SG_ 1714 KBI_Kilometerstand "Fehler wird ausgegeben, falls Kilometerstand nicht restaurierbar
";
CM_ SG_ 1714 UH_Minute "0x3C- 0x3f = Werte ungültig";
CM_ SG_ 1714 UH_Monat "0x0D, 0xF =  Werte ungültig
0x0E = Relatives Datum (nur VW)";
CM_ SG_ 1714 UH_Sekunde "0x3C- 0x3f = Werte ungültig";
CM_ SG_ 1714 UH_Stunde "0x18 - 0x1F = Werte ungültig";
CM_ SG_ 1714 UH_Tag "0x0: reserviert bei VW";
CM_ SG_ 1714 Uhrzeit_01_alt "
";

CM_ SG_ 1520 BCM1_Stellgroesse_Kl_58s "Rohwert Dimmpoti";
CM_ SG_ 1520 DI_Display_Nachtdesign "Für Displays sind oft  automatische Umschaltungen von Tag-/Nachtdesign vorgesehen.
Es gibt jedoch Zustände, an denen auch tagsüber das Abblendlicht eingeschaltet ist.
z.B. Dauerfahrlicht, Geschwindigkeitsabhängiges 'Licht-An-Bei-Autobahn', 'Regenlicht',";
CM_ SG_ 1520 DI_Fotosensor "Helligkeitswert Fotosensor
Für die Dimmung relevanter Wert zur Sensierung der Umgebungshelligkeit
Im Detail beschrieben im 'Funktionslastenheft Dimmung MQB'.";
CM_ SG_ 1520 DI_KL_58xd "Klemme 58xd Display- und Funktionsbeleuchtung
Mit der Klemme 58xd wird die Helligkeit der Display- und der Funktionsbeleuchtungen der Schalter gesteuert.
Im Detail beschrieben im 'Funktionslastenheft Dimmung MQB'.";
CM_ SG_ 1520 DI_KL_58xs "Suchbeleuchtung Schalter
EIN-AUS-Schaltalgorithmus der allgemeinen Schaltersuchbeleuchtung. 
Im Detail beschrieben im 'Funktionslastenheft Dimmung MQB'.
";
CM_ SG_ 1520 DI_KL_58xt "Timergesteuerte Suchbeleuchtung
Der EIN-AUS-Schaltalgorithmus für die vor- und nachlaufende Schaltersuchbeleuchtungen beim Ein- & Aussteigen; z.B.: Start/Stop-Taster.
Im Detail beschrieben im 'Funktionslastenheft Dimmung MQB'.";

CM_ SG_ 420 EA_01_BZ "EA Botschaftszähler
Botschaft asynchron geroutet. Zählerwert kann springen.";
CM_ SG_ 420 EA_01_CRC "Ab MQB und MLBevo:
'Berechnung siehe Lastenheft 'End-to-End Kommunikationsabsicherung''";
CM_ SG_ 420 EA_Anforderung_HMS "Emergency Assist Anforderung an HMS";
CM_ SG_ 420 EA_eCall_Anf "Emergency Assist Anforderung eCall";
CM_ SG_ 420 EA_Funktionsstatus "Emergency Assist Funktionsstatus";
CM_ SG_ 420 EA_Gurtstraffer_Anf "Emergency Assist Anforderung reversibler Gurtstraffer";
CM_ SG_ 420 EA_Parken_beibehalten_HMS "Anforderung um automatisches lösen der Parkbremse zu verhindern";
CM_ SG_ 420 EA_Sollbeschleunigung "Emergency Assist Beschleunigungsanforderung";
CM_ SG_ 420 EA_Warnruckprofil "Emergency Assist Anforderung an ESP, welcher Ruck verwendet werden soll.";
BA_DEF_REL_ BU_SG_REL_  "GenSigTimeoutTime" INT 0 65535;
BA_DEF_ BO_  "DiagRequest" ENUM "No", "Yes";
BA_DEF_ BO_  "DiagResponse" ENUM "No", "Yes";
BA_DEF_ BO_  "DiagState" ENUM "No", "Yes";
BA_DEF_ BO_  "GenMsgChkConstant" HEX 0 4095;
BA_DEF_ BO_  "GenMsgCycleTime" INT 0 65535;
BA_DEF_ BO_  "GenMsgCycleTimeFast" INT 0 65535;
BA_DEF_ BO_  "GenMsgDelayTime" INT 0 100000;
BA_DEF_ BO_  "GenMsgILSupport" ENUM "No", "Yes";
BA_DEF_ BO_  "GenMsgNrOfRepetition" INT 0 100;
BA_DEF_ BO_  "GenMsgPDUConstants" STRING;
BA_DEF_ BO_  "GenMsgSendType" ENUM "Cyclic", "not_used", "not_used", "not_used", "not_used", "not_used", "not_used", "IfActive", "NoMsgSendType";
BA_DEF_ BO_  "GenMsgStartDelayTime" INT 0 100000;
BA_DEF_ BO_  "NmMessage" ENUM "No", "Yes";
BA_DEF_ BO_  "NmhMessage" ENUM "No", "Yes";
BA_DEF_ BO_  "MsgType" ENUM "Application", "NM ", "NMH", "TP2.0", "ISO-TP ", "BAP", "EID", "KS", "XCP_PRE_CONFIGURED", "XCP_RUNTIME_CONFIGURED";
BA_DEF_ BO_  "VAGTP20_API" HEX 0 255;
BA_DEF_ BO_  "VAGTP20_DynConnection" ENUM "No", "Yes";
BA_DEF_ BO_  "VAGTP20_DynSetup" ENUM "No", "Yes";
BA_DEF_ BO_  "VAGTP20_StatConnection" ENUM "No", "Yes";
BA_DEF_ SG_  "GenSigActiveRepetitions" INT -2147483648 2147483647;
BA_DEF_ SG_  "GenSigInactiveValue" INT -2147483648 2147483647;
BA_DEF_ SG_  "GenSigSendType" ENUM "Cyclic", "OnWrite", "OnWriteWithRepetition", "OnChange", "OnChangeWithRepetition", "IfActive", "IfActiveWithRepetition", "NoSigSendType", "OnChangeAndIfActive", "OnChangeAndIfActiveWithRepetition";
BA_DEF_ SG_  "GenSigStartValue" INT -2147483648 2147483647;
BA_DEF_ SG_  "NWM-WakeupAllowed" ENUM "No", "Yes";
BA_DEF_ SG_  "GenSigFuncType" ENUM "NoFunction", "MsgCounter", "CRC-8", "XOR", "XOR-2", "DatedBit", "SW-Kl15", "CHK", "Constant", "Protocol", "CRC-8-SAE_J1850", "CRC-32", "DataLength", "DataID", "MsgCounter16", "SOK-Signatur", "Cluster";
BA_DEF_ SG_  "GenSigSwitchedByIgnition" ENUM "No", "Yes";
BA_DEF_ SG_  "Fehlerwert" HEX 0 2147483647;
BA_DEF_ SG_  "GenSigMissingSourceValue" HEX 0 2147483647;
BA_DEF_DEF_REL_  "GenSigTimeoutTime" 0;
BA_DEF_DEF_  "DiagRequest" "No";
BA_DEF_DEF_  "DiagResponse" "No";
BA_DEF_DEF_  "DiagState" "No";
BA_DEF_DEF_  "GenMsgChkConstant" 0;
BA_DEF_DEF_  "GenMsgCycleTime" 0;
BA_DEF_DEF_  "GenMsgCycleTimeFast" 0;
BA_DEF_DEF_  "GenMsgDelayTime" 0;
BA_DEF_DEF_  "GenMsgILSupport" "No";
BA_DEF_DEF_  "GenMsgNrOfRepetition" 0;
BA_DEF_DEF_  "GenMsgPDUConstants" "";
BA_DEF_DEF_  "GenMsgSendType" "NoMsgSendType";
BA_DEF_DEF_  "GenMsgStartDelayTime" 0;
BA_DEF_DEF_  "NmMessage" "No";
BA_DEF_DEF_  "NmhMessage" "No";
BA_DEF_DEF_  "MsgType" "Application";
BA_DEF_DEF_  "VAGTP20_API" 0;
BA_DEF_DEF_  "VAGTP20_DynConnection" "No";
BA_DEF_DEF_  "VAGTP20_DynSetup" "No";
BA_DEF_DEF_  "VAGTP20_StatConnection" "No";
BA_DEF_DEF_  "GenSigActiveRepetitions" 0;
BA_DEF_DEF_  "GenSigInactiveValue" 0;
BA_DEF_DEF_  "GenSigSendType" "NoSigSendType";
BA_DEF_DEF_  "GenSigStartValue" 0;
BA_DEF_DEF_  "NWM-WakeupAllowed" "No";
BA_DEF_DEF_  "GenSigFuncType" "NoFunction";
BA_DEF_DEF_  "GenSigSwitchedByIgnition" "Yes";
BA_DEF_DEF_  "Fehlerwert" 0;
BA_DEF_DEF_  "GenSigMissingSourceValue" 0;
BA_ "GenMsgCycleTime" BO_ 1626 1000;
BA_ "GenMsgCycleTimeFast" BO_ 1626 100;
BA_ "GenMsgDelayTime" BO_ 1626 50;
BA_ "GenMsgILSupport" BO_ 1626 1;
BA_ "GenMsgNrOfRepetition" BO_ 1626 10;
BA_ "GenMsgSendType" BO_ 1626 0;
BA_ "GenMsgCycleTime" BO_ 672 200;
BA_ "GenMsgCycleTimeFast" BO_ 672 20;
BA_ "GenMsgDelayTime" BO_ 672 20;
BA_ "GenMsgILSupport" BO_ 672 1;
BA_ "GenMsgNrOfRepetition" BO_ 672 5;
BA_ "GenMsgPDUConstants" BO_ 672 "0x6a,0x65,0x16,0x26,0xd9,0x99,0xd1,0x84,0xf3,0x9c,0xa4,0xaa,0x07,0xea,0xc2,0xcb";
BA_ "GenMsgSendType" BO_ 672 0;
BA_ "GenMsgCycleTime" BO_ 2463978607 200;
BA_ "GenMsgDelayTime" BO_ 2463978607 20;
BA_ "GenMsgILSupport" BO_ 2463978607 1;
BA_ "GenMsgSendType" BO_ 2463978607 0;
BA_ "GenMsgCycleTime" BO_ 2589283629 1000;
BA_ "GenMsgDelayTime" BO_ 2589283629 100;
BA_ "GenMsgILSupport" BO_ 2589283629 1;
BA_ "GenMsgSendType" BO_ 2589283629 0;
BA_ "GenMsgCycleTime" BO_ 1448 500;
BA_ "GenMsgDelayTime" BO_ 1448 50;
BA_ "GenMsgILSupport" BO_ 1448 1;
BA_ "GenMsgSendType" BO_ 1448 0;
BA_ "GenMsgStartDelayTime" BO_ 1448 60;
BA_ "GenMsgCycleTime" BO_ 961 200;
BA_ "GenMsgCycleTimeFast" BO_ 961 20;
BA_ "GenMsgDelayTime" BO_ 961 20;
BA_ "GenMsgILSupport" BO_ 961 1;
BA_ "GenMsgNrOfRepetition" BO_ 961 5;
BA_ "GenMsgSendType" BO_ 961 0;
BA_ "GenMsgCycleTime" BO_ 1432 1000;
BA_ "GenMsgCycleTimeFast" BO_ 1432 100;
BA_ "GenMsgDelayTime" BO_ 1432 50;
BA_ "GenMsgILSupport" BO_ 1432 1;
BA_ "GenMsgNrOfRepetition" BO_ 1432 5;
BA_ "GenMsgSendType" BO_ 1432 0;
BA_ "GenMsgCycleTime" BO_ 1462 1000;
BA_ "GenMsgCycleTimeFast" BO_ 1462 100;
BA_ "GenMsgDelayTime" BO_ 1462 50;
BA_ "GenMsgILSupport" BO_ 1462 1;
BA_ "GenMsgNrOfRepetition" BO_ 1462 5;
BA_ "GenMsgSendType" BO_ 1462 0;
BA_ "GenMsgCycleTime" BO_ 1431 500;
BA_ "GenMsgCycleTimeFast" BO_ 1431 50;
BA_ "GenMsgDelayTime" BO_ 1431 20;
BA_ "GenMsgILSupport" BO_ 1431 1;
BA_ "GenMsgNrOfRepetition" BO_ 1431 3;
BA_ "GenMsgSendType" BO_ 1431 0;
BA_ "GenMsgCycleTime" BO_ 870 1000;
BA_ "GenMsgCycleTimeFast" BO_ 870 50;
BA_ "GenMsgDelayTime" BO_ 870 10;
BA_ "GenMsgILSupport" BO_ 870 1;
BA_ "GenMsgNrOfRepetition" BO_ 870 5;
BA_ "GenMsgSendType" BO_ 870 0;
BA_ "GenMsgCycleTime" BO_ 401 100;
BA_ "GenMsgILSupport" BO_ 401 1;
BA_ "GenMsgPDUConstants" BO_ 401 "0x7d,0x0e,0xaf,0x0b,0x24,0x58,0x88,0x9e,0x89,0x3a,0x81,0x61,0x4e,0xe3,0x04,0x1f";
BA_ "GenMsgSendType" BO_ 401 0;
BA_ "GenMsgChkConstant" BO_ 1482 67;
BA_ "GenMsgCycleTime" BO_ 1482 500;
BA_ "GenMsgDelayTime" BO_ 1482 50;
BA_ "GenMsgILSupport" BO_ 1482 1;
BA_ "GenMsgPDUConstants" BO_ 1482 "0x43,0x43,0x43,0x43,0x43,0x43,0x43,0x43,0x43,0x43,0x43,0x43,0x43,0x43,0x43,0x43";
BA_ "GenMsgSendType" BO_ 1482 0;
BA_ "GenMsgCycleTime" BO_ 1111 200;
BA_ "GenMsgILSupport" BO_ 1111 1;
BA_ "GenMsgPDUConstants" BO_ 1111 "0x82,0x79,0xee,0xb9,0xf9,0x67,0x97,0xad,0xb1,0xd5,0xcb,0xf7,0xb6,0x70,0x13,0xaa";
BA_ "GenMsgSendType" BO_ 1111 0;
BA_ "GenMsgCycleTimeFast" BO_ 823 80;
BA_ "GenMsgDelayTime" BO_ 823 80;
BA_ "GenMsgILSupport" BO_ 823 1;
BA_ "GenMsgSendType" BO_ 823 7;
BA_ "GenMsgCycleTimeFast" BO_ 824 80;
BA_ "GenMsgDelayTime" BO_ 824 80;
BA_ "GenMsgILSupport" BO_ 824 1;
BA_ "GenMsgSendType" BO_ 824 7;
BA_ "GenMsgCycleTime" BO_ 825 960;
BA_ "GenMsgILSupport" BO_ 825 1;
BA_ "GenMsgSendType" BO_ 825 0;
BA_ "GenMsgCycleTime" BO_ 901 1000;
BA_ "GenMsgDelayTime" BO_ 901 50;
BA_ "GenMsgILSupport" BO_ 901 1;
BA_ "GenMsgSendType" BO_ 901 0;
BA_ "GenMsgCycleTime" BO_ 902 1000;
BA_ "GenMsgDelayTime" BO_ 902 50;
BA_ "GenMsgILSupport" BO_ 902 1;
BA_ "GenMsgSendType" BO_ 902 0;
BA_ "GenMsgStartDelayTime" BO_ 902 50;
BA_ "GenMsgCycleTime" BO_ 615 1000;
BA_ "GenMsgDelayTime" BO_ 615 80;
BA_ "GenMsgILSupport" BO_ 615 1;
BA_ "GenMsgPDUConstants" BO_ 615 "0xc7,0x7d,0x4c,0x0e,0x19,0xaf,0x2e,0x0b,0x8d,0x24,0x62,0x58,0x67,0x88,0x93,0x9e";
BA_ "GenMsgSendType" BO_ 615 0;
BA_ "MsgType" BO_ 2617012992 6;
BA_ "MsgType" BO_ 2617013247 6;
BA_ "MsgType" BO_ 2617023232 6;
BA_ "MsgType" BO_ 2617023487 6;
BA_ "MsgType" BO_ 2617103104 6;
BA_ "MsgType" BO_ 2617103359 6;
BA_ "MsgType" BO_ 2617219613 6;
BA_ "MsgType" BO_ 2617219612 6;
BA_ "MsgType" BO_ 2617219597 6;
BA_ "MsgType" BO_ 2617219584 6;
BA_ "MsgType" BO_ 2617219614 6;
BA_ "MsgType" BO_ 2617219604 6;
BA_ "GenMsgCycleTime" BO_ 2617219605 1000;
BA_ "GenMsgDelayTime" BO_ 2617219605 40;
BA_ "MsgType" BO_ 2617219605 6;
BA_ "DiagRequest" BO_ 2549880610 1;
BA_ "MsgType" BO_ 2549880610 4;
BA_ "DiagResponse" BO_ 2550011682 1;
BA_ "MsgType" BO_ 2550011682 4;
BA_ "DiagRequest" BO_ 2549880611 1;
BA_ "MsgType" BO_ 2549880611 4;
BA_ "DiagResponse" BO_ 2550011683 1;
BA_ "MsgType" BO_ 2550011683 4;
BA_ "DiagRequest" BO_ 2549880473 1;
BA_ "MsgType" BO_ 2549880473 4;
BA_ "DiagResponse" BO_ 2550011545 1;
BA_ "MsgType" BO_ 2550011545 4;
BA_ "DiagRequest" BO_ 2549880474 1;
BA_ "MsgType" BO_ 2549880474 4;
BA_ "DiagResponse" BO_ 2550011546 1;
BA_ "MsgType" BO_ 2550011546 4;
BA_ "GenMsgCycleTime" BO_ 1714 1000;
BA_ "GenMsgILSupport" BO_ 1714 1;
BA_ "GenMsgSendType" BO_ 1714 0;
BA_ "GenMsgStartDelayTime" BO_ 1714 55;
BA_ "GenMsgCycleTime" BO_ 1520 200;
BA_ "GenMsgDelayTime" BO_ 1520 50;
BA_ "GenMsgILSupport" BO_ 1520 1;
BA_ "GenMsgSendType" BO_ 1520 0;
BA_ "GenMsgCycleTime" BO_ 420 500;
BA_ "GenMsgILSupport" BO_ 420 1;
BA_ "GenMsgPDUConstants" BO_ 420 "0x69,0xbb,0x54,0xe6,0x4e,0x46,0x8d,0x7b,0xea,0x87,0xe9,0xb3,0x63,0xce,0xf8,0xbf";
BA_ "GenMsgSendType" BO_ 420 0;
BA_ "GenMsgStartDelayTime" BO_ 420 130;
BA_ "GenSigSendType" SG_ 1626 APS_Tongeber_defekt 3;
BA_ "GenSigSwitchedByIgnition" SG_ 1626 APS_Tongeber_defekt 0;
BA_ "GenSigSendType" SG_ 1626 BCM1_AFS_Lampe 3;
BA_ "GenSigSwitchedByIgnition" SG_ 1626 BCM1_AFS_Lampe 0;
BA_ "GenSigSendType" SG_ 1626 BCM1_EasyEntry_Status 3;
BA_ "GenSigSwitchedByIgnition" SG_ 1626 BCM1_EasyEntry_Status 0;
BA_ "GenSigSendType" SG_ 1626 BCM1_Fahrlicht_Hinweis 3;
BA_ "GenSigSwitchedByIgnition" SG_ 1626 BCM1_Fahrlicht_Hinweis 0;
BA_ "GenSigSendType" SG_ 1626 BCM1_Hinweis_Lichtnachlauf 3;
BA_ "GenSigSwitchedByIgnition" SG_ 1626 BCM1_Hinweis_Lichtnachlauf 0;
BA_ "GenSigSendType" SG_ 1626 BCM1_Kl_15_HW_erkannt 3;
BA_ "GenSigSwitchedByIgnition" SG_ 1626 BCM1_Kl_15_HW_erkannt 0;
BA_ "GenSigSendType" SG_ 1626 BCM1_Kl_15_Sig_HW_erkannt 3;
BA_ "GenSigSwitchedByIgnition" SG_ 1626 BCM1_Kl_15_Sig_HW_erkannt 0;
BA_ "GenSigSendType" SG_ 1626 BCM1_LDS_Stellung 3;
BA_ "GenSigSwitchedByIgnition" SG_ 1626 BCM1_LDS_Stellung 0;
BA_ "Fehlerwert" SG_ 1626 BCM1_LDS_Stellung 7;
BA_ "GenSigSendType" SG_ 1626 BCM1_Lenksaeule_aktiv 3;
BA_ "GenSigSwitchedByIgnition" SG_ 1626 BCM1_Lenksaeule_aktiv 0;
BA_ "GenSigSendType" SG_ 1626 BCM1_Licht_Warn 3;
BA_ "GenSigSwitchedByIgnition" SG_ 1626 BCM1_Licht_Warn 0;
BA_ "GenSigSendType" SG_ 1626 BCM1_Lichtwarn_Texte 3;
BA_ "GenSigSwitchedByIgnition" SG_ 1626 BCM1_Lichtwarn_Texte 0;
BA_ "GenSigSendType" SG_ 1626 BCM1_MH_Schalter 3;
BA_ "GenSigSwitchedByIgnition" SG_ 1626 BCM1_MH_Schalter 0;
BA_ "GenSigSendType" SG_ 1626 BCM1_MH_WIV_Schalter 3;
BA_ "GenSigSwitchedByIgnition" SG_ 1626 BCM1_MH_WIV_Schalter 0;
BA_ "GenSigActiveRepetitions" SG_ 1626 BCM1_NV_Taster 10;
BA_ "GenSigSendType" SG_ 1626 BCM1_NV_Taster 4;
BA_ "GenSigSwitchedByIgnition" SG_ 1626 BCM1_NV_Taster 0;
BA_ "GenSigSendType" SG_ 1626 BCM1_Reisemodus_Texte 3;
BA_ "GenSigSwitchedByIgnition" SG_ 1626 BCM1_Reisemodus_Texte 0;
BA_ "GenSigSendType" SG_ 1626 BCM1_Rueckfahrlicht_Schalter 3;
BA_ "GenSigSwitchedByIgnition" SG_ 1626 BCM1_Rueckfahrlicht_Schalter 0;
BA_ "GenSigSendType" SG_ 1626 BCM1_Schluesselsuche_Anf 0;
BA_ "GenSigSwitchedByIgnition" SG_ 1626 BCM1_Schluesselsuche_Anf 0;
BA_ "GenSigSendType" SG_ 1626 BCM1_St_SW_Diebstahl_links 3;
BA_ "GenSigSwitchedByIgnition" SG_ 1626 BCM1_St_SW_Diebstahl_links 0;
BA_ "GenSigSendType" SG_ 1626 BCM1_St_SW_Diebstahl_rechts 3;
BA_ "GenSigSwitchedByIgnition" SG_ 1626 BCM1_St_SW_Diebstahl_rechts 0;
BA_ "GenSigActiveRepetitions" SG_ 1626 BCM1_Valet_Parking_Taster 10;
BA_ "GenSigSendType" SG_ 1626 BCM1_Valet_Parking_Taster 4;
BA_ "GenSigSwitchedByIgnition" SG_ 1626 BCM1_Valet_Parking_Taster 0;
BA_ "GenSigActiveRepetitions" SG_ 1626 BCM1_Warnblink_Taster 10;
BA_ "GenSigSendType" SG_ 1626 BCM1_Warnblink_Taster 4;
BA_ "GenSigSwitchedByIgnition" SG_ 1626 BCM1_Warnblink_Taster 0;
BA_ "GenSigSendType" SG_ 1626 BCM_Bremsbelag_Sensor 3;
BA_ "GenSigSwitchedByIgnition" SG_ 1626 BCM_Bremsbelag_Sensor 0;
BA_ "GenSigSendType" SG_ 1626 BCM_Bremsfluessigkeit_Sensor 3;
BA_ "GenSigSwitchedByIgnition" SG_ 1626 BCM_Bremsfluessigkeit_Sensor 0;
BA_ "GenSigSendType" SG_ 1626 BCM_Eco_Charisma_Taste 3;
BA_ "GenSigSwitchedByIgnition" SG_ 1626 BCM_Eco_Charisma_Taste 0;
BA_ "GenSigSendType" SG_ 1626 BCM_HDF_betaetigt 3;
BA_ "GenSigSwitchedByIgnition" SG_ 1626 BCM_HDF_betaetigt 0;
BA_ "GenSigActiveRepetitions" SG_ 1626 BCM_Hybrid_StartStopp_Taste 10;
BA_ "GenSigSendType" SG_ 1626 BCM_Hybrid_StartStopp_Taste 4;
BA_ "GenSigSwitchedByIgnition" SG_ 1626 BCM_Hybrid_StartStopp_Taste 0;
BA_ "GenSigSendType" SG_ 1626 BCM_Hybrid_StSt_Taste_Fehler 0;
BA_ "GenSigSwitchedByIgnition" SG_ 1626 BCM_Hybrid_StSt_Taste_Fehler 0;
BA_ "GenSigSendType" SG_ 1626 BCM_Kuehlmittel_Sensor 3;
BA_ "GenSigSwitchedByIgnition" SG_ 1626 BCM_Kuehlmittel_Sensor 0;
BA_ "GenSigSendType" SG_ 1626 BCM_Kuehlmittel_Sensor_02 3;
BA_ "GenSigSwitchedByIgnition" SG_ 1626 BCM_Kuehlmittel_Sensor_02 0;
BA_ "GenSigSendType" SG_ 1626 BCM_Offroad_Taste 3;
BA_ "GenSigSwitchedByIgnition" SG_ 1626 BCM_Offroad_Taste 0;
BA_ "GenSigSendType" SG_ 1626 BCM_Waschwasser_Sensor 3;
BA_ "GenSigSwitchedByIgnition" SG_ 1626 BCM_Waschwasser_Sensor 0;
BA_ "GenSigSendType" SG_ 1626 Gong_TFL_Umschaltung 3;
BA_ "GenSigSwitchedByIgnition" SG_ 1626 Gong_TFL_Umschaltung 0;
BA_ "GenSigSendType" SG_ 1626 ISP_Dimmung_ASP_02 3;
BA_ "GenSigSendType" SG_ 1626 UGDO_Function_01 3;
BA_ "Fehlerwert" SG_ 1626 UGDO_Function_01 7;
BA_ "GenSigActiveRepetitions" SG_ 672 BCM2_Crashfall_erkannt 5;
BA_ "GenSigSendType" SG_ 672 BCM2_Crashfall_erkannt 6;
BA_ "GenSigSwitchedByIgnition" SG_ 672 BCM2_Crashfall_erkannt 0;
BA_ "GenSigSendType" SG_ 672 BCM2_Freigabe_Kofferr_Innenentr 0;
BA_ "GenSigSwitchedByIgnition" SG_ 672 BCM2_Freigabe_Kofferr_Innenentr 0;
BA_ "GenSigSendType" SG_ 672 BCM2_KL15_Absch_FT 3;
BA_ "GenSigSwitchedByIgnition" SG_ 672 BCM2_KL15_Absch_FT 0;
BA_ "GenSigSendType" SG_ 672 BCM2_P_verriegelt 3;
BA_ "GenSigSwitchedByIgnition" SG_ 672 BCM2_P_verriegelt 0;
BA_ "GenSigActiveRepetitions" SG_ 672 BCM2_Quittierung_Warnton_aktiv 5;
BA_ "GenSigSendType" SG_ 672 BCM2_Quittierung_Warnton_aktiv 4;
BA_ "GenSigSwitchedByIgnition" SG_ 672 BCM2_Quittierung_Warnton_aktiv 0;
BA_ "GenSigSendType" SG_ 672 BCM2_SST_gedrueckt 3;
BA_ "GenSigSwitchedByIgnition" SG_ 672 BCM2_SST_gedrueckt 0;
BA_ "GenSigActiveRepetitions" SG_ 672 BCM2_T_Deckel_Vorne 11;
BA_ "GenSigSendType" SG_ 672 BCM2_T_Deckel_Vorne 4;
BA_ "GenSigSwitchedByIgnition" SG_ 672 BCM2_T_Deckel_Vorne 0;
BA_ "GenSigSendType" SG_ 672 BCM2_TrunkEntrapment_Warn 0;
BA_ "GenSigSwitchedByIgnition" SG_ 672 BCM2_TrunkEntrapment_Warn 0;
BA_ "GenSigSendType" SG_ 672 BCM2_Unterdr_Zuendungsmeldung 3;
BA_ "GenSigSwitchedByIgnition" SG_ 672 BCM2_Unterdr_Zuendungsmeldung 0;
BA_ "GenSigSendType" SG_ 672 BCM_02_BZ 0;
BA_ "GenSigFuncType" SG_ 672 BCM_02_BZ 1;
BA_ "GenSigSwitchedByIgnition" SG_ 672 BCM_02_BZ 0;
BA_ "GenSigSendType" SG_ 672 BCM_02_CRC 0;
BA_ "GenSigFuncType" SG_ 672 BCM_02_CRC 2;
BA_ "GenSigSwitchedByIgnition" SG_ 672 BCM_02_CRC 0;
BA_ "GenSigActiveRepetitions" SG_ 672 BCM_Anf_Aussenwarnung 5;
BA_ "GenSigSendType" SG_ 672 BCM_Anf_Aussenwarnung 4;
BA_ "GenSigSwitchedByIgnition" SG_ 672 BCM_Anf_Aussenwarnung 0;
BA_ "GenSigSendType" SG_ 672 BCM_Aussenwarnung_Konfig 3;
BA_ "GenSigSwitchedByIgnition" SG_ 672 BCM_Aussenwarnung_Konfig 0;
BA_ "GenSigSendType" SG_ 672 BCM_Handbremse_Hinweis 3;
BA_ "GenSigSwitchedByIgnition" SG_ 672 BCM_Handbremse_Hinweis 0;
BA_ "GenSigSendType" SG_ 672 BCM_RLU_Wakeup_Anforderung 0;
BA_ "GenSigSwitchedByIgnition" SG_ 672 BCM_RLU_Wakeup_Anforderung 0;
BA_ "GenSigSendType" SG_ 672 BCM_ValetTaster_Fkts_LED 3;
BA_ "GenSigSwitchedByIgnition" SG_ 672 BCM_ValetTaster_Fkts_LED 0;
BA_ "GenSigActiveRepetitions" SG_ 672 BCM_Waehlhebel_P_Hinweis 5;
BA_ "GenSigSendType" SG_ 672 BCM_Waehlhebel_P_Hinweis 4;
BA_ "GenSigSwitchedByIgnition" SG_ 672 BCM_Waehlhebel_P_Hinweis 0;
BA_ "GenSigSendType" SG_ 672 FA_Hoehenwert_HL_01 3;
BA_ "GenSigStartValue" SG_ 672 FA_Hoehenwert_HL_01 254;
BA_ "Fehlerwert" SG_ 672 FA_Hoehenwert_HL_01 255;
BA_ "GenSigSendType" SG_ 672 FA_Hoehenwert_VL_01 3;
BA_ "GenSigStartValue" SG_ 672 FA_Hoehenwert_VL_01 254;
BA_ "Fehlerwert" SG_ 672 FA_Hoehenwert_VL_01 255;
BA_ "GenSigSendType" SG_ 672 FSH_LED 3;
BA_ "GenSigSwitchedByIgnition" SG_ 672 FSH_LED 0;
BA_ "GenSigActiveRepetitions" SG_ 672 Heckrollo_Privacy_aktiv 25;
BA_ "GenSigSendType" SG_ 672 Heckrollo_Privacy_aktiv 4;
BA_ "GenSigSwitchedByIgnition" SG_ 672 Heckrollo_Privacy_aktiv 0;
BA_ "GenSigActiveRepetitions" SG_ 672 Heckrollo_Verfahrrichtung 25;
BA_ "GenSigSendType" SG_ 672 Heckrollo_Verfahrrichtung 4;
BA_ "GenSigSwitchedByIgnition" SG_ 672 Heckrollo_Verfahrrichtung 0;
BA_ "GenSigSendType" SG_ 672 Heckwischer_Status 3;
BA_ "GenSigSwitchedByIgnition" SG_ 672 Heckwischer_Status 0;
BA_ "GenSigSendType" SG_ 672 HSH_LED 3;
BA_ "GenSigSwitchedByIgnition" SG_ 672 HSH_LED 0;
BA_ "GenSigSendType" SG_ 672 Niveausensor_HL_verbaut 3;
BA_ "GenSigSwitchedByIgnition" SG_ 672 Niveausensor_HL_verbaut 0;
BA_ "GenSigSendType" SG_ 672 Niveausensor_VL_verbaut 3;
BA_ "GenSigSwitchedByIgnition" SG_ 672 Niveausensor_VL_verbaut 0;
BA_ "GenSigActiveRepetitions" SG_ 672 Remote_Rollo_HBFS_hoch 10;
BA_ "GenSigSendType" SG_ 672 Remote_Rollo_HBFS_hoch 4;
BA_ "GenSigSwitchedByIgnition" SG_ 672 Remote_Rollo_HBFS_hoch 0;
BA_ "GenSigActiveRepetitions" SG_ 672 Remote_Rollo_HBFS_tief 10;
BA_ "GenSigSendType" SG_ 672 Remote_Rollo_HBFS_tief 4;
BA_ "GenSigSwitchedByIgnition" SG_ 672 Remote_Rollo_HBFS_tief 0;
BA_ "GenSigActiveRepetitions" SG_ 672 Remote_Rollo_HFS_hoch 10;
BA_ "GenSigSendType" SG_ 672 Remote_Rollo_HFS_hoch 4;
BA_ "GenSigSwitchedByIgnition" SG_ 672 Remote_Rollo_HFS_hoch 0;
BA_ "GenSigActiveRepetitions" SG_ 672 Remote_Rollo_HFS_tief 10;
BA_ "GenSigSendType" SG_ 672 Remote_Rollo_HFS_tief 4;
BA_ "GenSigSwitchedByIgnition" SG_ 672 Remote_Rollo_HFS_tief 0;
BA_ "GenSigSendType" SG_ 672 ZZH_Endlage_oben 3;
BA_ "GenSigSwitchedByIgnition" SG_ 672 ZZH_Endlage_oben 0;
BA_ "GenSigSendType" SG_ 672 ZZH_Endlage_unplausibel 3;
BA_ "GenSigSwitchedByIgnition" SG_ 672 ZZH_Endlage_unplausibel 0;
BA_ "GenSigSendType" SG_ 672 ZZH_Endlage_unten 3;
BA_ "GenSigSwitchedByIgnition" SG_ 672 ZZH_Endlage_unten 0;
BA_ "GenSigSendType" SG_ 2463978607 BCM_RGB_Blau 3;
BA_ "GenSigSwitchedByIgnition" SG_ 2463978607 BCM_RGB_Blau 0;
BA_ "GenSigSendType" SG_ 2463978607 BCM_RGB_Gruen 3;
BA_ "GenSigSwitchedByIgnition" SG_ 2463978607 BCM_RGB_Gruen 0;
BA_ "GenSigSendType" SG_ 2463978607 BCM_RGB_Rot 3;
BA_ "GenSigSwitchedByIgnition" SG_ 2463978607 BCM_RGB_Rot 0;
BA_ "GenSigSendType" SG_ 2589283629 BCM_DC_Batterie_Status 3;
BA_ "GenSigSwitchedByIgnition" SG_ 2589283629 BCM_DC_Batterie_Status 0;
BA_ "GenSigSendType" SG_ 2589283629 BCM_DC_erkannt 3;
BA_ "GenSigSwitchedByIgnition" SG_ 2589283629 BCM_DC_erkannt 0;
BA_ "GenSigSendType" SG_ 2589283629 BCM_DC_ID 3;
BA_ "GenSigSwitchedByIgnition" SG_ 2589283629 BCM_DC_ID 0;
BA_ "GenSigSendType" SG_ 2589283629 BCM_DC_Suchvorgang_Status 3;
BA_ "GenSigSwitchedByIgnition" SG_ 2589283629 BCM_DC_Suchvorgang_Status 0;
BA_ "GenSigSendType" SG_ 1448 BCM1_FlHz_BFS_PWM_A 3;
BA_ "GenSigSwitchedByIgnition" SG_ 1448 BCM1_FlHz_BFS_PWM_A 0;
BA_ "GenSigSendType" SG_ 1448 BCM1_FlHz_BFS_PWM_B 3;
BA_ "GenSigSwitchedByIgnition" SG_ 1448 BCM1_FlHz_BFS_PWM_B 0;
BA_ "GenSigSendType" SG_ 1448 BCM1_FlHz_HBFS_PWM_A 3;
BA_ "GenSigSwitchedByIgnition" SG_ 1448 BCM1_FlHz_HBFS_PWM_A 0;
BA_ "GenSigSendType" SG_ 1448 BCM1_FlHz_HBFS_PWM_B 3;
BA_ "GenSigSwitchedByIgnition" SG_ 1448 BCM1_FlHz_HBFS_PWM_B 0;
BA_ "GenSigSendType" SG_ 1448 BCM1_FlHz_HL_HLR_Anf 3;
BA_ "GenSigSwitchedByIgnition" SG_ 1448 BCM1_FlHz_HL_HLR_Anf 0;
BA_ "GenSigSendType" SG_ 1448 BCM1_FlHz_HR_HLR_Anf 3;
BA_ "GenSigSwitchedByIgnition" SG_ 1448 BCM1_FlHz_HR_HLR_Anf 0;
BA_ "GenSigSendType" SG_ 1448 BCM1_FlHz_Ruhesitz_HLR_Anf 3;
BA_ "GenSigSwitchedByIgnition" SG_ 1448 BCM1_FlHz_Ruhesitz_HLR_Anf 0;
BA_ "GenSigSendType" SG_ 1448 BCM1_FlHz_Stufe_HL 3;
BA_ "GenSigSwitchedByIgnition" SG_ 1448 BCM1_FlHz_Stufe_HL 0;
BA_ "GenSigSendType" SG_ 1448 BCM1_FlHz_Stufe_HR 3;
BA_ "GenSigSwitchedByIgnition" SG_ 1448 BCM1_FlHz_Stufe_HR 0;
BA_ "GenSigSendType" SG_ 1448 BCM1_FlHz_Stufe_VL 3;
BA_ "GenSigSwitchedByIgnition" SG_ 1448 BCM1_FlHz_Stufe_VL 0;
BA_ "GenSigSendType" SG_ 1448 BCM1_FlHz_Stufe_VR 3;
BA_ "GenSigSwitchedByIgnition" SG_ 1448 BCM1_FlHz_Stufe_VR 0;
BA_ "GenSigSendType" SG_ 1448 BCM1_FlHz_VL_HLR_Anf 3;
BA_ "GenSigSwitchedByIgnition" SG_ 1448 BCM1_FlHz_VL_HLR_Anf 0;
BA_ "GenSigSendType" SG_ 1448 BCM1_FlHz_VR_HLR_Anf 3;
BA_ "GenSigSwitchedByIgnition" SG_ 1448 BCM1_FlHz_VR_HLR_Anf 0;
BA_ "GenSigActiveRepetitions" SG_ 961 APS_LED_Status 5;
BA_ "GenSigSendType" SG_ 961 APS_LED_Status 4;
BA_ "GenSigSwitchedByIgnition" SG_ 961 APS_LED_Status 0;
BA_ "Fehlerwert" SG_ 961 APS_LED_Status 3;
BA_ "GenSigActiveRepetitions" SG_ 961 APS_Taster 5;
BA_ "GenSigSendType" SG_ 961 APS_Taster 4;
BA_ "GenSigStartValue" SG_ 961 APS_Taster 2;
BA_ "GenSigSwitchedByIgnition" SG_ 961 APS_Taster 0;
BA_ "Fehlerwert" SG_ 961 APS_Taster 3;
BA_ "GenSigActiveRepetitions" SG_ 961 AVH_LED_Status 5;
BA_ "GenSigSendType" SG_ 961 AVH_LED_Status 4;
BA_ "GenSigSwitchedByIgnition" SG_ 961 AVH_LED_Status 0;
BA_ "Fehlerwert" SG_ 961 AVH_LED_Status 3;
BA_ "GenSigActiveRepetitions" SG_ 961 AVH_Taster 5;
BA_ "GenSigSendType" SG_ 961 AVH_Taster 4;
BA_ "GenSigStartValue" SG_ 961 AVH_Taster 2;
BA_ "GenSigSwitchedByIgnition" SG_ 961 AVH_Taster 0;
BA_ "Fehlerwert" SG_ 961 AVH_Taster 3;
BA_ "GenSigActiveRepetitions" SG_ 961 Display_Taster 5;
BA_ "GenSigSendType" SG_ 961 Display_Taster 4;
BA_ "GenSigStartValue" SG_ 961 Display_Taster 2;
BA_ "GenSigSwitchedByIgnition" SG_ 961 Display_Taster 0;
BA_ "Fehlerwert" SG_ 961 Display_Taster 3;
BA_ "GenSigActiveRepetitions" SG_ 961 Drivesel_1_Taster 5;
BA_ "GenSigSendType" SG_ 961 Drivesel_1_Taster 4;
BA_ "GenSigStartValue" SG_ 961 Drivesel_1_Taster 2;
BA_ "GenSigSwitchedByIgnition" SG_ 961 Drivesel_1_Taster 0;
BA_ "Fehlerwert" SG_ 961 Drivesel_1_Taster 3;
BA_ "GenSigActiveRepetitions" SG_ 961 Drivesel_2_Taster 5;
BA_ "GenSigSendType" SG_ 961 Drivesel_2_Taster 4;
BA_ "GenSigStartValue" SG_ 961 Drivesel_2_Taster 2;
BA_ "GenSigSwitchedByIgnition" SG_ 961 Drivesel_2_Taster 0;
BA_ "Fehlerwert" SG_ 961 Drivesel_2_Taster 3;
BA_ "GenSigActiveRepetitions" SG_ 961 eCall_Taste 5;
BA_ "GenSigSendType" SG_ 961 eCall_Taste 4;
BA_ "GenSigSwitchedByIgnition" SG_ 961 eCall_Taste 0;
BA_ "Fehlerwert" SG_ 961 eCall_Taste 3;
BA_ "GenSigActiveRepetitions" SG_ 961 ESP_Off_Taster 5;
BA_ "GenSigSendType" SG_ 961 ESP_Off_Taster 4;
BA_ "GenSigStartValue" SG_ 961 ESP_Off_Taster 2;
BA_ "GenSigSwitchedByIgnition" SG_ 961 ESP_Off_Taster 0;
BA_ "Fehlerwert" SG_ 961 ESP_Off_Taster 3;
BA_ "GenSigActiveRepetitions" SG_ 961 HDC_LED_Status 5;
BA_ "GenSigSendType" SG_ 961 HDC_LED_Status 4;
BA_ "GenSigSwitchedByIgnition" SG_ 961 HDC_LED_Status 0;
BA_ "Fehlerwert" SG_ 961 HDC_LED_Status 3;
BA_ "GenSigActiveRepetitions" SG_ 961 HDC_Taster 5;
BA_ "GenSigSendType" SG_ 961 HDC_Taster 4;
BA_ "GenSigStartValue" SG_ 961 HDC_Taster 2;
BA_ "GenSigSwitchedByIgnition" SG_ 961 HDC_Taster 0;
BA_ "Fehlerwert" SG_ 961 HDC_Taster 3;
BA_ "GenSigActiveRepetitions" SG_ 961 Heckrollo_2_Taster 5;
BA_ "GenSigSendType" SG_ 961 Heckrollo_2_Taster 4;
BA_ "GenSigStartValue" SG_ 961 Heckrollo_2_Taster 2;
BA_ "GenSigSwitchedByIgnition" SG_ 961 Heckrollo_2_Taster 0;
BA_ "Fehlerwert" SG_ 961 Heckrollo_2_Taster 3;
BA_ "GenSigActiveRepetitions" SG_ 961 Heckrollo_Taster 5;
BA_ "GenSigSendType" SG_ 961 Heckrollo_Taster 4;
BA_ "GenSigStartValue" SG_ 961 Heckrollo_Taster 2;
BA_ "GenSigSwitchedByIgnition" SG_ 961 Heckrollo_Taster 0;
BA_ "Fehlerwert" SG_ 961 Heckrollo_Taster 3;
BA_ "GenSigActiveRepetitions" SG_ 961 LIM_bCall_Taster 5;
BA_ "GenSigSendType" SG_ 961 LIM_bCall_Taster 4;
BA_ "GenSigSwitchedByIgnition" SG_ 961 LIM_bCall_Taster 0;
BA_ "GenSigSendType" SG_ 961 LIM_PAO_Alivesignal 3;
BA_ "GenSigSwitchedByIgnition" SG_ 961 LIM_PAO_Alivesignal 0;
BA_ "GenSigSendType" SG_ 961 LIM_PAO_OFF_Status 3;
BA_ "GenSigSwitchedByIgnition" SG_ 961 LIM_PAO_OFF_Status 0;
BA_ "GenSigSendType" SG_ 961 LIM_PAO_ON_Status 3;
BA_ "GenSigSwitchedByIgnition" SG_ 961 LIM_PAO_ON_Status 0;
BA_ "GenSigSendType" SG_ 961 LIM_PAO_Schriftzug_Status 3;
BA_ "GenSigSwitchedByIgnition" SG_ 961 LIM_PAO_Schriftzug_Status 0;
BA_ "GenSigActiveRepetitions" SG_ 961 LKS_Taster 5;
BA_ "GenSigSendType" SG_ 961 LKS_Taster 4;
BA_ "GenSigStartValue" SG_ 961 LKS_Taster 2;
BA_ "GenSigSwitchedByIgnition" SG_ 961 LKS_Taster 0;
BA_ "Fehlerwert" SG_ 961 LKS_Taster 3;
BA_ "GenSigActiveRepetitions" SG_ 961 PLA_LED_Status 5;
BA_ "GenSigSendType" SG_ 961 PLA_LED_Status 4;
BA_ "GenSigSwitchedByIgnition" SG_ 961 PLA_LED_Status 0;
BA_ "Fehlerwert" SG_ 961 PLA_LED_Status 3;
BA_ "GenSigActiveRepetitions" SG_ 961 PLA_Taster 5;
BA_ "GenSigSendType" SG_ 961 PLA_Taster 4;
BA_ "GenSigStartValue" SG_ 961 PLA_Taster 2;
BA_ "GenSigSwitchedByIgnition" SG_ 961 PLA_Taster 0;
BA_ "Fehlerwert" SG_ 961 PLA_Taster 3;
BA_ "GenSigSendType" SG_ 961 PLA_Taster_Fehler_Roh 3;
BA_ "GenSigSwitchedByIgnition" SG_ 961 PLA_Taster_Fehler_Roh 0;
BA_ "GenSigActiveRepetitions" SG_ 961 Sideview_Taster 5;
BA_ "GenSigSendType" SG_ 961 Sideview_Taster 4;
BA_ "GenSigStartValue" SG_ 961 Sideview_Taster 2;
BA_ "GenSigSwitchedByIgnition" SG_ 961 Sideview_Taster 0;
BA_ "Fehlerwert" SG_ 961 Sideview_Taster 3;
BA_ "GenSigActiveRepetitions" SG_ 961 Spoiler_LED_Status 5;
BA_ "GenSigSendType" SG_ 961 Spoiler_LED_Status 4;
BA_ "GenSigSwitchedByIgnition" SG_ 961 Spoiler_LED_Status 0;
BA_ "Fehlerwert" SG_ 961 Spoiler_LED_Status 3;
BA_ "GenSigActiveRepetitions" SG_ 961 Spoiler_Taster 5;
BA_ "GenSigSendType" SG_ 961 Spoiler_Taster 4;
BA_ "GenSigStartValue" SG_ 961 Spoiler_Taster 2;
BA_ "GenSigSwitchedByIgnition" SG_ 961 Spoiler_Taster 0;
BA_ "Fehlerwert" SG_ 961 Spoiler_Taster 3;
BA_ "GenSigActiveRepetitions" SG_ 961 SWA_Taster 5;
BA_ "GenSigSendType" SG_ 961 SWA_Taster 4;
BA_ "GenSigSwitchedByIgnition" SG_ 961 SWA_Taster 0;
BA_ "Fehlerwert" SG_ 961 SWA_Taster 3;
BA_ "GenSigSendType" SG_ 1432 BCM1_eSound_Taster 3;
BA_ "GenSigStartValue" SG_ 1432 BCM1_eSound_Taster 2;
BA_ "GenSigSwitchedByIgnition" SG_ 1432 BCM1_eSound_Taster 0;
BA_ "Fehlerwert" SG_ 1432 BCM1_eSound_Taster 3;
BA_ "GenSigActiveRepetitions" SG_ 1432 BCM1_NR_Ride_Height_Down_Taster 5;
BA_ "GenSigSendType" SG_ 1432 BCM1_NR_Ride_Height_Down_Taster 4;
BA_ "GenSigStartValue" SG_ 1432 BCM1_NR_Ride_Height_Down_Taster 2;
BA_ "GenSigSwitchedByIgnition" SG_ 1432 BCM1_NR_Ride_Height_Down_Taster 0;
BA_ "Fehlerwert" SG_ 1432 BCM1_NR_Ride_Height_Down_Taster 3;
BA_ "GenSigActiveRepetitions" SG_ 1432 BCM1_NR_Ride_Height_Up_Taster 5;
BA_ "GenSigSendType" SG_ 1432 BCM1_NR_Ride_Height_Up_Taster 4;
BA_ "GenSigStartValue" SG_ 1432 BCM1_NR_Ride_Height_Up_Taster 2;
BA_ "GenSigSwitchedByIgnition" SG_ 1432 BCM1_NR_Ride_Height_Up_Taster 0;
BA_ "Fehlerwert" SG_ 1432 BCM1_NR_Ride_Height_Up_Taster 3;
BA_ "GenSigSendType" SG_ 1432 BCM_BFS_Fernsteuerung_aktiv 3;
BA_ "GenSigSwitchedByIgnition" SG_ 1432 BCM_BFS_Fernsteuerung_aktiv 0;
BA_ "GenSigSendType" SG_ 1432 BCM_BFS_Massage_Taster 3;
BA_ "GenSigSwitchedByIgnition" SG_ 1432 BCM_BFS_Massage_Taster 0;
BA_ "GenSigSendType" SG_ 1432 BCM_BFS_Multif_Taster 3;
BA_ "GenSigSwitchedByIgnition" SG_ 1432 BCM_BFS_Multif_Taster 0;
BA_ "GenSigSendType" SG_ 1432 BCM_BFS_Pneumatik_Verstellung 3;
BA_ "GenSigSwitchedByIgnition" SG_ 1432 BCM_BFS_Pneumatik_Verstellung 0;
BA_ "GenSigSendType" SG_ 1432 BCM_BFS_Programmwippe 3;
BA_ "GenSigSwitchedByIgnition" SG_ 1432 BCM_BFS_Programmwippe 0;
BA_ "GenSigSendType" SG_ 1432 BCM_FS_Massage_Taster 3;
BA_ "GenSigSwitchedByIgnition" SG_ 1432 BCM_FS_Massage_Taster 0;
BA_ "GenSigSendType" SG_ 1432 BCM_FS_Multif_Taster 3;
BA_ "GenSigSwitchedByIgnition" SG_ 1432 BCM_FS_Multif_Taster 0;
BA_ "GenSigSendType" SG_ 1432 BCM_FS_Pneumatik_Verstellung 3;
BA_ "GenSigSwitchedByIgnition" SG_ 1432 BCM_FS_Pneumatik_Verstellung 0;
BA_ "GenSigSendType" SG_ 1432 BCM_FS_Programmwippe 3;
BA_ "GenSigSwitchedByIgnition" SG_ 1432 BCM_FS_Programmwippe 0;
BA_ "GenSigActiveRepetitions" SG_ 1432 BCM_Soundklappe_Taster 5;
BA_ "GenSigSendType" SG_ 1432 BCM_Soundklappe_Taster 4;
BA_ "GenSigSwitchedByIgnition" SG_ 1432 BCM_Soundklappe_Taster 0;
BA_ "GenSigSendType" SG_ 1432 E_Sound_LED_Status 3;
BA_ "GenSigSwitchedByIgnition" SG_ 1432 E_Sound_LED_Status 0;
BA_ "Fehlerwert" SG_ 1432 E_Sound_LED_Status 3;
BA_ "GenSigActiveRepetitions" SG_ 1432 LIM_Rear_Mode 5;
BA_ "GenSigSendType" SG_ 1432 LIM_Rear_Mode 4;
BA_ "GenSigSwitchedByIgnition" SG_ 1432 LIM_Rear_Mode 0;
BA_ "GenSigActiveRepetitions" SG_ 1432 LIM_S_Rollo_hi 5;
BA_ "GenSigSendType" SG_ 1432 LIM_S_Rollo_hi 4;
BA_ "GenSigSwitchedByIgnition" SG_ 1432 LIM_S_Rollo_hi 0;
BA_ "GenSigActiveRepetitions" SG_ 1432 LIM_S_Rollo_vo 5;
BA_ "GenSigSendType" SG_ 1432 LIM_S_Rollo_vo 4;
BA_ "GenSigSwitchedByIgnition" SG_ 1432 LIM_S_Rollo_vo 0;
BA_ "GenSigActiveRepetitions" SG_ 1432 LIM_S_SAD_hi 5;
BA_ "GenSigSendType" SG_ 1432 LIM_S_SAD_hi 4;
BA_ "GenSigSwitchedByIgnition" SG_ 1432 LIM_S_SAD_hi 0;
BA_ "GenSigActiveRepetitions" SG_ 1432 LIM_S_SAD_Vo 5;
BA_ "GenSigSendType" SG_ 1432 LIM_S_SAD_Vo 4;
BA_ "GenSigSwitchedByIgnition" SG_ 1432 LIM_S_SAD_Vo 0;
BA_ "GenSigSendType" SG_ 1432 Pilot_Taster 3;
BA_ "GenSigStartValue" SG_ 1432 Pilot_Taster 2;
BA_ "GenSigSwitchedByIgnition" SG_ 1432 Pilot_Taster 0;
BA_ "Fehlerwert" SG_ 1432 Pilot_Taster 3;
BA_ "GenSigSendType" SG_ 1462 BEB_hi_ResponseError 3;
BA_ "GenSigSwitchedByIgnition" SG_ 1462 BEB_hi_ResponseError 0;
BA_ "Fehlerwert" SG_ 1462 BEB_hi_ResponseError 1;
BA_ "GenSigActiveRepetitions" SG_ 1462 BEB_hi_SAD_Rollo_AutoAuf 5;
BA_ "GenSigSendType" SG_ 1462 BEB_hi_SAD_Rollo_AutoAuf 4;
BA_ "GenSigSwitchedByIgnition" SG_ 1462 BEB_hi_SAD_Rollo_AutoAuf 0;
BA_ "GenSigActiveRepetitions" SG_ 1462 BEB_hi_SAD_Rollo_AutoZu 5;
BA_ "GenSigSendType" SG_ 1462 BEB_hi_SAD_Rollo_AutoZu 4;
BA_ "GenSigSwitchedByIgnition" SG_ 1462 BEB_hi_SAD_Rollo_AutoZu 0;
BA_ "GenSigActiveRepetitions" SG_ 1462 BEB_hi_SAD_Rollo_defekt 5;
BA_ "GenSigSendType" SG_ 1462 BEB_hi_SAD_Rollo_defekt 4;
BA_ "GenSigActiveRepetitions" SG_ 1462 BEB_hi_SAD_Rollo_haengt 5;
BA_ "GenSigSendType" SG_ 1462 BEB_hi_SAD_Rollo_haengt 4;
BA_ "GenSigActiveRepetitions" SG_ 1462 BEB_hi_SAD_Rollo_ManAuf 5;
BA_ "GenSigSendType" SG_ 1462 BEB_hi_SAD_Rollo_ManAuf 4;
BA_ "GenSigSwitchedByIgnition" SG_ 1462 BEB_hi_SAD_Rollo_ManAuf 0;
BA_ "GenSigActiveRepetitions" SG_ 1462 BEB_hi_SAD_Rollo_ManZu 5;
BA_ "GenSigSendType" SG_ 1462 BEB_hi_SAD_Rollo_ManZu 4;
BA_ "GenSigSwitchedByIgnition" SG_ 1462 BEB_hi_SAD_Rollo_ManZu 0;
BA_ "GenSigSendType" SG_ 1462 BEB_hi_T_Lueftung 3;
BA_ "GenSigSendType" SG_ 1462 BEB_hi_T_Lueftung_LZ_links 3;
BA_ "GenSigSendType" SG_ 1462 BEB_hi_T_Lueftung_LZ_rechts 3;
BA_ "GenSigSendType" SG_ 1462 BEB_hi_T_Lueftung_oben 3;
BA_ "GenSigSendType" SG_ 1462 BEB_hi_T_Lueftung_RZ_links 3;
BA_ "GenSigSendType" SG_ 1462 BEB_hi_T_Lueftung_RZ_rechts 3;
BA_ "GenSigSendType" SG_ 1462 BEB_hi_T_Lueftung_unten 3;
BA_ "GenSigSendType" SG_ 1462 BEB_hi_T_SIH_HL 3;
BA_ "GenSigSendType" SG_ 1462 BEB_hi_T_SIH_HR 3;
BA_ "GenSigSendType" SG_ 1462 BEB_hi_T_SIL_HL 3;
BA_ "GenSigSendType" SG_ 1462 BEB_hi_T_SIL_HR 3;
BA_ "GenSigSendType" SG_ 1462 SL1_Heckrollo_Taster 3;
BA_ "GenSigSwitchedByIgnition" SG_ 1462 SL1_Heckrollo_Taster 0;
BA_ "GenSigActiveRepetitions" SG_ 1431 BED_Rollo_vo 3;
BA_ "GenSigSendType" SG_ 1431 BED_Rollo_vo 4;
BA_ "GenSigSwitchedByIgnition" SG_ 1431 BED_Rollo_vo 0;
BA_ "GenSigActiveRepetitions" SG_ 1431 BED_SAD_vo 3;
BA_ "GenSigSendType" SG_ 1431 BED_SAD_vo 4;
BA_ "GenSigSwitchedByIgnition" SG_ 1431 BED_SAD_vo 0;
BA_ "GenSigActiveRepetitions" SG_ 1431 BED_Taster_Fahrwerk 3;
BA_ "GenSigSendType" SG_ 1431 BED_Taster_Fahrwerk 4;
BA_ "GenSigSwitchedByIgnition" SG_ 1431 BED_Taster_Fahrwerk 0;
BA_ "GenSigActiveRepetitions" SG_ 1431 BED_Taster_Lift 3;
BA_ "GenSigSendType" SG_ 1431 BED_Taster_Lift 4;
BA_ "GenSigStartValue" SG_ 1431 BED_Taster_Lift 2;
BA_ "GenSigSwitchedByIgnition" SG_ 1431 BED_Taster_Lift 0;
BA_ "Fehlerwert" SG_ 1431 BED_Taster_Lift 3;
BA_ "GenSigActiveRepetitions" SG_ 1431 BED_Taster_VD_Oeffnen 3;
BA_ "GenSigSendType" SG_ 1431 BED_Taster_VD_Oeffnen 4;
BA_ "GenSigStartValue" SG_ 1431 BED_Taster_VD_Oeffnen 2;
BA_ "GenSigSwitchedByIgnition" SG_ 1431 BED_Taster_VD_Oeffnen 0;
BA_ "Fehlerwert" SG_ 1431 BED_Taster_VD_Oeffnen 3;
BA_ "GenSigActiveRepetitions" SG_ 1431 BED_Taster_VD_Schliessen 3;
BA_ "GenSigSendType" SG_ 1431 BED_Taster_VD_Schliessen 4;
BA_ "GenSigStartValue" SG_ 1431 BED_Taster_VD_Schliessen 2;
BA_ "GenSigSwitchedByIgnition" SG_ 1431 BED_Taster_VD_Schliessen 0;
BA_ "Fehlerwert" SG_ 1431 BED_Taster_VD_Schliessen 3;
BA_ "GenSigActiveRepetitions" SG_ 1431 BED_Taster_Windschott 3;
BA_ "GenSigSendType" SG_ 1431 BED_Taster_Windschott 4;
BA_ "GenSigStartValue" SG_ 1431 BED_Taster_Windschott 2;
BA_ "GenSigSwitchedByIgnition" SG_ 1431 BED_Taster_Windschott 0;
BA_ "Fehlerwert" SG_ 1431 BED_Taster_Windschott 3;
BA_ "GenSigSendType" SG_ 1431 SoSe_SunInt_2D_Li_Dash 0;
BA_ "GenSigStartValue" SG_ 1431 SoSe_SunInt_2D_Li_Dash 254;
BA_ "GenSigSwitchedByIgnition" SG_ 1431 SoSe_SunInt_2D_Li_Dash 0;
BA_ "Fehlerwert" SG_ 1431 SoSe_SunInt_2D_Li_Dash 255;
BA_ "GenSigSendType" SG_ 1431 SoSe_SunInt_2D_Re_Dash 0;
BA_ "GenSigStartValue" SG_ 1431 SoSe_SunInt_2D_Re_Dash 254;
BA_ "GenSigSwitchedByIgnition" SG_ 1431 SoSe_SunInt_2D_Re_Dash 0;
BA_ "Fehlerwert" SG_ 1431 SoSe_SunInt_2D_Re_Dash 255;
BA_ "GenSigActiveRepetitions" SG_ 870 Blinken_li_Fzg_Takt 5;
BA_ "GenSigSendType" SG_ 870 Blinken_li_Fzg_Takt 4;
BA_ "GenSigSwitchedByIgnition" SG_ 870 Blinken_li_Fzg_Takt 0;
BA_ "GenSigActiveRepetitions" SG_ 870 Blinken_li_Kombi_Takt 5;
BA_ "GenSigSendType" SG_ 870 Blinken_li_Kombi_Takt 4;
BA_ "GenSigSwitchedByIgnition" SG_ 870 Blinken_li_Kombi_Takt 0;
BA_ "GenSigActiveRepetitions" SG_ 870 Blinken_re_Fzg_Takt 5;
BA_ "GenSigSendType" SG_ 870 Blinken_re_Fzg_Takt 4;
BA_ "GenSigSwitchedByIgnition" SG_ 870 Blinken_re_Fzg_Takt 0;
BA_ "GenSigActiveRepetitions" SG_ 870 Blinken_re_Kombi_Takt 5;
BA_ "GenSigSendType" SG_ 870 Blinken_re_Kombi_Takt 4;
BA_ "GenSigSwitchedByIgnition" SG_ 870 Blinken_re_Kombi_Takt 0;
BA_ "GenSigActiveRepetitions" SG_ 870 BM_Autobahn 5;
BA_ "GenSigSendType" SG_ 870 BM_Autobahn 4;
BA_ "GenSigSwitchedByIgnition" SG_ 870 BM_Autobahn 0;
BA_ "GenSigActiveRepetitions" SG_ 870 BM_Crash 5;
BA_ "GenSigSendType" SG_ 870 BM_Crash 4;
BA_ "GenSigSwitchedByIgnition" SG_ 870 BM_Crash 0;
BA_ "GenSigActiveRepetitions" SG_ 870 BM_DWA_Alarm 5;
BA_ "GenSigSendType" SG_ 870 BM_DWA_Alarm 4;
BA_ "GenSigSwitchedByIgnition" SG_ 870 BM_DWA_Alarm 0;
BA_ "GenSigActiveRepetitions" SG_ 870 BM_DWA_ein 5;
BA_ "GenSigSendType" SG_ 870 BM_DWA_ein 4;
BA_ "GenSigSwitchedByIgnition" SG_ 870 BM_DWA_ein 0;
BA_ "GenSigActiveRepetitions" SG_ 870 BM_GDO 5;
BA_ "GenSigSendType" SG_ 870 BM_GDO 4;
BA_ "GenSigSwitchedByIgnition" SG_ 870 BM_GDO 0;
BA_ "GenSigActiveRepetitions" SG_ 870 BM_HD_Oeffnung_angelernt 5;
BA_ "GenSigSendType" SG_ 870 BM_HD_Oeffnung_angelernt 4;
BA_ "GenSigSwitchedByIgnition" SG_ 870 BM_HD_Oeffnung_angelernt 0;
BA_ "GenSigActiveRepetitions" SG_ 870 BM_links 5;
BA_ "GenSigSendType" SG_ 870 BM_links 4;
BA_ "GenSigSwitchedByIgnition" SG_ 870 BM_links 0;
BA_ "GenSigActiveRepetitions" SG_ 870 BM_NBA_n_codiert_n_aktiv 5;
BA_ "GenSigSendType" SG_ 870 BM_NBA_n_codiert_n_aktiv 4;
BA_ "GenSigStartValue" SG_ 870 BM_NBA_n_codiert_n_aktiv 1;
BA_ "GenSigSwitchedByIgnition" SG_ 870 BM_NBA_n_codiert_n_aktiv 0;
BA_ "GenSigActiveRepetitions" SG_ 870 BM_NBA_Status 5;
BA_ "GenSigSendType" SG_ 870 BM_NBA_Status 4;
BA_ "GenSigSwitchedByIgnition" SG_ 870 BM_NBA_Status 0;
BA_ "GenSigActiveRepetitions" SG_ 870 BM_Not_Bremsung 5;
BA_ "GenSigSendType" SG_ 870 BM_Not_Bremsung 4;
BA_ "GenSigSwitchedByIgnition" SG_ 870 BM_Not_Bremsung 0;
BA_ "GenSigActiveRepetitions" SG_ 870 BM_Panik 5;
BA_ "GenSigSendType" SG_ 870 BM_Panik 4;
BA_ "GenSigSwitchedByIgnition" SG_ 870 BM_Panik 0;
BA_ "GenSigActiveRepetitions" SG_ 870 BM_PiloPa 5;
BA_ "GenSigSendType" SG_ 870 BM_PiloPa 4;
BA_ "GenSigSwitchedByIgnition" SG_ 870 BM_PiloPa 0;
BA_ "GenSigActiveRepetitions" SG_ 870 BM_Recas 5;
BA_ "GenSigSendType" SG_ 870 BM_Recas 4;
BA_ "GenSigSwitchedByIgnition" SG_ 870 BM_Recas 0;
BA_ "GenSigActiveRepetitions" SG_ 870 BM_rechts 5;
BA_ "GenSigSendType" SG_ 870 BM_rechts 4;
BA_ "GenSigSwitchedByIgnition" SG_ 870 BM_rechts 0;
BA_ "GenSigActiveRepetitions" SG_ 870 BM_Rollenmodus_Blinken 5;
BA_ "GenSigSendType" SG_ 870 BM_Rollenmodus_Blinken 4;
BA_ "GenSigSwitchedByIgnition" SG_ 870 BM_Rollenmodus_Blinken 0;
BA_ "GenSigActiveRepetitions" SG_ 870 BM_Taxi_Notalarm 5;
BA_ "GenSigSendType" SG_ 870 BM_Taxi_Notalarm 4;
BA_ "GenSigSwitchedByIgnition" SG_ 870 BM_Taxi_Notalarm 0;
BA_ "GenSigActiveRepetitions" SG_ 870 BM_Telematik 5;
BA_ "GenSigSendType" SG_ 870 BM_Telematik 4;
BA_ "GenSigSwitchedByIgnition" SG_ 870 BM_Telematik 0;
BA_ "GenSigActiveRepetitions" SG_ 870 BM_Telematik_Abbruchgrund 5;
BA_ "GenSigSendType" SG_ 870 BM_Telematik_Abbruchgrund 4;
BA_ "GenSigSwitchedByIgnition" SG_ 870 BM_Telematik_Abbruchgrund 0;
BA_ "GenSigActiveRepetitions" SG_ 870 BM_Warnblinken 5;
BA_ "GenSigSendType" SG_ 870 BM_Warnblinken 4;
BA_ "GenSigSwitchedByIgnition" SG_ 870 BM_Warnblinken 0;
BA_ "GenSigActiveRepetitions" SG_ 870 BM_WBT_Beleuchtung 5;
BA_ "GenSigSendType" SG_ 870 BM_WBT_Beleuchtung 4;
BA_ "GenSigSwitchedByIgnition" SG_ 870 BM_WBT_Beleuchtung 0;
BA_ "GenSigActiveRepetitions" SG_ 870 BM_Wischblinken 5;
BA_ "GenSigSendType" SG_ 870 BM_Wischblinken 4;
BA_ "GenSigSwitchedByIgnition" SG_ 870 BM_Wischblinken 0;
BA_ "GenSigActiveRepetitions" SG_ 870 BM_ZV_auf 5;
BA_ "GenSigSendType" SG_ 870 BM_ZV_auf 4;
BA_ "GenSigSwitchedByIgnition" SG_ 870 BM_ZV_auf 0;
BA_ "GenSigActiveRepetitions" SG_ 870 BM_ZV_zu 5;
BA_ "GenSigSendType" SG_ 870 BM_ZV_zu 4;
BA_ "GenSigSwitchedByIgnition" SG_ 870 BM_ZV_zu 0;
BA_ "GenSigSendType" SG_ 870 DWA_Alarmquelle 3;
BA_ "GenSigStartValue" SG_ 870 DWA_Alarmquelle 30;
BA_ "GenSigSwitchedByIgnition" SG_ 870 DWA_Alarmquelle 0;
BA_ "Fehlerwert" SG_ 870 DWA_Alarmquelle 31;
BA_ "GenSigSendType" SG_ 401 BMS_01_BZ 0;
BA_ "GenSigFuncType" SG_ 401 BMS_01_BZ 1;
BA_ "GenSigSwitchedByIgnition" SG_ 401 BMS_01_BZ 0;
BA_ "GenSigSendType" SG_ 401 BMS_01_CRC 0;
BA_ "GenSigFuncType" SG_ 401 BMS_01_CRC 2;
BA_ "GenSigSwitchedByIgnition" SG_ 401 BMS_01_CRC 0;
BA_ "GenSigSendType" SG_ 401 BMS_IstSpannung 0;
BA_ "GenSigStartValue" SG_ 401 BMS_IstSpannung 4094;
BA_ "GenSigSwitchedByIgnition" SG_ 401 BMS_IstSpannung 0;
BA_ "Fehlerwert" SG_ 401 BMS_IstSpannung 4095;
BA_ "GenSigSendType" SG_ 401 BMS_IstStrom_02 0;
BA_ "GenSigStartValue" SG_ 401 BMS_IstStrom_02 4094;
BA_ "GenSigSwitchedByIgnition" SG_ 401 BMS_IstStrom_02 0;
BA_ "Fehlerwert" SG_ 401 BMS_IstStrom_02 4095;
BA_ "GenSigSendType" SG_ 401 BMS_IstStrom_02_Offset 0;
BA_ "GenSigSwitchedByIgnition" SG_ 401 BMS_IstStrom_02_Offset 0;
BA_ "GenSigSendType" SG_ 401 BMS_IstStrom_02_OffsetVZ 0;
BA_ "GenSigSwitchedByIgnition" SG_ 401 BMS_IstStrom_02_OffsetVZ 0;
BA_ "GenSigSendType" SG_ 401 BMS_SOC_HiRes 0;
BA_ "GenSigStartValue" SG_ 401 BMS_SOC_HiRes 2046;
BA_ "GenSigSwitchedByIgnition" SG_ 401 BMS_SOC_HiRes 0;
BA_ "Fehlerwert" SG_ 401 BMS_SOC_HiRes 2047;
BA_ "GenSigSendType" SG_ 401 BMS_Spannung_ZwKr 0;
BA_ "GenSigStartValue" SG_ 401 BMS_Spannung_ZwKr 2046;
BA_ "GenSigSwitchedByIgnition" SG_ 401 BMS_Spannung_ZwKr 0;
BA_ "Fehlerwert" SG_ 401 BMS_Spannung_ZwKr 2047;
BA_ "GenSigSendType" SG_ 1482 BMS_07_BZ 0;
BA_ "GenSigFuncType" SG_ 1482 BMS_07_BZ 1;
BA_ "GenSigSwitchedByIgnition" SG_ 1482 BMS_07_BZ 0;
BA_ "GenSigSendType" SG_ 1482 BMS_07_CRC 0;
BA_ "GenSigFuncType" SG_ 1482 BMS_07_CRC 2;
BA_ "GenSigSwitchedByIgnition" SG_ 1482 BMS_07_CRC 0;
BA_ "GenSigSendType" SG_ 1482 BMS_Ausgleichsladung_Anf 0;
BA_ "GenSigSwitchedByIgnition" SG_ 1482 BMS_Ausgleichsladung_Anf 0;
BA_ "GenSigSendType" SG_ 1482 BMS_Balancing_Aktiv 0;
BA_ "GenSigSwitchedByIgnition" SG_ 1482 BMS_Balancing_Aktiv 0;
BA_ "GenSigSendType" SG_ 1482 BMS_Batteriediagnose 3;
BA_ "GenSigStartValue" SG_ 1482 BMS_Batteriediagnose 1;
BA_ "GenSigSwitchedByIgnition" SG_ 1482 BMS_Batteriediagnose 0;
BA_ "Fehlerwert" SG_ 1482 BMS_Batteriediagnose 7;
BA_ "GenSigSendType" SG_ 1482 BMS_Energieinhalt 0;
BA_ "GenSigStartValue" SG_ 1482 BMS_Energieinhalt 2046;
BA_ "GenSigSwitchedByIgnition" SG_ 1482 BMS_Energieinhalt 0;
BA_ "Fehlerwert" SG_ 1482 BMS_Energieinhalt 2047;
BA_ "GenSigSendType" SG_ 1482 BMS_Fehler_KuehlkreislaufLeckage 3;
BA_ "GenSigSwitchedByIgnition" SG_ 1482 BMS_Fehler_KuehlkreislaufLeckage 0;
BA_ "GenSigSendType" SG_ 1482 BMS_Freig_max_Performanz 3;
BA_ "GenSigSwitchedByIgnition" SG_ 1482 BMS_Freig_max_Performanz 0;
BA_ "GenSigSendType" SG_ 1482 BMS_Gesamtst_Spgfreiheit 3;
BA_ "GenSigSwitchedByIgnition" SG_ 1482 BMS_Gesamtst_Spgfreiheit 0;
BA_ "GenSigSendType" SG_ 1482 BMS_KundenWarnung 3;
BA_ "GenSigSwitchedByIgnition" SG_ 1482 BMS_KundenWarnung 0;
BA_ "GenSigSendType" SG_ 1482 BMS_Ladevorgang_aktiv 0;
BA_ "GenSigSwitchedByIgnition" SG_ 1482 BMS_Ladevorgang_aktiv 0;
BA_ "GenSigSendType" SG_ 1482 BMS_MaxEnergieinhalt 0;
BA_ "GenSigStartValue" SG_ 1482 BMS_MaxEnergieinhalt 2046;
BA_ "GenSigSwitchedByIgnition" SG_ 1482 BMS_MaxEnergieinhalt 0;
BA_ "Fehlerwert" SG_ 1482 BMS_MaxEnergieinhalt 2047;
BA_ "GenSigSendType" SG_ 1482 BMS_RIso_Ext 0;
BA_ "GenSigStartValue" SG_ 1482 BMS_RIso_Ext 4094;
BA_ "GenSigSwitchedByIgnition" SG_ 1482 BMS_RIso_Ext 0;
BA_ "Fehlerwert" SG_ 1482 BMS_RIso_Ext 4095;
BA_ "GenSigSendType" SG_ 1111 BMS_14_BZ 0;
BA_ "GenSigFuncType" SG_ 1111 BMS_14_BZ 1;
BA_ "GenSigSwitchedByIgnition" SG_ 1111 BMS_14_BZ 0;
BA_ "GenSigSendType" SG_ 1111 BMS_14_CRC 0;
BA_ "GenSigFuncType" SG_ 1111 BMS_14_CRC 2;
BA_ "GenSigSwitchedByIgnition" SG_ 1111 BMS_14_CRC 0;
BA_ "GenSigSendType" SG_ 1111 BMS_RIso_GND_HVM 0;
BA_ "GenSigStartValue" SG_ 1111 BMS_RIso_GND_HVM 4094;
BA_ "GenSigSwitchedByIgnition" SG_ 1111 BMS_RIso_GND_HVM 0;
BA_ "Fehlerwert" SG_ 1111 BMS_RIso_GND_HVM 4095;
BA_ "GenSigSendType" SG_ 1111 BMS_RIso_GND_HVP 0;
BA_ "GenSigStartValue" SG_ 1111 BMS_RIso_GND_HVP 4094;
BA_ "GenSigSwitchedByIgnition" SG_ 1111 BMS_RIso_GND_HVP 0;
BA_ "Fehlerwert" SG_ 1111 BMS_RIso_GND_HVP 4095;
BA_ "GenSigSendType" SG_ 1111 BMS_Spannung_ZwKr2 0;
BA_ "GenSigStartValue" SG_ 1111 BMS_Spannung_ZwKr2 2046;
BA_ "GenSigSwitchedByIgnition" SG_ 1111 BMS_Spannung_ZwKr2 0;
BA_ "Fehlerwert" SG_ 1111 BMS_Spannung_ZwKr2 2047;
BA_ "GenSigSendType" SG_ 1111 BMS_Warnung_Stuetzung_NV 0;
BA_ "GenSigStartValue" SG_ 1111 BMS_Warnung_Stuetzung_NV 6;
BA_ "GenSigSwitchedByIgnition" SG_ 1111 BMS_Warnung_Stuetzung_NV 0;
BA_ "Fehlerwert" SG_ 1111 BMS_Warnung_Stuetzung_NV 7;
BA_ "GenSigSendType" SG_ 823 CC_Einzelhindernis_01 5;
BA_ "GenSigSendType" SG_ 823 CC_Einzelhindernis_02 5;
BA_ "GenSigSendType" SG_ 823 CC_Einzelhindernis_03 5;
BA_ "GenSigSendType" SG_ 823 CC_Einzelhindernis_04 5;
BA_ "GenSigSendType" SG_ 823 CC_Einzelhindernis_05 5;
BA_ "GenSigSendType" SG_ 823 CC_Einzelhindernis_06 5;
BA_ "GenSigSendType" SG_ 823 CC_Einzelhindernis_07 5;
BA_ "GenSigSendType" SG_ 823 CC_Einzelhindernis_08 5;
BA_ "GenSigSendType" SG_ 824 CC_Strassenkategorie_01 5;
BA_ "GenSigSendType" SG_ 824 CC_Strassenkategorie_02 5;
BA_ "GenSigSendType" SG_ 824 CC_Strassenkategorie_03 5;
BA_ "GenSigSendType" SG_ 824 CC_Strassenkategorie_04 5;
BA_ "GenSigSendType" SG_ 824 CC_Strassenkategorie_05 5;
BA_ "GenSigSendType" SG_ 824 CC_Strassenkategorie_06 5;
BA_ "GenSigSendType" SG_ 824 CC_Strassenkategorie_07 5;
BA_ "GenSigSendType" SG_ 824 CC_Strassenkategorie_08 5;
BA_ "GenSigSendType" SG_ 825 CC_Version_Hindernis 0;
BA_ "GenSigSendType" SG_ 825 CC_Version_Strassenkategorie 0;
BA_ "GenSigSendType" SG_ 901 CHA_Fahrer_Umschaltung 3;
BA_ "GenSigSwitchedByIgnition" SG_ 901 CHA_Fahrer_Umschaltung 0;
BA_ "GenSigSendType" SG_ 901 CHA_Fahrer_Umschaltung_BMA 3;
BA_ "GenSigSwitchedByIgnition" SG_ 901 CHA_Fahrer_Umschaltung_BMA 0;
BA_ "GenSigSendType" SG_ 901 CHA_Ziel_FahrPr_ACC 3;
BA_ "GenSigSwitchedByIgnition" SG_ 901 CHA_Ziel_FahrPr_ACC 0;
BA_ "GenSigSendType" SG_ 901 CHA_Ziel_FahrPr_AFS 3;
BA_ "GenSigSwitchedByIgnition" SG_ 901 CHA_Ziel_FahrPr_AFS 0;
BA_ "GenSigSendType" SG_ 901 CHA_Ziel_FahrPr_AGA 3;
BA_ "GenSigSwitchedByIgnition" SG_ 901 CHA_Ziel_FahrPr_AGA 0;
BA_ "GenSigSendType" SG_ 901 CHA_Ziel_FahrPr_ALR 3;
BA_ "GenSigSwitchedByIgnition" SG_ 901 CHA_Ziel_FahrPr_ALR 0;
BA_ "GenSigSendType" SG_ 901 CHA_Ziel_FahrPr_DR 3;
BA_ "GenSigSwitchedByIgnition" SG_ 901 CHA_Ziel_FahrPr_DR 0;
BA_ "GenSigSendType" SG_ 901 CHA_Ziel_FahrPr_EPS 3;
BA_ "GenSigSwitchedByIgnition" SG_ 901 CHA_Ziel_FahrPr_EPS 0;
BA_ "GenSigSendType" SG_ 901 CHA_Ziel_FahrPr_ESP 3;
BA_ "GenSigSwitchedByIgnition" SG_ 901 CHA_Ziel_FahrPr_ESP 0;
BA_ "GenSigSendType" SG_ 901 CHA_Ziel_FahrPr_Freilauf 3;
BA_ "GenSigSwitchedByIgnition" SG_ 901 CHA_Ziel_FahrPr_Freilauf 0;
BA_ "GenSigSendType" SG_ 901 CHA_Ziel_FahrPr_GE 3;
BA_ "GenSigSwitchedByIgnition" SG_ 901 CHA_Ziel_FahrPr_GE 0;
BA_ "GenSigSendType" SG_ 901 CHA_Ziel_FahrPr_MO 3;
BA_ "GenSigSwitchedByIgnition" SG_ 901 CHA_Ziel_FahrPr_MO 0;
BA_ "GenSigSendType" SG_ 901 CHA_Ziel_FahrPr_MO_BZS 3;
BA_ "GenSigSwitchedByIgnition" SG_ 901 CHA_Ziel_FahrPr_MO_BZS 0;
BA_ "GenSigSendType" SG_ 901 CHA_Ziel_FahrPr_MO_StSt 3;
BA_ "GenSigSwitchedByIgnition" SG_ 901 CHA_Ziel_FahrPr_MO_StSt 0;
BA_ "GenSigSendType" SG_ 901 CHA_Ziel_FahrPr_PreCrash 3;
BA_ "GenSigSwitchedByIgnition" SG_ 901 CHA_Ziel_FahrPr_PreCrash 0;
BA_ "GenSigSendType" SG_ 901 CHA_Ziel_FahrPr_SAK 3;
BA_ "GenSigSwitchedByIgnition" SG_ 901 CHA_Ziel_FahrPr_SAK 0;
BA_ "GenSigSendType" SG_ 901 CHA_Ziel_FahrPr_VAQ 3;
BA_ "GenSigSwitchedByIgnition" SG_ 901 CHA_Ziel_FahrPr_VAQ 0;
BA_ "GenSigSendType" SG_ 902 CHA_Charge_LED 3;
BA_ "GenSigSwitchedByIgnition" SG_ 902 CHA_Charge_LED 0;
BA_ "GenSigSendType" SG_ 902 CHA_Current_Mode 3;
BA_ "GenSigSwitchedByIgnition" SG_ 902 CHA_Current_Mode 0;
BA_ "GenSigSendType" SG_ 902 CHA_Drehschalter_Istmodus 3;
BA_ "GenSigSwitchedByIgnition" SG_ 902 CHA_Drehschalter_Istmodus 0;
BA_ "GenSigSendType" SG_ 902 CHA_Eco_Charisma_LED 3;
BA_ "GenSigSwitchedByIgnition" SG_ 902 CHA_Eco_Charisma_LED 0;
BA_ "GenSigSendType" SG_ 902 CHA_EV_LED 3;
BA_ "GenSigSwitchedByIgnition" SG_ 902 CHA_EV_LED 0;
BA_ "GenSigSendType" SG_ 902 CHA_Fahrer_Umschaltung 3;
BA_ "GenSigSwitchedByIgnition" SG_ 902 CHA_Fahrer_Umschaltung 0;
BA_ "GenSigSendType" SG_ 902 CHA_Kombi_Texte 3;
BA_ "GenSigSwitchedByIgnition" SG_ 902 CHA_Kombi_Texte 0;
BA_ "GenSigSendType" SG_ 902 CHA_Kombi_Texte_02 3;
BA_ "GenSigSwitchedByIgnition" SG_ 902 CHA_Kombi_Texte_02 0;
BA_ "GenSigSendType" SG_ 902 CHA_Offroad_LED 3;
BA_ "GenSigSwitchedByIgnition" SG_ 902 CHA_Offroad_LED 0;
BA_ "Fehlerwert" SG_ 902 CHA_Offroad_LED 3;
BA_ "GenSigSendType" SG_ 902 CHA_Ziel_FahrPr_03_01 3;
BA_ "GenSigSwitchedByIgnition" SG_ 902 CHA_Ziel_FahrPr_03_01 0;
BA_ "GenSigSendType" SG_ 902 CHA_Ziel_FahrPr_03_02 3;
BA_ "GenSigSwitchedByIgnition" SG_ 902 CHA_Ziel_FahrPr_03_02 0;
BA_ "GenSigSendType" SG_ 902 CHA_Ziel_FahrPr_AMB 3;
BA_ "GenSigSwitchedByIgnition" SG_ 902 CHA_Ziel_FahrPr_AMB 0;
BA_ "GenSigSendType" SG_ 902 CHA_Ziel_FahrPr_HSP 3;
BA_ "GenSigSwitchedByIgnition" SG_ 902 CHA_Ziel_FahrPr_HSP 0;
BA_ "GenSigSendType" SG_ 902 CHA_Ziel_FahrPr_IVB 3;
BA_ "GenSigSwitchedByIgnition" SG_ 902 CHA_Ziel_FahrPr_IVB 0;
BA_ "GenSigSendType" SG_ 902 CHA_Ziel_FahrPr_KL 3;
BA_ "GenSigSwitchedByIgnition" SG_ 902 CHA_Ziel_FahrPr_KL 0;
BA_ "GenSigSendType" SG_ 902 CHA_Ziel_FahrPr_RWB 3;
BA_ "GenSigSwitchedByIgnition" SG_ 902 CHA_Ziel_FahrPr_RWB 0;
BA_ "GenSigSendType" SG_ 615 Daempfer_02_BZ 0;
BA_ "GenSigFuncType" SG_ 615 Daempfer_02_BZ 1;
BA_ "GenSigSendType" SG_ 615 Daempfer_02_CRC 0;
BA_ "GenSigFuncType" SG_ 615 Daempfer_02_CRC 2;
BA_ "GenSigSendType" SG_ 615 DR_Charisma_FahrPr 0;
BA_ "GenSigSendType" SG_ 615 DR_Charisma_Status 0;
BA_ "GenSigSendType" SG_ 615 DR_DynAGL_Anf_Entkopplung 0;
BA_ "GenSigSendType" SG_ 615 DR_DynAGL_Anf_im_Leerlauf 0;
BA_ "GenSigSendType" SG_ 615 DR_ESP_Zuschaltung 3;
BA_ "GenSigSendType" SG_ 615 DR_Systemstatus 3;
BA_ "GenSigSendType" SG_ 615 EFP_Niveauzustand_Lift 0;
BA_ "GenSigSwitchedByIgnition" SG_ 615 EFP_Niveauzustand_Lift 0;
BA_ "Fehlerwert" SG_ 615 EFP_Niveauzustand_Lift 5;
BA_ "GenSigSendType" SG_ 615 EFP_Verfuegbarkeit_Lift 0;
BA_ "GenSigSwitchedByIgnition" SG_ 615 EFP_Verfuegbarkeit_Lift 0;
BA_ "GenSigSendType" SG_ 615 EFP_Vorlaufzeit_Lift 0;
BA_ "GenSigSwitchedByIgnition" SG_ 615 EFP_Vorlaufzeit_Lift 0;
BA_ "Fehlerwert" SG_ 615 EFP_Vorlaufzeit_Lift 7;
BA_ "GenSigSwitchedByIgnition" SG_ 2617012992 DEV_BedienDisp_vo_Resp_00_Data 0;
BA_ "GenSigSwitchedByIgnition" SG_ 2617013247 DEV_BedienDisp_vo_Resp_FF_Data 0;
BA_ "GenSigSwitchedByIgnition" SG_ 2617023232 DEV_BedienSG_hi_Resp_00_Data 0;
BA_ "GenSigSwitchedByIgnition" SG_ 2617023487 DEV_BedienSG_hi_Resp_FF_Data 0;
BA_ "GenSigSwitchedByIgnition" SG_ 2617103104 DEV_DDA_Req_00_Data 0;
BA_ "GenSigSwitchedByIgnition" SG_ 2617103359 DEV_DDA_Resp_FF_Data 0;
BA_ "GenSigSwitchedByIgnition" SG_ 2617219613 DEV_ZR_Produktion_1_Rx_1D_Data 0;
BA_ "GenSigSwitchedByIgnition" SG_ 2617219612 DEV_ZR_Produktion_1_Tx_1C_Data 0;
BA_ "GenSigSwitchedByIgnition" SG_ 2617219597 DEV_ZR_Req_0D_Data 0;
BA_ "GenSigSwitchedByIgnition" SG_ 2617219584 DEV_ZR_Resp_00_Data 0;
BA_ "GenSigSwitchedByIgnition" SG_ 2617219614 DEV_ZR_Pwm_Debug_1 0;
BA_ "GenSigSwitchedByIgnition" SG_ 2617219614 DEV_ZR_Pwm_Debug_2 0;
BA_ "GenSigSwitchedByIgnition" SG_ 2617219614 DEV_ZR_Pwm_Debug_3 0;
BA_ "GenSigSwitchedByIgnition" SG_ 2617219614 DEV_ZR_Pwm_Debug_4 0;
BA_ "GenSigSwitchedByIgnition" SG_ 2617219604 DEV_ZR_Tx_14_Data 0;
BA_ "GenSigSwitchedByIgnition" SG_ 2617219605 DEV_ZR_Tx_15_Data 0;
BA_ "GenSigSendType" SG_ 2617219605 MMI_State 3;
BA_ "GenSigSwitchedByIgnition" SG_ 2617219605 MMI_State 0;
BA_ "GenSigSendType" SG_ 2617219605 Reset_Counter 0;
BA_ "GenSigStartValue" SG_ 2617219605 Reset_Counter 254;
BA_ "GenSigSwitchedByIgnition" SG_ 2617219605 Reset_Counter 0;
BA_ "GenSigSendType" SG_ 2617219605 Routeg_aktiv 3;
BA_ "GenSigSwitchedByIgnition" SG_ 2617219605 Routeg_aktiv 0;
BA_ "GenSigSendType" SG_ 2617219605 SI_MOST_Status 3;
BA_ "GenSigSwitchedByIgnition" SG_ 2617219605 SI_MOST_Status 0;
BA_ "GenSigSendType" SG_ 2617219605 Tel_aktiv 3;
BA_ "GenSigSwitchedByIgnition" SG_ 2617219605 Tel_aktiv 0;
BA_ "GenSigSwitchedByIgnition" SG_ 2617219605 Tel_SIM_aktiv 0;
BA_ "GenSigSendType" SG_ 2617219605 ZR_KL_30F 0;
BA_ "GenSigStartValue" SG_ 2617219605 ZR_KL_30F 254;
BA_ "GenSigSwitchedByIgnition" SG_ 2617219605 ZR_KL_30F 0;
BA_ "Fehlerwert" SG_ 2617219605 ZR_KL_30F 255;
BA_ "GenSigSendType" SG_ 2617219605 ZR_LastOn 3;
BA_ "GenSigStartValue" SG_ 2617219605 ZR_LastOn 7;
BA_ "GenSigSwitchedByIgnition" SG_ 2617219605 ZR_LastOn 0;
BA_ "GenSigSendType" SG_ 2617219605 ZR_State_DU_1 3;
BA_ "GenSigSwitchedByIgnition" SG_ 2617219605 ZR_State_DU_1 0;
BA_ "GenSigSendType" SG_ 2617219605 ZR_TempSens 0;
BA_ "GenSigStartValue" SG_ 2617219605 ZR_TempSens 254;
BA_ "GenSigSwitchedByIgnition" SG_ 2617219605 ZR_TempSens 0;
BA_ "Fehlerwert" SG_ 2617219605 ZR_TempSens 255;
BA_ "GenSigSendType" SG_ 2549880610 DIA_SCON1_Req_Data 3;
BA_ "GenSigFuncType" SG_ 2549880610 DIA_SCON1_Req_Data 9;
BA_ "GenSigSwitchedByIgnition" SG_ 2549880610 DIA_SCON1_Req_Data 0;
BA_ "GenSigSendType" SG_ 2550011682 DIA_SCON1_Resp_Data 3;
BA_ "GenSigFuncType" SG_ 2550011682 DIA_SCON1_Resp_Data 9;
BA_ "GenSigSwitchedByIgnition" SG_ 2550011682 DIA_SCON1_Resp_Data 0;
BA_ "GenSigSendType" SG_ 2549880611 DIA_SCON2_Req_Data 3;
BA_ "GenSigFuncType" SG_ 2549880611 DIA_SCON2_Req_Data 9;
BA_ "GenSigSwitchedByIgnition" SG_ 2549880611 DIA_SCON2_Req_Data 0;
BA_ "GenSigSendType" SG_ 2550011683 DIA_SCON2_Resp_Data 3;
BA_ "GenSigFuncType" SG_ 2550011683 DIA_SCON2_Resp_Data 9;
BA_ "GenSigSwitchedByIgnition" SG_ 2550011683 DIA_SCON2_Resp_Data 0;
BA_ "GenSigSendType" SG_ 2549880473 DIA_SD3_Req_Data 3;
BA_ "GenSigFuncType" SG_ 2549880473 DIA_SD3_Req_Data 9;
BA_ "GenSigSwitchedByIgnition" SG_ 2549880473 DIA_SD3_Req_Data 0;
BA_ "GenSigSendType" SG_ 2550011545 DIA_SD3_Resp_Data 3;
BA_ "GenSigFuncType" SG_ 2550011545 DIA_SD3_Resp_Data 9;
BA_ "GenSigSwitchedByIgnition" SG_ 2550011545 DIA_SD3_Resp_Data 0;
BA_ "GenSigSendType" SG_ 2549880474 DIA_SD4_Req_Data 3;
BA_ "GenSigFuncType" SG_ 2549880474 DIA_SD4_Req_Data 9;
BA_ "GenSigSwitchedByIgnition" SG_ 2549880474 DIA_SD4_Req_Data 0;
BA_ "GenSigSendType" SG_ 2550011546 DIA_SD4_Resp_Data 3;
BA_ "GenSigFuncType" SG_ 2550011546 DIA_SD4_Resp_Data 9;
BA_ "GenSigSwitchedByIgnition" SG_ 2550011546 DIA_SD4_Resp_Data 0;
BA_ "GenSigSendType" SG_ 1714 DGN_Verlernzaehler 0;
BA_ "GenSigSwitchedByIgnition" SG_ 1714 DGN_Verlernzaehler 0;
BA_ "GenSigSendType" SG_ 1714 KBI_Kilometerstand 0;
BA_ "GenSigStartValue" SG_ 1714 KBI_Kilometerstand 1048574;
BA_ "GenSigSwitchedByIgnition" SG_ 1714 KBI_Kilometerstand 0;
BA_ "Fehlerwert" SG_ 1714 KBI_Kilometerstand 1048575;
BA_ "GenSigSendType" SG_ 1714 Kombi_02_alt 0;
BA_ "GenSigStartValue" SG_ 1714 Kombi_02_alt 1;
BA_ "GenSigFuncType" SG_ 1714 Kombi_02_alt 5;
BA_ "GenSigSwitchedByIgnition" SG_ 1714 Kombi_02_alt 0;
BA_ "GenSigSendType" SG_ 1714 UH_Jahr 0;
BA_ "GenSigSwitchedByIgnition" SG_ 1714 UH_Jahr 0;
BA_ "GenSigSendType" SG_ 1714 UH_Minute 0;
BA_ "GenSigSwitchedByIgnition" SG_ 1714 UH_Minute 0;
BA_ "GenSigSendType" SG_ 1714 UH_Monat 0;
BA_ "GenSigSwitchedByIgnition" SG_ 1714 UH_Monat 0;
BA_ "Fehlerwert" SG_ 1714 UH_Monat 15;
BA_ "GenSigSendType" SG_ 1714 UH_Sekunde 0;
BA_ "GenSigSwitchedByIgnition" SG_ 1714 UH_Sekunde 0;
BA_ "GenSigSendType" SG_ 1714 UH_Stunde 0;
BA_ "GenSigSwitchedByIgnition" SG_ 1714 UH_Stunde 0;
BA_ "GenSigSendType" SG_ 1714 UH_Tag 0;
BA_ "GenSigSwitchedByIgnition" SG_ 1714 UH_Tag 0;
BA_ "GenSigSendType" SG_ 1714 Uhrzeit_01_alt 0;
BA_ "GenSigStartValue" SG_ 1714 Uhrzeit_01_alt 1;
BA_ "GenSigFuncType" SG_ 1714 Uhrzeit_01_alt 5;
BA_ "GenSigSwitchedByIgnition" SG_ 1714 Uhrzeit_01_alt 0;
BA_ "GenSigSendType" SG_ 1520 BCM1_Stellgroesse_Kl_58s 3;
BA_ "GenSigStartValue" SG_ 1520 BCM1_Stellgroesse_Kl_58s 126;
BA_ "GenSigSwitchedByIgnition" SG_ 1520 BCM1_Stellgroesse_Kl_58s 0;
BA_ "Fehlerwert" SG_ 1520 BCM1_Stellgroesse_Kl_58s 127;
BA_ "GenSigSendType" SG_ 1520 DI_Display_Nachtdesign 3;
BA_ "GenSigSwitchedByIgnition" SG_ 1520 DI_Display_Nachtdesign 0;
BA_ "GenSigSendType" SG_ 1520 DI_Fotosensor 3;
BA_ "GenSigSwitchedByIgnition" SG_ 1520 DI_Fotosensor 0;
BA_ "GenSigSendType" SG_ 1520 DI_KL_58xd 3;
BA_ "GenSigStartValue" SG_ 1520 DI_KL_58xd 254;
BA_ "GenSigSwitchedByIgnition" SG_ 1520 DI_KL_58xd 0;
BA_ "Fehlerwert" SG_ 1520 DI_KL_58xd 255;
BA_ "GenSigSendType" SG_ 1520 DI_KL_58xs 3;
BA_ "GenSigStartValue" SG_ 1520 DI_KL_58xs 126;
BA_ "GenSigSwitchedByIgnition" SG_ 1520 DI_KL_58xs 0;
BA_ "Fehlerwert" SG_ 1520 DI_KL_58xs 127;
BA_ "GenSigSendType" SG_ 1520 DI_KL_58xt 3;
BA_ "GenSigStartValue" SG_ 1520 DI_KL_58xt 126;
BA_ "GenSigSwitchedByIgnition" SG_ 1520 DI_KL_58xt 0;
BA_ "Fehlerwert" SG_ 1520 DI_KL_58xt 127;
BA_ "GenSigSendType" SG_ 420 EA_01_BZ 0;
BA_ "GenSigFuncType" SG_ 420 EA_01_BZ 1;
BA_ "GenSigSendType" SG_ 420 EA_01_CRC 0;
BA_ "GenSigFuncType" SG_ 420 EA_01_CRC 2;
BA_ "GenSigSendType" SG_ 420 EA_Anforderung_HMS 0;
BA_ "GenSigSendType" SG_ 420 EA_eCall_Anf 0;
BA_ "GenSigSwitchedByIgnition" SG_ 420 EA_eCall_Anf 0;
BA_ "GenSigSendType" SG_ 420 EA_Funktionsstatus 0;
BA_ "GenSigSendType" SG_ 420 EA_Gurtstraffer_Anf 0;
BA_ "GenSigSendType" SG_ 420 EA_Parken_beibehalten_HMS 0;
BA_ "GenSigStartValue" SG_ 420 EA_Parken_beibehalten_HMS 2;
BA_ "Fehlerwert" SG_ 420 EA_Parken_beibehalten_HMS 3;
BA_ "GenSigSendType" SG_ 420 EA_Sollbeschleunigung 0;
BA_ "GenSigStartValue" SG_ 420 EA_Sollbeschleunigung 2046;
BA_ "Fehlerwert" SG_ 420 EA_Sollbeschleunigung 2047;
BA_ "GenSigSendType" SG_ 420 EA_Warnruckprofil 0;
BA_REL_ "GenSigTimeoutTime" BU_SG_REL_ BedienDisp_vo SG_ 672 Heckrollo_Privacy_aktiv 2000;
BA_REL_ "GenSigTimeoutTime" BU_SG_REL_ BedienDisp_vo SG_ 1714 DGN_Verlernzaehler 5000;
BA_REL_ "GenSigTimeoutTime" BU_SG_REL_ BedienDisp_vo SG_ 1714 KBI_Kilometerstand 5000;
BA_REL_ "GenSigTimeoutTime" BU_SG_REL_ BedienDisp_vo SG_ 1714 UH_Jahr 5000;
BA_REL_ "GenSigTimeoutTime" BU_SG_REL_ BedienDisp_vo SG_ 1714 UH_Monat 5000;
BA_REL_ "GenSigTimeoutTime" BU_SG_REL_ BedienDisp_vo SG_ 1714 UH_Tag 5000;
BA_REL_ "GenSigTimeoutTime" BU_SG_REL_ BedienDisp_vo SG_ 1714 UH_Stunde 5000;
BA_REL_ "GenSigTimeoutTime" BU_SG_REL_ BedienDisp_vo SG_ 1714 UH_Minute 5000;
BA_REL_ "GenSigTimeoutTime" BU_SG_REL_ BedienDisp_vo SG_ 1714 UH_Sekunde 5000;
BA_REL_ "GenSigTimeoutTime" BU_SG_REL_ BedienDisp_vo SG_ 1714 Uhrzeit_01_alt 5000;
BA_REL_ "GenSigTimeoutTime" BU_SG_REL_ BedienDisp_vo SG_ 1520 DI_KL_58xd 2000;
BA_REL_ "GenSigTimeoutTime" BU_SG_REL_ BedienDisp_vo SG_ 1520 DI_KL_58xs 2000;
BA_REL_ "GenSigTimeoutTime" BU_SG_REL_ BedienDisp_vo SG_ 1520 DI_KL_58xt 2000;
BA_REL_ "GenSigTimeoutTime" BU_SG_REL_ BedienSG_hi SG_ 672 Heckrollo_Verfahrrichtung 2000;
BA_REL_ "GenSigTimeoutTime" BU_SG_REL_ BedienSG_hi SG_ 401 BMS_IstSpannung 1000;
BA_REL_ "GenSigTimeoutTime" BU_SG_REL_ BedienSG_hi SG_ 1714 DGN_Verlernzaehler 5000;
BA_REL_ "GenSigTimeoutTime" BU_SG_REL_ BedienSG_hi SG_ 1714 KBI_Kilometerstand 5000;
BA_REL_ "GenSigTimeoutTime" BU_SG_REL_ BedienSG_hi SG_ 1714 UH_Jahr 5000;
BA_REL_ "GenSigTimeoutTime" BU_SG_REL_ BedienSG_hi SG_ 1714 UH_Monat 5000;
BA_REL_ "GenSigTimeoutTime" BU_SG_REL_ BedienSG_hi SG_ 1714 UH_Tag 5000;
BA_REL_ "GenSigTimeoutTime" BU_SG_REL_ BedienSG_hi SG_ 1714 UH_Stunde 5000;
BA_REL_ "GenSigTimeoutTime" BU_SG_REL_ BedienSG_hi SG_ 1714 UH_Minute 5000;
BA_REL_ "GenSigTimeoutTime" BU_SG_REL_ BedienSG_hi SG_ 1714 UH_Sekunde 5000;
BA_REL_ "GenSigTimeoutTime" BU_SG_REL_ BedienSG_hi SG_ 1520 DI_KL_58xd 2000;
BA_REL_ "GenSigTimeoutTime" BU_SG_REL_ BedienSG_hi SG_ 1520 DI_KL_58xs 2000;
BA_REL_ "GenSigTimeoutTime" BU_SG_REL_ BedienSG_hi SG_ 1520 DI_Display_Nachtdesign 2000;
BA_REL_ "GenSigTimeoutTime" BU_SG_REL_ BedienSG_hi SG_ 1520 DI_KL_58xt 2000;
BA_REL_ "GenSigTimeoutTime" BU_SG_REL_ BedienSG_hi SG_ 1520 DI_Fotosensor 2000;
BA_REL_ "GenSigTimeoutTime" BU_SG_REL_ DDA SG_ 1626 BCM1_MH_Schalter 5000;
BA_REL_ "GenSigTimeoutTime" BU_SG_REL_ DDA SG_ 1714 DGN_Verlernzaehler 5000;
BA_REL_ "GenSigTimeoutTime" BU_SG_REL_ DDA SG_ 1714 KBI_Kilometerstand 5000;
BA_REL_ "GenSigTimeoutTime" BU_SG_REL_ DDA SG_ 1714 UH_Jahr 5000;
BA_REL_ "GenSigTimeoutTime" BU_SG_REL_ DDA SG_ 1714 UH_Monat 5000;
BA_REL_ "GenSigTimeoutTime" BU_SG_REL_ DDA SG_ 1714 UH_Tag 5000;
BA_REL_ "GenSigTimeoutTime" BU_SG_REL_ DDA SG_ 1714 UH_Stunde 5000;
BA_REL_ "GenSigTimeoutTime" BU_SG_REL_ DDA SG_ 1714 UH_Minute 5000;
BA_REL_ "GenSigTimeoutTime" BU_SG_REL_ DDA SG_ 1714 UH_Sekunde 5000;
BA_REL_ "GenSigTimeoutTime" BU_SG_REL_ GurtMikrofon SG_ 1714 DGN_Verlernzaehler 5000;
BA_REL_ "GenSigTimeoutTime" BU_SG_REL_ GurtMikrofon SG_ 1714 KBI_Kilometerstand 5000;
BA_REL_ "GenSigTimeoutTime" BU_SG_REL_ GurtMikrofon SG_ 1714 UH_Jahr 5000;
BA_REL_ "GenSigTimeoutTime" BU_SG_REL_ GurtMikrofon SG_ 1714 UH_Monat 5000;
BA_REL_ "GenSigTimeoutTime" BU_SG_REL_ GurtMikrofon SG_ 1714 UH_Tag 5000;
BA_REL_ "GenSigTimeoutTime" BU_SG_REL_ GurtMikrofon SG_ 1714 UH_Stunde 5000;
BA_REL_ "GenSigTimeoutTime" BU_SG_REL_ GurtMikrofon SG_ 1714 UH_Minute 5000;
BA_REL_ "GenSigTimeoutTime" BU_SG_REL_ GurtMikrofon SG_ 1714 UH_Sekunde 5000;
BA_REL_ "GenSigTimeoutTime" BU_SG_REL_ OTA_FC SG_ 1626 BCM_Bremsbelag_Sensor 5000;
BA_REL_ "GenSigTimeoutTime" BU_SG_REL_ OTA_FC SG_ 1626 BCM_Waschwasser_Sensor 5000;
BA_REL_ "GenSigTimeoutTime" BU_SG_REL_ OTA_FC SG_ 1626 BCM1_MH_Schalter 5000;
BA_REL_ "GenSigTimeoutTime" BU_SG_REL_ OTA_FC SG_ 672 Heckwischer_Status 2000;
BA_REL_ "GenSigTimeoutTime" BU_SG_REL_ OTA_FC SG_ 961 ESP_Off_Taster 2000;
BA_REL_ "GenSigTimeoutTime" BU_SG_REL_ OTA_FC SG_ 961 Spoiler_Taster 2000;
BA_REL_ "GenSigTimeoutTime" BU_SG_REL_ OTA_FC SG_ 401 BMS_IstStrom_02 1000;
BA_REL_ "GenSigTimeoutTime" BU_SG_REL_ OTA_FC SG_ 401 BMS_IstSpannung 1000;
BA_REL_ "GenSigTimeoutTime" BU_SG_REL_ OTA_FC SG_ 401 BMS_Spannung_ZwKr 1000;
BA_REL_ "GenSigTimeoutTime" BU_SG_REL_ OTA_FC SG_ 401 BMS_SOC_HiRes 1000;
BA_REL_ "GenSigTimeoutTime" BU_SG_REL_ OTA_FC SG_ 401 BMS_IstStrom_02_OffsetVZ 1000;
BA_REL_ "GenSigTimeoutTime" BU_SG_REL_ OTA_FC SG_ 401 BMS_IstStrom_02_Offset 1000;
BA_REL_ "GenSigTimeoutTime" BU_SG_REL_ OTA_FC SG_ 1482 BMS_Energieinhalt 5000;
BA_REL_ "GenSigTimeoutTime" BU_SG_REL_ OTA_FC SG_ 1482 BMS_Ladevorgang_aktiv 5000;
BA_REL_ "GenSigTimeoutTime" BU_SG_REL_ OTA_FC SG_ 1482 BMS_MaxEnergieinhalt 5000;
BA_REL_ "GenSigTimeoutTime" BU_SG_REL_ OTA_FC SG_ 901 CHA_Ziel_FahrPr_AGA 5000;
BA_REL_ "GenSigTimeoutTime" BU_SG_REL_ OTA_FC SG_ 901 CHA_Ziel_FahrPr_ACC 5000;
BA_REL_ "GenSigTimeoutTime" BU_SG_REL_ OTA_FC SG_ 901 CHA_Ziel_FahrPr_SAK 5000;
BA_REL_ "GenSigTimeoutTime" BU_SG_REL_ OTA_FC SG_ 902 CHA_Ziel_FahrPr_HSP 5000;
BA_REL_ "GenSigTimeoutTime" BU_SG_REL_ OTA_FC SG_ 902 CHA_Ziel_FahrPr_RWB 5000;
BA_REL_ "GenSigTimeoutTime" BU_SG_REL_ OTA_FC SG_ 902 CHA_Current_Mode 5000;
BA_REL_ "GenSigTimeoutTime" BU_SG_REL_ OTA_FC SG_ 615 DR_Systemstatus 5000;
BA_REL_ "GenSigTimeoutTime" BU_SG_REL_ OTA_FC SG_ 615 DR_Charisma_FahrPr 5000;
BA_REL_ "GenSigTimeoutTime" BU_SG_REL_ OTA_FC SG_ 1714 DGN_Verlernzaehler 5000;
BA_REL_ "GenSigTimeoutTime" BU_SG_REL_ OTA_FC SG_ 1714 KBI_Kilometerstand 5000;
BA_REL_ "GenSigTimeoutTime" BU_SG_REL_ OTA_FC SG_ 1714 UH_Jahr 5000;
BA_REL_ "GenSigTimeoutTime" BU_SG_REL_ OTA_FC SG_ 1714 UH_Monat 5000;
BA_REL_ "GenSigTimeoutTime" BU_SG_REL_ OTA_FC SG_ 1714 UH_Tag 5000;
BA_REL_ "GenSigTimeoutTime" BU_SG_REL_ OTA_FC SG_ 1714 UH_Stunde 5000;
BA_REL_ "GenSigTimeoutTime" BU_SG_REL_ OTA_FC SG_ 1714 UH_Minute 5000;
BA_REL_ "GenSigTimeoutTime" BU_SG_REL_ OTA_FC SG_ 1714 UH_Sekunde 5000;
BA_REL_ "GenSigTimeoutTime" BU_SG_REL_ OTA_FC SG_ 1714 Kombi_02_alt 5000;
BA_REL_ "GenSigTimeoutTime" BU_SG_REL_ OTA_FC SG_ 1714 Uhrzeit_01_alt 5000;
BA_REL_ "GenSigTimeoutTime" BU_SG_REL_ OTA_FC SG_ 1520 DI_KL_58xd 2000;
BA_REL_ "GenSigTimeoutTime" BU_SG_REL_ ZR_High SG_ 1626 BCM_Bremsbelag_Sensor 5000;
BA_REL_ "GenSigTimeoutTime" BU_SG_REL_ ZR_High SG_ 1626 BCM_Bremsfluessigkeit_Sensor 5000;
BA_REL_ "GenSigTimeoutTime" BU_SG_REL_ ZR_High SG_ 1626 BCM_Waschwasser_Sensor 5000;
BA_REL_ "GenSigTimeoutTime" BU_SG_REL_ ZR_High SG_ 1626 BCM_Kuehlmittel_Sensor 5000;
BA_REL_ "GenSigTimeoutTime" BU_SG_REL_ ZR_High SG_ 1626 BCM_Kuehlmittel_Sensor_02 5000;
BA_REL_ "GenSigTimeoutTime" BU_SG_REL_ ZR_High SG_ 1626 BCM_Hybrid_StSt_Taste_Fehler 5000;
BA_REL_ "GenSigTimeoutTime" BU_SG_REL_ ZR_High SG_ 1626 BCM_Hybrid_StartStopp_Taste 5000;
BA_REL_ "GenSigTimeoutTime" BU_SG_REL_ ZR_High SG_ 1626 BCM1_Warnblink_Taster 5000;
BA_REL_ "GenSigTimeoutTime" BU_SG_REL_ ZR_High SG_ 1626 BCM1_Valet_Parking_Taster 5000;
BA_REL_ "GenSigTimeoutTime" BU_SG_REL_ ZR_High SG_ 1626 BCM1_MH_Schalter 5000;
BA_REL_ "GenSigTimeoutTime" BU_SG_REL_ ZR_High SG_ 1626 BCM1_MH_WIV_Schalter 5000;
BA_REL_ "GenSigTimeoutTime" BU_SG_REL_ ZR_High SG_ 1626 BCM1_NV_Taster 5000;
BA_REL_ "GenSigTimeoutTime" BU_SG_REL_ ZR_High SG_ 1626 BCM1_AFS_Lampe 5000;
BA_REL_ "GenSigTimeoutTime" BU_SG_REL_ ZR_High SG_ 1626 BCM1_Reisemodus_Texte 5000;
BA_REL_ "GenSigTimeoutTime" BU_SG_REL_ ZR_High SG_ 1626 BCM1_EasyEntry_Status 5000;
BA_REL_ "GenSigTimeoutTime" BU_SG_REL_ ZR_High SG_ 1626 BCM1_Lenksaeule_aktiv 5000;
BA_REL_ "GenSigTimeoutTime" BU_SG_REL_ ZR_High SG_ 1626 BCM1_St_SW_Diebstahl_links 5000;
BA_REL_ "GenSigTimeoutTime" BU_SG_REL_ ZR_High SG_ 1626 BCM1_St_SW_Diebstahl_rechts 5000;
BA_REL_ "GenSigTimeoutTime" BU_SG_REL_ ZR_High SG_ 672 ZZH_Endlage_oben 2000;
BA_REL_ "GenSigTimeoutTime" BU_SG_REL_ ZR_High SG_ 672 ZZH_Endlage_unten 2000;
BA_REL_ "GenSigTimeoutTime" BU_SG_REL_ ZR_High SG_ 672 BCM_Waehlhebel_P_Hinweis 2000;
BA_REL_ "GenSigTimeoutTime" BU_SG_REL_ ZR_High SG_ 672 BCM_ValetTaster_Fkts_LED 2000;
BA_REL_ "GenSigTimeoutTime" BU_SG_REL_ ZR_High SG_ 672 Heckwischer_Status 2000;
BA_REL_ "GenSigTimeoutTime" BU_SG_REL_ ZR_High SG_ 672 BCM2_P_verriegelt 2000;
BA_REL_ "GenSigTimeoutTime" BU_SG_REL_ ZR_High SG_ 672 FSH_LED 2000;
BA_REL_ "GenSigTimeoutTime" BU_SG_REL_ ZR_High SG_ 672 HSH_LED 2000;
BA_REL_ "GenSigTimeoutTime" BU_SG_REL_ ZR_High SG_ 672 BCM2_Freigabe_Kofferr_Innenentr 2000;
BA_REL_ "GenSigTimeoutTime" BU_SG_REL_ ZR_High SG_ 672 BCM_RLU_Wakeup_Anforderung 2000;
BA_REL_ "GenSigTimeoutTime" BU_SG_REL_ ZR_High SG_ 672 Heckrollo_Privacy_aktiv 2000;
BA_REL_ "GenSigTimeoutTime" BU_SG_REL_ ZR_High SG_ 2463978607 BCM_RGB_Rot 2000;
BA_REL_ "GenSigTimeoutTime" BU_SG_REL_ ZR_High SG_ 2463978607 BCM_RGB_Gruen 2000;
BA_REL_ "GenSigTimeoutTime" BU_SG_REL_ ZR_High SG_ 2463978607 BCM_RGB_Blau 2000;
BA_REL_ "GenSigTimeoutTime" BU_SG_REL_ ZR_High SG_ 2589283629 BCM_DC_Suchvorgang_Status 5000;
BA_REL_ "GenSigTimeoutTime" BU_SG_REL_ ZR_High SG_ 2589283629 BCM_DC_Batterie_Status 5000;
BA_REL_ "GenSigTimeoutTime" BU_SG_REL_ ZR_High SG_ 2589283629 BCM_DC_erkannt 5000;
BA_REL_ "GenSigTimeoutTime" BU_SG_REL_ ZR_High SG_ 1448 BCM1_FlHz_Stufe_HR 5000;
BA_REL_ "GenSigTimeoutTime" BU_SG_REL_ ZR_High SG_ 1448 BCM1_FlHz_Stufe_HL 5000;
BA_REL_ "GenSigTimeoutTime" BU_SG_REL_ ZR_High SG_ 1448 BCM1_FlHz_Stufe_VR 5000;
BA_REL_ "GenSigTimeoutTime" BU_SG_REL_ ZR_High SG_ 1448 BCM1_FlHz_Stufe_VL 5000;
BA_REL_ "GenSigTimeoutTime" BU_SG_REL_ ZR_High SG_ 1448 BCM1_FlHz_Ruhesitz_HLR_Anf 5000;
BA_REL_ "GenSigTimeoutTime" BU_SG_REL_ ZR_High SG_ 1448 BCM1_FlHz_VR_HLR_Anf 5000;
BA_REL_ "GenSigTimeoutTime" BU_SG_REL_ ZR_High SG_ 1448 BCM1_FlHz_VL_HLR_Anf 5000;
BA_REL_ "GenSigTimeoutTime" BU_SG_REL_ ZR_High SG_ 1448 BCM1_FlHz_HL_HLR_Anf 5000;
BA_REL_ "GenSigTimeoutTime" BU_SG_REL_ ZR_High SG_ 1448 BCM1_FlHz_HR_HLR_Anf 5000;
BA_REL_ "GenSigTimeoutTime" BU_SG_REL_ ZR_High SG_ 961 APS_Taster 2000;
BA_REL_ "GenSigTimeoutTime" BU_SG_REL_ ZR_High SG_ 961 PLA_Taster 2000;
BA_REL_ "GenSigTimeoutTime" BU_SG_REL_ ZR_High SG_ 961 ESP_Off_Taster 2000;
BA_REL_ "GenSigTimeoutTime" BU_SG_REL_ ZR_High SG_ 961 HDC_Taster 2000;
BA_REL_ "GenSigTimeoutTime" BU_SG_REL_ ZR_High SG_ 961 AVH_Taster 2000;
BA_REL_ "GenSigTimeoutTime" BU_SG_REL_ ZR_High SG_ 961 Display_Taster 2000;
BA_REL_ "GenSigTimeoutTime" BU_SG_REL_ ZR_High SG_ 961 Heckrollo_Taster 2000;
BA_REL_ "GenSigTimeoutTime" BU_SG_REL_ ZR_High SG_ 961 Spoiler_Taster 2000;
BA_REL_ "GenSigTimeoutTime" BU_SG_REL_ ZR_High SG_ 961 Drivesel_1_Taster 2000;
BA_REL_ "GenSigTimeoutTime" BU_SG_REL_ ZR_High SG_ 961 Drivesel_2_Taster 2000;
BA_REL_ "GenSigTimeoutTime" BU_SG_REL_ ZR_High SG_ 961 Sideview_Taster 2000;
BA_REL_ "GenSigTimeoutTime" BU_SG_REL_ ZR_High SG_ 961 SWA_Taster 2000;
BA_REL_ "GenSigTimeoutTime" BU_SG_REL_ ZR_High SG_ 961 LIM_bCall_Taster 2000;
BA_REL_ "GenSigTimeoutTime" BU_SG_REL_ ZR_High SG_ 961 eCall_Taste 2000;
BA_REL_ "GenSigTimeoutTime" BU_SG_REL_ ZR_High SG_ 1432 Pilot_Taster 5000;
BA_REL_ "GenSigTimeoutTime" BU_SG_REL_ ZR_High SG_ 1432 BCM1_eSound_Taster 5000;
BA_REL_ "GenSigTimeoutTime" BU_SG_REL_ ZR_High SG_ 1432 BCM_FS_Programmwippe 5000;
BA_REL_ "GenSigTimeoutTime" BU_SG_REL_ ZR_High SG_ 1432 BCM_BFS_Programmwippe 5000;
BA_REL_ "GenSigTimeoutTime" BU_SG_REL_ ZR_High SG_ 1432 BCM_FS_Multif_Taster 5000;
BA_REL_ "GenSigTimeoutTime" BU_SG_REL_ ZR_High SG_ 1432 BCM_BFS_Multif_Taster 5000;
BA_REL_ "GenSigTimeoutTime" BU_SG_REL_ ZR_High SG_ 1432 BCM_FS_Massage_Taster 5000;
BA_REL_ "GenSigTimeoutTime" BU_SG_REL_ ZR_High SG_ 1432 BCM_BFS_Massage_Taster 5000;
BA_REL_ "GenSigTimeoutTime" BU_SG_REL_ ZR_High SG_ 1432 BCM_FS_Pneumatik_Verstellung 5000;
BA_REL_ "GenSigTimeoutTime" BU_SG_REL_ ZR_High SG_ 1432 BCM_BFS_Pneumatik_Verstellung 5000;
BA_REL_ "GenSigTimeoutTime" BU_SG_REL_ ZR_High SG_ 1432 BCM1_NR_Ride_Height_Up_Taster 5000;
BA_REL_ "GenSigTimeoutTime" BU_SG_REL_ ZR_High SG_ 1432 BCM1_NR_Ride_Height_Down_Taster 5000;
BA_REL_ "GenSigTimeoutTime" BU_SG_REL_ ZR_High SG_ 1432 LIM_S_Rollo_vo 5000;
BA_REL_ "GenSigTimeoutTime" BU_SG_REL_ ZR_High SG_ 1432 LIM_S_Rollo_hi 5000;
BA_REL_ "GenSigTimeoutTime" BU_SG_REL_ ZR_High SG_ 1432 LIM_S_SAD_Vo 5000;
BA_REL_ "GenSigTimeoutTime" BU_SG_REL_ ZR_High SG_ 1432 LIM_S_SAD_hi 5000;
BA_REL_ "GenSigTimeoutTime" BU_SG_REL_ ZR_High SG_ 1462 BEB_hi_SAD_Rollo_AutoAuf 5000;
BA_REL_ "GenSigTimeoutTime" BU_SG_REL_ ZR_High SG_ 1462 BEB_hi_SAD_Rollo_AutoZu 5000;
BA_REL_ "GenSigTimeoutTime" BU_SG_REL_ ZR_High SG_ 1462 BEB_hi_SAD_Rollo_ManAuf 5000;
BA_REL_ "GenSigTimeoutTime" BU_SG_REL_ ZR_High SG_ 1462 BEB_hi_SAD_Rollo_ManZu 5000;
BA_REL_ "GenSigTimeoutTime" BU_SG_REL_ ZR_High SG_ 1462 BEB_hi_T_SIH_HL 5000;
BA_REL_ "GenSigTimeoutTime" BU_SG_REL_ ZR_High SG_ 1462 BEB_hi_T_SIH_HR 5000;
BA_REL_ "GenSigTimeoutTime" BU_SG_REL_ ZR_High SG_ 1462 BEB_hi_T_SIL_HL 5000;
BA_REL_ "GenSigTimeoutTime" BU_SG_REL_ ZR_High SG_ 1462 BEB_hi_T_SIL_HR 5000;
BA_REL_ "GenSigTimeoutTime" BU_SG_REL_ ZR_High SG_ 1462 SL1_Heckrollo_Taster 5000;
BA_REL_ "GenSigTimeoutTime" BU_SG_REL_ ZR_High SG_ 1462 BEB_hi_SAD_Rollo_defekt 5000;
BA_REL_ "GenSigTimeoutTime" BU_SG_REL_ ZR_High SG_ 1462 BEB_hi_SAD_Rollo_haengt 5000;
BA_REL_ "GenSigTimeoutTime" BU_SG_REL_ ZR_High SG_ 1462 BEB_hi_T_Lueftung 5000;
BA_REL_ "GenSigTimeoutTime" BU_SG_REL_ ZR_High SG_ 1462 BEB_hi_T_Lueftung_oben 5000;
BA_REL_ "GenSigTimeoutTime" BU_SG_REL_ ZR_High SG_ 1462 BEB_hi_T_Lueftung_unten 5000;
BA_REL_ "GenSigTimeoutTime" BU_SG_REL_ ZR_High SG_ 1462 BEB_hi_T_Lueftung_LZ_links 5000;
BA_REL_ "GenSigTimeoutTime" BU_SG_REL_ ZR_High SG_ 1462 BEB_hi_T_Lueftung_LZ_rechts 5000;
BA_REL_ "GenSigTimeoutTime" BU_SG_REL_ ZR_High SG_ 1462 BEB_hi_T_Lueftung_RZ_links 5000;
BA_REL_ "GenSigTimeoutTime" BU_SG_REL_ ZR_High SG_ 1462 BEB_hi_T_Lueftung_RZ_rechts 5000;
BA_REL_ "GenSigTimeoutTime" BU_SG_REL_ ZR_High SG_ 870 BM_ZV_auf 5000;
BA_REL_ "GenSigTimeoutTime" BU_SG_REL_ ZR_High SG_ 870 BM_ZV_zu 5000;
BA_REL_ "GenSigTimeoutTime" BU_SG_REL_ ZR_High SG_ 870 BM_DWA_ein 5000;
BA_REL_ "GenSigTimeoutTime" BU_SG_REL_ ZR_High SG_ 870 BM_DWA_Alarm 5000;
BA_REL_ "GenSigTimeoutTime" BU_SG_REL_ ZR_High SG_ 870 BM_Crash 5000;
BA_REL_ "GenSigTimeoutTime" BU_SG_REL_ ZR_High SG_ 870 BM_Panik 5000;
BA_REL_ "GenSigTimeoutTime" BU_SG_REL_ ZR_High SG_ 870 BM_Not_Bremsung 5000;
BA_REL_ "GenSigTimeoutTime" BU_SG_REL_ ZR_High SG_ 870 BM_Warnblinken 5000;
BA_REL_ "GenSigTimeoutTime" BU_SG_REL_ ZR_High SG_ 870 BM_Taxi_Notalarm 5000;
BA_REL_ "GenSigTimeoutTime" BU_SG_REL_ ZR_High SG_ 870 BM_Telematik 5000;
BA_REL_ "GenSigTimeoutTime" BU_SG_REL_ ZR_High SG_ 870 BM_links 5000;
BA_REL_ "GenSigTimeoutTime" BU_SG_REL_ ZR_High SG_ 870 BM_rechts 5000;
BA_REL_ "GenSigTimeoutTime" BU_SG_REL_ ZR_High SG_ 870 Blinken_li_Fzg_Takt 5000;
BA_REL_ "GenSigTimeoutTime" BU_SG_REL_ ZR_High SG_ 870 Blinken_re_Fzg_Takt 5000;
BA_REL_ "GenSigTimeoutTime" BU_SG_REL_ ZR_High SG_ 870 Blinken_li_Kombi_Takt 5000;
BA_REL_ "GenSigTimeoutTime" BU_SG_REL_ ZR_High SG_ 870 Blinken_re_Kombi_Takt 5000;
BA_REL_ "GenSigTimeoutTime" BU_SG_REL_ ZR_High SG_ 870 BM_WBT_Beleuchtung 5000;
BA_REL_ "GenSigTimeoutTime" BU_SG_REL_ ZR_High SG_ 870 BM_Autobahn 5000;
BA_REL_ "GenSigTimeoutTime" BU_SG_REL_ ZR_High SG_ 870 BM_Recas 5000;
BA_REL_ "GenSigTimeoutTime" BU_SG_REL_ ZR_High SG_ 870 BM_Wischblinken 5000;
BA_REL_ "GenSigTimeoutTime" BU_SG_REL_ ZR_High SG_ 870 BM_PiloPa 5000;
BA_REL_ "GenSigTimeoutTime" BU_SG_REL_ ZR_High SG_ 870 DWA_Alarmquelle 5000;
BA_REL_ "GenSigTimeoutTime" BU_SG_REL_ ZR_High SG_ 401 BMS_IstStrom_02 1000;
BA_REL_ "GenSigTimeoutTime" BU_SG_REL_ ZR_High SG_ 401 BMS_IstSpannung 1000;
BA_REL_ "GenSigTimeoutTime" BU_SG_REL_ ZR_High SG_ 401 BMS_Spannung_ZwKr 1000;
BA_REL_ "GenSigTimeoutTime" BU_SG_REL_ ZR_High SG_ 401 BMS_SOC_HiRes 1000;
BA_REL_ "GenSigTimeoutTime" BU_SG_REL_ ZR_High SG_ 1111 BMS_Spannung_ZwKr2 2000;
BA_REL_ "GenSigTimeoutTime" BU_SG_REL_ ZR_High SG_ 823 CC_MessZeitpunkt_OffsetHindernis 800;
BA_REL_ "GenSigTimeoutTime" BU_SG_REL_ ZR_High SG_ 823 CC_MessZeitpunkt_Hindernis 800;
BA_REL_ "GenSigTimeoutTime" BU_SG_REL_ ZR_High SG_ 823 CC_MessZeitpunkt_ms_Hindernis 800;
BA_REL_ "GenSigTimeoutTime" BU_SG_REL_ ZR_High SG_ 823 CC_Einzelhindernis_01 800;
BA_REL_ "GenSigTimeoutTime" BU_SG_REL_ ZR_High SG_ 823 CC_CF_Einzelhindernis_01 800;
BA_REL_ "GenSigTimeoutTime" BU_SG_REL_ ZR_High SG_ 823 CC_Einzelhindernis_02 800;
BA_REL_ "GenSigTimeoutTime" BU_SG_REL_ ZR_High SG_ 823 CC_CF_Einzelhindernis_02 800;
BA_REL_ "GenSigTimeoutTime" BU_SG_REL_ ZR_High SG_ 823 CC_Einzelhindernis_03 800;
BA_REL_ "GenSigTimeoutTime" BU_SG_REL_ ZR_High SG_ 823 CC_CF_Einzelhindernis_03 800;
BA_REL_ "GenSigTimeoutTime" BU_SG_REL_ ZR_High SG_ 823 CC_Einzelhindernis_04 800;
BA_REL_ "GenSigTimeoutTime" BU_SG_REL_ ZR_High SG_ 823 CC_CF_Einzelhindernis_04 800;
BA_REL_ "GenSigTimeoutTime" BU_SG_REL_ ZR_High SG_ 823 CC_Einzelhindernis_05 800;
BA_REL_ "GenSigTimeoutTime" BU_SG_REL_ ZR_High SG_ 823 CC_CF_Einzelhindernis_05 800;
BA_REL_ "GenSigTimeoutTime" BU_SG_REL_ ZR_High SG_ 823 CC_Einzelhindernis_06 800;
BA_REL_ "GenSigTimeoutTime" BU_SG_REL_ ZR_High SG_ 823 CC_CF_Einzelhindernis_06 800;
BA_REL_ "GenSigTimeoutTime" BU_SG_REL_ ZR_High SG_ 823 CC_Einzelhindernis_07 800;
BA_REL_ "GenSigTimeoutTime" BU_SG_REL_ ZR_High SG_ 823 CC_CF_Einzelhindernis_07 800;
BA_REL_ "GenSigTimeoutTime" BU_SG_REL_ ZR_High SG_ 823 CC_Einzelhindernis_08 800;
BA_REL_ "GenSigTimeoutTime" BU_SG_REL_ ZR_High SG_ 823 CC_CF_Einzelhindernis_08 800;
BA_REL_ "GenSigTimeoutTime" BU_SG_REL_ ZR_High SG_ 824 CC_MessZeitpunkt_OffsetStrZustan 800;
BA_REL_ "GenSigTimeoutTime" BU_SG_REL_ ZR_High SG_ 824 CC_MessZeitpunkt_Strassenzustand 800;
BA_REL_ "GenSigTimeoutTime" BU_SG_REL_ ZR_High SG_ 824 CC_MessZeitpunkt_ms_StrZustand 800;
BA_REL_ "GenSigTimeoutTime" BU_SG_REL_ ZR_High SG_ 824 CC_Strassenkategorie_01 800;
BA_REL_ "GenSigTimeoutTime" BU_SG_REL_ ZR_High SG_ 824 CC_CF_Strassenkategorie_01 800;
BA_REL_ "GenSigTimeoutTime" BU_SG_REL_ ZR_High SG_ 824 CC_Strassenkategorie_02 800;
BA_REL_ "GenSigTimeoutTime" BU_SG_REL_ ZR_High SG_ 824 CC_CF_Strassenkategorie_02 800;
BA_REL_ "GenSigTimeoutTime" BU_SG_REL_ ZR_High SG_ 824 CC_Strassenkategorie_03 800;
BA_REL_ "GenSigTimeoutTime" BU_SG_REL_ ZR_High SG_ 824 CC_CF_Strassenkategorie_03 800;
BA_REL_ "GenSigTimeoutTime" BU_SG_REL_ ZR_High SG_ 824 CC_Strassenkategorie_04 800;
BA_REL_ "GenSigTimeoutTime" BU_SG_REL_ ZR_High SG_ 824 CC_CF_Strassenkategorie_04 800;
BA_REL_ "GenSigTimeoutTime" BU_SG_REL_ ZR_High SG_ 824 CC_Strassenkategorie_05 800;
BA_REL_ "GenSigTimeoutTime" BU_SG_REL_ ZR_High SG_ 824 CC_CF_Strassenkategorie_05 800;
BA_REL_ "GenSigTimeoutTime" BU_SG_REL_ ZR_High SG_ 824 CC_Strassenkategorie_06 800;
BA_REL_ "GenSigTimeoutTime" BU_SG_REL_ ZR_High SG_ 824 CC_CF_Strassenkategorie_06 800;
BA_REL_ "GenSigTimeoutTime" BU_SG_REL_ ZR_High SG_ 824 CC_Strassenkategorie_07 800;
BA_REL_ "GenSigTimeoutTime" BU_SG_REL_ ZR_High SG_ 824 CC_CF_Strassenkategorie_07 800;
BA_REL_ "GenSigTimeoutTime" BU_SG_REL_ ZR_High SG_ 824 CC_Strassenkategorie_08 800;
BA_REL_ "GenSigTimeoutTime" BU_SG_REL_ ZR_High SG_ 824 CC_CF_Strassenkategorie_08 800;
BA_REL_ "GenSigTimeoutTime" BU_SG_REL_ ZR_High SG_ 825 CC_Version_Hindernis 5000;
BA_REL_ "GenSigTimeoutTime" BU_SG_REL_ ZR_High SG_ 825 CC_Version_Strassenkategorie 5000;
BA_REL_ "GenSigTimeoutTime" BU_SG_REL_ ZR_High SG_ 901 CHA_Ziel_FahrPr_AGA 5000;
BA_REL_ "GenSigTimeoutTime" BU_SG_REL_ ZR_High SG_ 901 CHA_Ziel_FahrPr_ESP 5000;
BA_REL_ "GenSigTimeoutTime" BU_SG_REL_ ZR_High SG_ 901 CHA_Ziel_FahrPr_Freilauf 5000;
BA_REL_ "GenSigTimeoutTime" BU_SG_REL_ ZR_High SG_ 901 CHA_Fahrer_Umschaltung 5000;
BA_REL_ "GenSigTimeoutTime" BU_SG_REL_ ZR_High SG_ 901 CHA_Fahrer_Umschaltung_BMA 5000;
BA_REL_ "GenSigTimeoutTime" BU_SG_REL_ ZR_High SG_ 901 CHA_Ziel_FahrPr_MO 5000;
BA_REL_ "GenSigTimeoutTime" BU_SG_REL_ ZR_High SG_ 901 CHA_Ziel_FahrPr_GE 5000;
BA_REL_ "GenSigTimeoutTime" BU_SG_REL_ ZR_High SG_ 901 CHA_Ziel_FahrPr_ALR 5000;
BA_REL_ "GenSigTimeoutTime" BU_SG_REL_ ZR_High SG_ 901 CHA_Ziel_FahrPr_MO_BZS 5000;
BA_REL_ "GenSigTimeoutTime" BU_SG_REL_ ZR_High SG_ 901 CHA_Ziel_FahrPr_DR 5000;
BA_REL_ "GenSigTimeoutTime" BU_SG_REL_ ZR_High SG_ 901 CHA_Ziel_FahrPr_AFS 5000;
BA_REL_ "GenSigTimeoutTime" BU_SG_REL_ ZR_High SG_ 901 CHA_Ziel_FahrPr_PreCrash 5000;
BA_REL_ "GenSigTimeoutTime" BU_SG_REL_ ZR_High SG_ 901 CHA_Ziel_FahrPr_EPS 5000;
BA_REL_ "GenSigTimeoutTime" BU_SG_REL_ ZR_High SG_ 901 CHA_Ziel_FahrPr_ACC 5000;
BA_REL_ "GenSigTimeoutTime" BU_SG_REL_ ZR_High SG_ 901 CHA_Ziel_FahrPr_SAK 5000;
BA_REL_ "GenSigTimeoutTime" BU_SG_REL_ ZR_High SG_ 901 CHA_Ziel_FahrPr_MO_StSt 5000;
BA_REL_ "GenSigTimeoutTime" BU_SG_REL_ ZR_High SG_ 902 CHA_Offroad_LED 5000;
BA_REL_ "GenSigTimeoutTime" BU_SG_REL_ ZR_High SG_ 615 DR_Systemstatus 5000;
BA_REL_ "GenSigTimeoutTime" BU_SG_REL_ ZR_High SG_ 615 DR_ESP_Zuschaltung 5000;
BA_REL_ "GenSigTimeoutTime" BU_SG_REL_ ZR_High SG_ 1714 DGN_Verlernzaehler 5000;
BA_REL_ "GenSigTimeoutTime" BU_SG_REL_ ZR_High SG_ 1714 KBI_Kilometerstand 5000;
BA_REL_ "GenSigTimeoutTime" BU_SG_REL_ ZR_High SG_ 1714 UH_Jahr 5000;
BA_REL_ "GenSigTimeoutTime" BU_SG_REL_ ZR_High SG_ 1714 UH_Monat 5000;
BA_REL_ "GenSigTimeoutTime" BU_SG_REL_ ZR_High SG_ 1714 UH_Tag 5000;
BA_REL_ "GenSigTimeoutTime" BU_SG_REL_ ZR_High SG_ 1714 UH_Stunde 5000;
BA_REL_ "GenSigTimeoutTime" BU_SG_REL_ ZR_High SG_ 1714 UH_Minute 5000;
BA_REL_ "GenSigTimeoutTime" BU_SG_REL_ ZR_High SG_ 1714 UH_Sekunde 5000;
BA_REL_ "GenSigTimeoutTime" BU_SG_REL_ ZR_High SG_ 1520 DI_KL_58xd 2000;
BA_REL_ "GenSigTimeoutTime" BU_SG_REL_ ZR_High SG_ 1520 DI_KL_58xs 2000;
BA_REL_ "GenSigTimeoutTime" BU_SG_REL_ ZR_High SG_ 1520 DI_Display_Nachtdesign 2000;
BA_REL_ "GenSigTimeoutTime" BU_SG_REL_ ZR_High SG_ 420 EA_eCall_Anf 5000;
BA_REL_ "GenSigTimeoutTime" BU_SG_REL_ ZR_High SG_ 420 EA_Funktionsstatus 5000;
BA_REL_ "GenSigTimeoutTime" BU_SG_REL_ ZR_LIMU SG_ 672 BCM_ValetTaster_Fkts_LED 2000;
BA_REL_ "GenSigTimeoutTime" BU_SG_REL_ ZR_LIMU SG_ 961 PLA_Taster 2000;
BA_REL_ "GenSigTimeoutTime" BU_SG_REL_ ZR_LIMU SG_ 961 Display_Taster 2000;
BA_REL_ "GenSigTimeoutTime" BU_SG_REL_ ZR_LIMU SG_ 961 eCall_Taste 2000;
BA_REL_ "GenSigTimeoutTime" BU_SG_REL_ ZR_LIMU SG_ 870 Blinken_li_Kombi_Takt 5000;
BA_REL_ "GenSigTimeoutTime" BU_SG_REL_ ZR_LIMU SG_ 870 Blinken_re_Kombi_Takt 5000;
BA_REL_ "GenSigTimeoutTime" BU_SG_REL_ ZR_LIMU SG_ 870 BM_Autobahn 5000;
BA_REL_ "GenSigTimeoutTime" BU_SG_REL_ ZR_LIMU SG_ 1482 BMS_Ladevorgang_aktiv 5000;
BA_REL_ "GenSigTimeoutTime" BU_SG_REL_ ZR_LIMU SG_ 823 CC_MessZeitpunkt_OffsetHindernis 800;
BA_REL_ "GenSigTimeoutTime" BU_SG_REL_ ZR_LIMU SG_ 823 CC_MessZeitpunkt_Hindernis 800;
BA_REL_ "GenSigTimeoutTime" BU_SG_REL_ ZR_LIMU SG_ 823 CC_MessZeitpunkt_ms_Hindernis 800;
BA_REL_ "GenSigTimeoutTime" BU_SG_REL_ ZR_LIMU SG_ 823 CC_Einzelhindernis_01 800;
BA_REL_ "GenSigTimeoutTime" BU_SG_REL_ ZR_LIMU SG_ 823 CC_CF_Einzelhindernis_01 800;
BA_REL_ "GenSigTimeoutTime" BU_SG_REL_ ZR_LIMU SG_ 823 CC_Einzelhindernis_02 800;
BA_REL_ "GenSigTimeoutTime" BU_SG_REL_ ZR_LIMU SG_ 823 CC_CF_Einzelhindernis_02 800;
BA_REL_ "GenSigTimeoutTime" BU_SG_REL_ ZR_LIMU SG_ 823 CC_Einzelhindernis_03 800;
BA_REL_ "GenSigTimeoutTime" BU_SG_REL_ ZR_LIMU SG_ 823 CC_CF_Einzelhindernis_03 800;
BA_REL_ "GenSigTimeoutTime" BU_SG_REL_ ZR_LIMU SG_ 823 CC_Einzelhindernis_04 800;
BA_REL_ "GenSigTimeoutTime" BU_SG_REL_ ZR_LIMU SG_ 823 CC_CF_Einzelhindernis_04 800;
BA_REL_ "GenSigTimeoutTime" BU_SG_REL_ ZR_LIMU SG_ 823 CC_Einzelhindernis_05 800;
BA_REL_ "GenSigTimeoutTime" BU_SG_REL_ ZR_LIMU SG_ 823 CC_CF_Einzelhindernis_05 800;
BA_REL_ "GenSigTimeoutTime" BU_SG_REL_ ZR_LIMU SG_ 823 CC_Einzelhindernis_06 800;
BA_REL_ "GenSigTimeoutTime" BU_SG_REL_ ZR_LIMU SG_ 823 CC_CF_Einzelhindernis_06 800;
BA_REL_ "GenSigTimeoutTime" BU_SG_REL_ ZR_LIMU SG_ 823 CC_Einzelhindernis_07 800;
BA_REL_ "GenSigTimeoutTime" BU_SG_REL_ ZR_LIMU SG_ 823 CC_CF_Einzelhindernis_07 800;
BA_REL_ "GenSigTimeoutTime" BU_SG_REL_ ZR_LIMU SG_ 823 CC_Einzelhindernis_08 800;
BA_REL_ "GenSigTimeoutTime" BU_SG_REL_ ZR_LIMU SG_ 823 CC_CF_Einzelhindernis_08 800;
BA_REL_ "GenSigTimeoutTime" BU_SG_REL_ ZR_LIMU SG_ 824 CC_MessZeitpunkt_OffsetStrZustan 800;
BA_REL_ "GenSigTimeoutTime" BU_SG_REL_ ZR_LIMU SG_ 824 CC_MessZeitpunkt_Strassenzustand 800;
BA_REL_ "GenSigTimeoutTime" BU_SG_REL_ ZR_LIMU SG_ 824 CC_MessZeitpunkt_ms_StrZustand 800;
BA_REL_ "GenSigTimeoutTime" BU_SG_REL_ ZR_LIMU SG_ 824 CC_Strassenkategorie_01 800;
BA_REL_ "GenSigTimeoutTime" BU_SG_REL_ ZR_LIMU SG_ 824 CC_CF_Strassenkategorie_01 800;
BA_REL_ "GenSigTimeoutTime" BU_SG_REL_ ZR_LIMU SG_ 824 CC_Strassenkategorie_02 800;
BA_REL_ "GenSigTimeoutTime" BU_SG_REL_ ZR_LIMU SG_ 824 CC_CF_Strassenkategorie_02 800;
BA_REL_ "GenSigTimeoutTime" BU_SG_REL_ ZR_LIMU SG_ 824 CC_Strassenkategorie_03 800;
BA_REL_ "GenSigTimeoutTime" BU_SG_REL_ ZR_LIMU SG_ 824 CC_CF_Strassenkategorie_03 800;
BA_REL_ "GenSigTimeoutTime" BU_SG_REL_ ZR_LIMU SG_ 824 CC_Strassenkategorie_04 800;
BA_REL_ "GenSigTimeoutTime" BU_SG_REL_ ZR_LIMU SG_ 824 CC_CF_Strassenkategorie_04 800;
BA_REL_ "GenSigTimeoutTime" BU_SG_REL_ ZR_LIMU SG_ 824 CC_Strassenkategorie_05 800;
BA_REL_ "GenSigTimeoutTime" BU_SG_REL_ ZR_LIMU SG_ 824 CC_CF_Strassenkategorie_05 800;
BA_REL_ "GenSigTimeoutTime" BU_SG_REL_ ZR_LIMU SG_ 824 CC_Strassenkategorie_06 800;
BA_REL_ "GenSigTimeoutTime" BU_SG_REL_ ZR_LIMU SG_ 824 CC_CF_Strassenkategorie_06 800;
BA_REL_ "GenSigTimeoutTime" BU_SG_REL_ ZR_LIMU SG_ 824 CC_Strassenkategorie_07 800;
BA_REL_ "GenSigTimeoutTime" BU_SG_REL_ ZR_LIMU SG_ 824 CC_CF_Strassenkategorie_07 800;
BA_REL_ "GenSigTimeoutTime" BU_SG_REL_ ZR_LIMU SG_ 824 CC_Strassenkategorie_08 800;
BA_REL_ "GenSigTimeoutTime" BU_SG_REL_ ZR_LIMU SG_ 824 CC_CF_Strassenkategorie_08 800;
BA_REL_ "GenSigTimeoutTime" BU_SG_REL_ ZR_LIMU SG_ 825 CC_Version_Hindernis 5000;
BA_REL_ "GenSigTimeoutTime" BU_SG_REL_ ZR_LIMU SG_ 825 CC_Version_Strassenkategorie 5000;
BA_REL_ "GenSigTimeoutTime" BU_SG_REL_ ZR_LIMU SG_ 1714 DGN_Verlernzaehler 5000;
BA_REL_ "GenSigTimeoutTime" BU_SG_REL_ ZR_LIMU SG_ 1714 KBI_Kilometerstand 5000;
BA_REL_ "GenSigTimeoutTime" BU_SG_REL_ ZR_LIMU SG_ 1714 UH_Jahr 5000;
BA_REL_ "GenSigTimeoutTime" BU_SG_REL_ ZR_LIMU SG_ 1714 UH_Monat 5000;
BA_REL_ "GenSigTimeoutTime" BU_SG_REL_ ZR_LIMU SG_ 1714 UH_Tag 5000;
BA_REL_ "GenSigTimeoutTime" BU_SG_REL_ ZR_LIMU SG_ 1714 UH_Stunde 5000;
BA_REL_ "GenSigTimeoutTime" BU_SG_REL_ ZR_LIMU SG_ 1714 UH_Minute 5000;
BA_REL_ "GenSigTimeoutTime" BU_SG_REL_ ZR_LIMU SG_ 1714 UH_Sekunde 5000;
BA_REL_ "GenSigTimeoutTime" BU_SG_REL_ ZR_LIMU SG_ 1714 Kombi_02_alt 5000;
BA_REL_ "GenSigTimeoutTime" BU_SG_REL_ ZR_LIMU SG_ 1714 Uhrzeit_01_alt 5000;
BA_REL_ "GenSigTimeoutTime" BU_SG_REL_ ZR_LIMU SG_ 1520 DI_KL_58xd 2000;
BA_REL_ "GenSigTimeoutTime" BU_SG_REL_ ZR_LIMU SG_ 1520 DI_KL_58xs 2000;
BA_REL_ "GenSigTimeoutTime" BU_SG_REL_ ZR_LIMU SG_ 1520 DI_Display_Nachtdesign 2000;
BA_REL_ "GenSigTimeoutTime" BU_SG_REL_ ZR_LIMU SG_ 1520 DI_KL_58xt 2000;
BA_REL_ "GenSigTimeoutTime" BU_SG_REL_ ZR_LIMU SG_ 1520 DI_Fotosensor 2000;
BA_REL_ "GenSigTimeoutTime" BU_SG_REL_ ZR_LIMU SG_ 1520 BCM1_Stellgroesse_Kl_58s 2000;
BA_REL_ "GenSigTimeoutTime" BU_SG_REL_ ZR_MIB_TOP_ab_Gen3 SG_ 672 BCM_ValetTaster_Fkts_LED 2000;
BA_REL_ "GenSigTimeoutTime" BU_SG_REL_ ZR_MIB_TOP_ab_Gen3 SG_ 961 PLA_Taster 2000;
BA_REL_ "GenSigTimeoutTime" BU_SG_REL_ ZR_MIB_TOP_ab_Gen3 SG_ 961 Display_Taster 2000;
BA_REL_ "GenSigTimeoutTime" BU_SG_REL_ ZR_MIB_TOP_ab_Gen3 SG_ 961 eCall_Taste 2000;
BA_REL_ "GenSigTimeoutTime" BU_SG_REL_ ZR_MIB_TOP_ab_Gen3 SG_ 870 Blinken_li_Kombi_Takt 5000;
BA_REL_ "GenSigTimeoutTime" BU_SG_REL_ ZR_MIB_TOP_ab_Gen3 SG_ 870 Blinken_re_Kombi_Takt 5000;
BA_REL_ "GenSigTimeoutTime" BU_SG_REL_ ZR_MIB_TOP_ab_Gen3 SG_ 870 BM_Autobahn 5000;
BA_REL_ "GenSigTimeoutTime" BU_SG_REL_ ZR_MIB_TOP_ab_Gen3 SG_ 1482 BMS_Ladevorgang_aktiv 5000;
BA_REL_ "GenSigTimeoutTime" BU_SG_REL_ ZR_MIB_TOP_ab_Gen3 SG_ 823 CC_MessZeitpunkt_OffsetHindernis 800;
BA_REL_ "GenSigTimeoutTime" BU_SG_REL_ ZR_MIB_TOP_ab_Gen3 SG_ 823 CC_MessZeitpunkt_Hindernis 800;
BA_REL_ "GenSigTimeoutTime" BU_SG_REL_ ZR_MIB_TOP_ab_Gen3 SG_ 823 CC_MessZeitpunkt_ms_Hindernis 800;
BA_REL_ "GenSigTimeoutTime" BU_SG_REL_ ZR_MIB_TOP_ab_Gen3 SG_ 823 CC_Einzelhindernis_01 800;
BA_REL_ "GenSigTimeoutTime" BU_SG_REL_ ZR_MIB_TOP_ab_Gen3 SG_ 823 CC_CF_Einzelhindernis_01 800;
BA_REL_ "GenSigTimeoutTime" BU_SG_REL_ ZR_MIB_TOP_ab_Gen3 SG_ 823 CC_Einzelhindernis_02 800;
BA_REL_ "GenSigTimeoutTime" BU_SG_REL_ ZR_MIB_TOP_ab_Gen3 SG_ 823 CC_CF_Einzelhindernis_02 800;
BA_REL_ "GenSigTimeoutTime" BU_SG_REL_ ZR_MIB_TOP_ab_Gen3 SG_ 823 CC_Einzelhindernis_03 800;
BA_REL_ "GenSigTimeoutTime" BU_SG_REL_ ZR_MIB_TOP_ab_Gen3 SG_ 823 CC_CF_Einzelhindernis_03 800;
BA_REL_ "GenSigTimeoutTime" BU_SG_REL_ ZR_MIB_TOP_ab_Gen3 SG_ 823 CC_Einzelhindernis_04 800;
BA_REL_ "GenSigTimeoutTime" BU_SG_REL_ ZR_MIB_TOP_ab_Gen3 SG_ 823 CC_CF_Einzelhindernis_04 800;
BA_REL_ "GenSigTimeoutTime" BU_SG_REL_ ZR_MIB_TOP_ab_Gen3 SG_ 823 CC_Einzelhindernis_05 800;
BA_REL_ "GenSigTimeoutTime" BU_SG_REL_ ZR_MIB_TOP_ab_Gen3 SG_ 823 CC_CF_Einzelhindernis_05 800;
BA_REL_ "GenSigTimeoutTime" BU_SG_REL_ ZR_MIB_TOP_ab_Gen3 SG_ 823 CC_Einzelhindernis_06 800;
BA_REL_ "GenSigTimeoutTime" BU_SG_REL_ ZR_MIB_TOP_ab_Gen3 SG_ 823 CC_CF_Einzelhindernis_06 800;
BA_REL_ "GenSigTimeoutTime" BU_SG_REL_ ZR_MIB_TOP_ab_Gen3 SG_ 823 CC_Einzelhindernis_07 800;
BA_REL_ "GenSigTimeoutTime" BU_SG_REL_ ZR_MIB_TOP_ab_Gen3 SG_ 823 CC_CF_Einzelhindernis_07 800;
BA_REL_ "GenSigTimeoutTime" BU_SG_REL_ ZR_MIB_TOP_ab_Gen3 SG_ 823 CC_Einzelhindernis_08 800;
BA_REL_ "GenSigTimeoutTime" BU_SG_REL_ ZR_MIB_TOP_ab_Gen3 SG_ 823 CC_CF_Einzelhindernis_08 800;
BA_REL_ "GenSigTimeoutTime" BU_SG_REL_ ZR_MIB_TOP_ab_Gen3 SG_ 824 CC_MessZeitpunkt_OffsetStrZustan 800;
BA_REL_ "GenSigTimeoutTime" BU_SG_REL_ ZR_MIB_TOP_ab_Gen3 SG_ 824 CC_MessZeitpunkt_Strassenzustand 800;
BA_REL_ "GenSigTimeoutTime" BU_SG_REL_ ZR_MIB_TOP_ab_Gen3 SG_ 824 CC_MessZeitpunkt_ms_StrZustand 800;
BA_REL_ "GenSigTimeoutTime" BU_SG_REL_ ZR_MIB_TOP_ab_Gen3 SG_ 824 CC_Strassenkategorie_01 800;
BA_REL_ "GenSigTimeoutTime" BU_SG_REL_ ZR_MIB_TOP_ab_Gen3 SG_ 824 CC_CF_Strassenkategorie_01 800;
BA_REL_ "GenSigTimeoutTime" BU_SG_REL_ ZR_MIB_TOP_ab_Gen3 SG_ 824 CC_Strassenkategorie_02 800;
BA_REL_ "GenSigTimeoutTime" BU_SG_REL_ ZR_MIB_TOP_ab_Gen3 SG_ 824 CC_CF_Strassenkategorie_02 800;
BA_REL_ "GenSigTimeoutTime" BU_SG_REL_ ZR_MIB_TOP_ab_Gen3 SG_ 824 CC_Strassenkategorie_03 800;
BA_REL_ "GenSigTimeoutTime" BU_SG_REL_ ZR_MIB_TOP_ab_Gen3 SG_ 824 CC_CF_Strassenkategorie_03 800;
BA_REL_ "GenSigTimeoutTime" BU_SG_REL_ ZR_MIB_TOP_ab_Gen3 SG_ 824 CC_Strassenkategorie_04 800;
BA_REL_ "GenSigTimeoutTime" BU_SG_REL_ ZR_MIB_TOP_ab_Gen3 SG_ 824 CC_CF_Strassenkategorie_04 800;
BA_REL_ "GenSigTimeoutTime" BU_SG_REL_ ZR_MIB_TOP_ab_Gen3 SG_ 824 CC_Strassenkategorie_05 800;
BA_REL_ "GenSigTimeoutTime" BU_SG_REL_ ZR_MIB_TOP_ab_Gen3 SG_ 824 CC_CF_Strassenkategorie_05 800;
BA_REL_ "GenSigTimeoutTime" BU_SG_REL_ ZR_MIB_TOP_ab_Gen3 SG_ 824 CC_Strassenkategorie_06 800;
BA_REL_ "GenSigTimeoutTime" BU_SG_REL_ ZR_MIB_TOP_ab_Gen3 SG_ 824 CC_CF_Strassenkategorie_06 800;
BA_REL_ "GenSigTimeoutTime" BU_SG_REL_ ZR_MIB_TOP_ab_Gen3 SG_ 824 CC_Strassenkategorie_07 800;
BA_REL_ "GenSigTimeoutTime" BU_SG_REL_ ZR_MIB_TOP_ab_Gen3 SG_ 824 CC_CF_Strassenkategorie_07 800;
BA_REL_ "GenSigTimeoutTime" BU_SG_REL_ ZR_MIB_TOP_ab_Gen3 SG_ 824 CC_Strassenkategorie_08 800;
BA_REL_ "GenSigTimeoutTime" BU_SG_REL_ ZR_MIB_TOP_ab_Gen3 SG_ 824 CC_CF_Strassenkategorie_08 800;
BA_REL_ "GenSigTimeoutTime" BU_SG_REL_ ZR_MIB_TOP_ab_Gen3 SG_ 825 CC_Version_Hindernis 5000;
BA_REL_ "GenSigTimeoutTime" BU_SG_REL_ ZR_MIB_TOP_ab_Gen3 SG_ 825 CC_Version_Strassenkategorie 5000;
BA_REL_ "GenSigTimeoutTime" BU_SG_REL_ ZR_MIB_TOP_ab_Gen3 SG_ 1714 DGN_Verlernzaehler 5000;
BA_REL_ "GenSigTimeoutTime" BU_SG_REL_ ZR_MIB_TOP_ab_Gen3 SG_ 1714 KBI_Kilometerstand 5000;
BA_REL_ "GenSigTimeoutTime" BU_SG_REL_ ZR_MIB_TOP_ab_Gen3 SG_ 1714 UH_Jahr 5000;
BA_REL_ "GenSigTimeoutTime" BU_SG_REL_ ZR_MIB_TOP_ab_Gen3 SG_ 1714 UH_Monat 5000;
BA_REL_ "GenSigTimeoutTime" BU_SG_REL_ ZR_MIB_TOP_ab_Gen3 SG_ 1714 UH_Tag 5000;
BA_REL_ "GenSigTimeoutTime" BU_SG_REL_ ZR_MIB_TOP_ab_Gen3 SG_ 1714 UH_Stunde 5000;
BA_REL_ "GenSigTimeoutTime" BU_SG_REL_ ZR_MIB_TOP_ab_Gen3 SG_ 1714 UH_Minute 5000;
BA_REL_ "GenSigTimeoutTime" BU_SG_REL_ ZR_MIB_TOP_ab_Gen3 SG_ 1714 UH_Sekunde 5000;
BA_REL_ "GenSigTimeoutTime" BU_SG_REL_ ZR_MIB_TOP_ab_Gen3 SG_ 1714 Kombi_02_alt 5000;
BA_REL_ "GenSigTimeoutTime" BU_SG_REL_ ZR_MIB_TOP_ab_Gen3 SG_ 1714 Uhrzeit_01_alt 5000;
BA_REL_ "GenSigTimeoutTime" BU_SG_REL_ ZR_MIB_TOP_ab_Gen3 SG_ 1520 DI_KL_58xd 2000;
BA_REL_ "GenSigTimeoutTime" BU_SG_REL_ ZR_MIB_TOP_ab_Gen3 SG_ 1520 DI_KL_58xs 2000;
BA_REL_ "GenSigTimeoutTime" BU_SG_REL_ ZR_MIB_TOP_ab_Gen3 SG_ 1520 DI_Display_Nachtdesign 2000;
BA_REL_ "GenSigTimeoutTime" BU_SG_REL_ ZR_Standard SG_ 672 BCM_ValetTaster_Fkts_LED 2000;
BA_REL_ "GenSigTimeoutTime" BU_SG_REL_ ZR_Standard SG_ 672 BCM_RLU_Wakeup_Anforderung 2000;
BA_REL_ "GenSigTimeoutTime" BU_SG_REL_ ZR_Standard SG_ 961 PLA_Taster 2000;
BA_REL_ "GenSigTimeoutTime" BU_SG_REL_ ZR_Standard SG_ 961 Display_Taster 2000;
BA_REL_ "GenSigTimeoutTime" BU_SG_REL_ ZR_Standard SG_ 870 Blinken_li_Kombi_Takt 5000;
BA_REL_ "GenSigTimeoutTime" BU_SG_REL_ ZR_Standard SG_ 870 Blinken_re_Kombi_Takt 5000;
BA_REL_ "GenSigTimeoutTime" BU_SG_REL_ ZR_Standard SG_ 1714 DGN_Verlernzaehler 5000;
BA_REL_ "GenSigTimeoutTime" BU_SG_REL_ ZR_Standard SG_ 1714 KBI_Kilometerstand 5000;
BA_REL_ "GenSigTimeoutTime" BU_SG_REL_ ZR_Standard SG_ 1714 UH_Jahr 5000;
BA_REL_ "GenSigTimeoutTime" BU_SG_REL_ ZR_Standard SG_ 1714 UH_Monat 5000;
BA_REL_ "GenSigTimeoutTime" BU_SG_REL_ ZR_Standard SG_ 1714 UH_Tag 5000;
BA_REL_ "GenSigTimeoutTime" BU_SG_REL_ ZR_Standard SG_ 1714 UH_Stunde 5000;
BA_REL_ "GenSigTimeoutTime" BU_SG_REL_ ZR_Standard SG_ 1714 UH_Minute 5000;
BA_REL_ "GenSigTimeoutTime" BU_SG_REL_ ZR_Standard SG_ 1714 UH_Sekunde 5000;
BA_REL_ "GenSigTimeoutTime" BU_SG_REL_ ZR_Standard SG_ 1520 DI_KL_58xd 2000;
BA_REL_ "GenSigTimeoutTime" BU_SG_REL_ ZR_Standard SG_ 1520 DI_KL_58xs 2000;
BA_REL_ "GenSigTimeoutTime" BU_SG_REL_ ZR_Standard SG_ 1520 DI_Display_Nachtdesign 2000;
VAL_ 1626 BCM_Bremsbelag_Sensor 0 "OK" 1 "Bremsbelag_unter_min" ;
VAL_ 1626 BCM_Bremsfluessigkeit_Sensor 0 "OK" 1 "Bremsfluessigkeit_unter_min" ;
VAL_ 1626 BCM1_Licht_Warn 0 "OK" 1 "Lichtwarnung_aktiv" ;
VAL_ 1626 BCM_Waschwasser_Sensor 0 "OK" 1 "Waschwasser_unter_min" ;
VAL_ 1626 BCM_Kuehlmittel_Sensor 0 "OK" 1 "Kuehlmittel_unter_min" ;
VAL_ 1626 BCM1_Kl_15_HW_erkannt 1 "Klemme 15 erkannt" ;
VAL_ 1626 BCM1_Kl_15_Sig_HW_erkannt 0 "KL15_HW_Signal_von_BCM1_nicht_erkannt" 1 "KL15_HW_Signal_von_BCM1_erkannt" ;
VAL_ 1626 BCM_Kuehlmittel_Sensor_02 0 "OK" 1 "Kuehlmittel_unter_min" ;
VAL_ 1626 BCM1_Hinweis_Lichtnachlauf 0 "inaktiv" 1 "aktiv" ;
VAL_ 1626 BCM_Offroad_Taste 0 "Taster_nicht_betaetigt" 1 "Taster_betaetigt" ;
VAL_ 1626 BCM_Hybrid_StSt_Taste_Fehler 0 "kein_Fehler_StSt_Taster" 1 "Fehler_StSt_Taster" ;
VAL_ 1626 BCM_Hybrid_StartStopp_Taste 0 "nicht_betaetigt" 1 "betaetigt" ;
VAL_ 1626 BCM1_Warnblink_Taster 0 "nicht_betaetigt" 1 "betaetigt" ;
VAL_ 1626 BCM1_Valet_Parking_Taster 0 "nicht_betaetigt" 1 "betaetigt" ;
VAL_ 1626 BCM1_LDS_Stellung 0 "Init" 1 "Stellung_0" 2 "Auto" 3 "Standlicht" 4 "Abblendlicht" 7 "Fehler" ;
VAL_ 1626 BCM1_Rueckfahrlicht_Schalter 0 "nicht_betaetigt" 1 "betaetigt" ;
VAL_ 1626 BCM1_MH_Schalter 0 "MH_geschlossen" 1 "MH_offen" ;
VAL_ 1626 BCM1_MH_WIV_Schalter 0 "MH_geschlossen" 1 "MH_offen" ;
VAL_ 1626 BCM_Eco_Charisma_Taste 0 "nicht_betaetigt" 1 "betaetigt" ;
VAL_ 1626 BCM1_NV_Taster 0 "Taster_nicht_betaetigt" 1 "Taster_betaetigt" ;
VAL_ 1626 BCM1_AFS_Lampe 0 "Aus" 1 "Ein" ;
VAL_ 1626 BCM1_Reisemodus_Texte 0 "keine_Anzeige" 1 "Umschaltung_auf_Linksverkehr_aktiv" 2 "Umschaltung_auf_Rechtsverkehr_aktiv" ;
VAL_ 1626 BCM1_Lichtwarn_Texte 0 "keine_Warnung" 1 "Standlichtwarnung" 2 "Parklichtwarnung" 3 "Nebelschlusslichtwarnung" ;
VAL_ 1626 Gong_TFL_Umschaltung 0 "kein_Gong" 1 "Gong_einmalig" ;
VAL_ 1626 UGDO_Function_01 0 "LED Function" 1 "Transceiver locked" 2 "reserviert" 3 "reserviert" 4 "Successful learned" 5 "reserviert" 6 "Timeout learning" 7 "Fehler" ;
VAL_ 1626 APS_Tongeber_defekt 0 "iO" 1 "defekt" ;
VAL_ 1626 BCM1_EasyEntry_Status 0 "Aus" 1 "Ein" ;
VAL_ 1626 BCM1_Lenksaeule_aktiv 0 "Lenksaeulenverstellung nicht aktiv" 1 "Lenksaeulenverstellung aktiv" ;
VAL_ 1626 BCM1_St_SW_Diebstahl_links 0 "Kein DIebstahl erkannt" 1 "Diebstahl erkannt" ;
VAL_ 1626 BCM1_St_SW_Diebstahl_rechts 0 "Kein DIebstahl erkannt" 1 "Diebstahl erkannt" ;
VAL_ 1626 BCM1_Schluesselsuche_Anf 0 "Anforderung_nicht_aktiv" 1 "Anforderung_aktiv" ;
VAL_ 1626 BCM1_Fahrlicht_Hinweis 0 "kein_Fahrlicht_Hinweis" 1 "Fahrlicht_Hinweis" ;
VAL_ 1626 BCM_HDF_betaetigt 0 "nicht_betaetigt" 1 "betaetigt" ;
VAL_ 672 BCM2_Crashfall_erkannt 0 "kein_Crashfall_erkannt" 1 "Crashfall_erkannt" ;
VAL_ 672 ZZH_Endlage_oben 0 "ZZH_nicht_in_oberer_Endlage" 1 "ZZH in Endlage oben" ;
VAL_ 672 ZZH_Endlage_unplausibel 0 "Endlage_ZZH_plausibel" 1 "unplausible Endlage der ZZH erkannt" ;
VAL_ 672 ZZH_Endlage_unten 0 "ZZH_nicht_in_unterer_Endlage" 1 "ZZH in Endlage unten" ;
VAL_ 672 BCM2_Unterdr_Zuendungsmeldung 0 "keine_Unterdr_der_Zuendungsmeldung" 1 "Unterdr_der_Zuendungsmeldung_aktiv" ;
VAL_ 672 BCM2_SST_gedrueckt 1 "SST gedrueckt" ;
VAL_ 672 BCM_Waehlhebel_P_Hinweis 0 "inaktiv" 1 "aktiv" ;
VAL_ 672 BCM_ValetTaster_Fkts_LED 0 "LED_aus" 1 "LED_ein" ;
VAL_ 672 BCM2_KL15_Absch_FT 0 "Zuendung_wurde_bei_Verl_nicht_deaktiviert" 1 "Zuendung_wurde_bei_Verl_deaktiviert" ;
VAL_ 672 Heckwischer_Status 0 "Init (kein Fehler, keine Ansteuerung)" 1 "Fehler / keine Ansteuerung" 2 "kein Fehler/ Ansteuerung aktiv" 3 "Fehler/ Ansteuerung aktiv" ;
VAL_ 672 BCM2_P_verriegelt 0 "WH nicht in Stellung P" 1 "WH in Stellung P" ;
VAL_ 672 FSH_LED 0 "Aus" 1 "Ein" ;
VAL_ 672 HSH_LED 0 "Aus" 1 "Ein" ;
VAL_ 672 Niveausensor_VL_verbaut 0 "nicht_verbaut" 1 "verbaut" ;
VAL_ 672 Niveausensor_HL_verbaut 0 "nicht_verbaut" 1 "verbaut" ;
VAL_ 672 FA_Hoehenwert_VL_01 254 "nicht initialisiert" 255 "Fehler" ;
VAL_ 672 FA_Hoehenwert_HL_01 254 "nicht initialisiert" 255 "Fehler" ;
VAL_ 672 BCM_Anf_Aussenwarnung 0 "nicht_angefordert" 1 "angefordert" ;
VAL_ 672 BCM_Aussenwarnung_Konfig 0 "Anforderungssignal wird 1:1 übernommen" 1 "1 Warnton" 2 "2 Warntöne" 3 "3 Warntöne" 4 "4 Warntöne" 5 "5 Warntöne" 6 "6 Warntöne" 7 "dauerhafte Sequenz bei aktivem Anforderungssignal" ;
VAL_ 672 BCM2_Freigabe_Kofferr_Innenentr 0 "keine_Freigabe" 1 "Freigabe" ;
VAL_ 672 BCM_RLU_Wakeup_Anforderung 0 "inaktiv" 1 "aktiv" ;
VAL_ 672 Heckrollo_Privacy_aktiv 0 "inaktiv" 1 "aktiv" ;
VAL_ 672 Heckrollo_Verfahrrichtung 0 "Init" 1 "Ruhe_unten" 2 "Heben" 3 "Senken" 4 "Ruhe_oben" 5 "reserviert" 6 "reserviert" 7 "reserviert" ;
VAL_ 672 BCM2_TrunkEntrapment_Warn 0 "Anzeige_Aus" 1 "Anzeige_Ein" ;
VAL_ 672 BCM2_Quittierung_Warnton_aktiv 0 "keine_Quittierung_Warnton_aktiv" 1 "Quittierung_Warnton_aktiv" ;
VAL_ 672 BCM_Handbremse_Hinweis 0 "inaktiv" 1 "aktiv" ;
VAL_ 672 Remote_Rollo_HBFS_hoch 0 "inaktiv" 1 "aktiv" ;
VAL_ 672 Remote_Rollo_HBFS_tief 0 "inaktiv" 1 "aktiv" ;
VAL_ 672 Remote_Rollo_HFS_hoch 0 "inaktiv" 1 "aktiv" ;
VAL_ 672 Remote_Rollo_HFS_tief 0 "inaktiv" 1 "aktiv" ;
VAL_ 672 BCM2_T_Deckel_Vorne 0 "nicht_betaetigt" 1 "betaetigt" ;
VAL_ 2589283629 BCM_DC_Suchvorgang_Status 0 "Init" 1 "Suche_nicht_OK" 2 "Transponderbetrieb_Suche_nicht_moeglich" 3 "reserved" ;
VAL_ 2589283629 BCM_DC_Batterie_Status 0 "Batteriestatus_OK" 1 "Batteriestatus_schwach" ;
VAL_ 2589283629 BCM_DC_erkannt 0 "Init" 1 "Driver_Card_Nr_1" 2 "Driver_Card_Nr_2" 3 "Driver_Card_Nr_3" 4 "Driver_Card_Nr_4" 5 "Driver_Card_Nr_5" 6 "Driver_Card_Nr_6" 7 "Driver_Card_Nr_7" ;
VAL_ 1448 BCM1_FlHz_Stufe_HR 0 "Aus" 1 "Stufe_1" 2 "Stufe_2" 3 "Stufe_3" 4 "Stufe_4" 5 "Stufe_5" 6 "Stufe_6" ;
VAL_ 1448 BCM1_FlHz_Stufe_HL 0 "Aus" 1 "Stufe_1" 2 "Stufe_2" 3 "Stufe_3" 4 "Stufe_4" 5 "Stufe_5" 6 "Stufe_6" ;
VAL_ 1448 BCM1_FlHz_Stufe_VR 0 "Aus" 1 "Stufe_1" 2 "Stufe_2" 3 "Stufe_3" 4 "Stufe_4" 5 "Stufe_5" 6 "Stufe_6" ;
VAL_ 1448 BCM1_FlHz_Stufe_VL 0 "Aus" 1 "Stufe_1" 2 "Stufe_2" 3 "Stufe_3" 4 "Stufe_4" 5 "Stufe_5" 6 "Stufe_6" ;
VAL_ 1448 BCM1_FlHz_Ruhesitz_HLR_Anf 0 "0_Prozent" 1 "33_Prozent" 2 "66_Prozent" 3 "100_Prozent" ;
VAL_ 1448 BCM1_FlHz_VR_HLR_Anf 0 "0_Prozent" 1 "33_Prozent" 2 "66_Prozent" 3 "100_Prozent" ;
VAL_ 1448 BCM1_FlHz_VL_HLR_Anf 0 "0_Prozent" 1 "33_Prozent" 2 "66_Prozent" 3 "100_Prozent" ;
VAL_ 1448 BCM1_FlHz_HL_HLR_Anf 0 "0_Prozent" 1 "33_Prozent" 2 "66_Prozent" 3 "100_Prozent" ;
VAL_ 1448 BCM1_FlHz_HR_HLR_Anf 0 "0_Prozent" 1 "33_Prozent" 2 "66_Prozent" 3 "100_Prozent" ;
VAL_ 1448 BCM1_FlHz_HBFS_PWM_B 101 "100_Prozent_PWM_SpgUnkompensiert" 127 "FnAbbruch_Slave_zuruecksetzen" ;
VAL_ 1448 BCM1_FlHz_HBFS_PWM_A 101 "100_Prozent_PWM_SpgUnkompensiert" 127 "FnAbbruch_Slave_zuruecksetzen" ;
VAL_ 1448 BCM1_FlHz_BFS_PWM_B 101 "100_Prozent_PWM_SpgUnkompensiert" 127 "FnAbbruch_Slave_zuruecksetzen" ;
VAL_ 1448 BCM1_FlHz_BFS_PWM_A 101 "100_Prozent_PWM_SpgUnkompensiert" 127 "FnAbbruch_Slave_zuruecksetzen" ;
VAL_ 961 Heckrollo_2_Taster 0 "Taste_nicht_betaetigt" 1 "Taste_entprellt_betaetigt" 2 "Init_oder_nicht_verbaut" 3 "Fehler" ;
VAL_ 961 APS_Taster 0 "Taste_nicht_betaetigt" 1 "Taste_entprellt_betaetigt" 2 "Init_oder_nicht_verbaut" 3 "Fehler" ;
VAL_ 961 PLA_Taster 0 "Taste_nicht_betaetigt" 1 "Taste_entprellt_betaetigt" 2 "Init_oder_nicht_verbaut" 3 "Fehler" ;
VAL_ 961 ESP_Off_Taster 0 "Taste_nicht_betaetigt" 1 "Taste_entprellt_betaetigt" 2 "Init_oder_nicht_verbaut" 3 "Fehler" ;
VAL_ 961 HDC_Taster 0 "Taste_nicht_betaetigt" 1 "Taste_entprellt_betaetigt" 2 "Init_oder_nicht_verbaut" 3 "Fehler" ;
VAL_ 961 AVH_Taster 0 "Taste_nicht_betaetigt" 1 "Taste_entprellt_betaetigt" 2 "Init_oder_nicht_verbaut" 3 "Fehler" ;
VAL_ 961 Display_Taster 0 "Taste_nicht_betaetigt" 1 "Taste_entprellt_betaetigt" 2 "Init_oder_nicht_verbaut" 3 "Fehler" ;
VAL_ 961 Heckrollo_Taster 0 "Taste_nicht_betaetigt" 1 "Taste_entprellt_betaetigt" 2 "Init_oder_nicht_verbaut" 3 "Fehler" ;
VAL_ 961 Spoiler_Taster 0 "Taste_nicht_betaetigt" 1 "Taste_entprellt_betaetigt" 2 "Init_oder_nicht_verbaut" 3 "Fehler" ;
VAL_ 961 Drivesel_1_Taster 0 "Taste_nicht_betaetigt" 1 "Taste_entprellt_betaetigt" 2 "Init_oder_nicht_verbaut" 3 "Fehler" ;
VAL_ 961 Drivesel_2_Taster 0 "Taste_nicht_betaetigt" 1 "Taste_entprellt_betaetigt" 2 "Init_oder_nicht_verbaut" 3 "Fehler" ;
VAL_ 961 Sideview_Taster 0 "Taste_nicht_betaetigt" 1 "Taste_entprellt_betaetigt" 2 "Init_oder_nicht_verbaut" 3 "Fehler" ;
VAL_ 961 LKS_Taster 0 "Taste_nicht_betaetigt" 1 "Taste_betaetigt" 2 "INIT_Taste_nicht_verbaut" 3 "Fehler" ;
VAL_ 961 SWA_Taster 0 "nicht_betaetigt" 1 "betaetigt" 2 "nicht_vorhanden" 3 "Fehler" ;
VAL_ 961 LIM_bCall_Taster 0 "nicht_betaetigt" 1 "betaetigt" ;
VAL_ 961 eCall_Taste 0 "button_released" 1 "button_pressed" 2 "discrete_line_broken" 3 "Fehler" ;
VAL_ 961 PLA_Taster_Fehler_Roh 0 "kein Fehler vorhanden" 1 "Fehler vorhanden" ;
VAL_ 961 LIM_PAO_ON_Status 0 "LED aus" 1 "LED an" 2 "LED blinkt" 3 "LED defekt" ;
VAL_ 961 LIM_PAO_OFF_Status 0 "LED aus" 1 "LED an" 2 "LED blinkt" 3 "LED defekt" ;
VAL_ 961 LIM_PAO_Schriftzug_Status 0 "LED aus" 1 "LED an" 2 "LED blinkt" 3 "LED defekt" ;
VAL_ 961 Spoiler_LED_Status 0 "LED_aus" 1 "LED_ein" 2 "LED_blinken" 3 "Fehler" ;
VAL_ 961 AVH_LED_Status 0 "LED_aus" 1 "LED_ein" 2 "LED_blinken" 3 "Fehler" ;
VAL_ 961 HDC_LED_Status 0 "LED_aus" 1 "LED_ein" 2 "LED_blinken" 3 "Fehler" ;
VAL_ 961 PLA_LED_Status 0 "LED_aus" 1 "LED_ein" 2 "LED_blinken" 3 "Fehler" ;
VAL_ 961 APS_LED_Status 0 "LED_aus" 1 "LED_ein" 2 "LED_blinken" 3 "Fehler" ;
VAL_ 1432 BCM_BFS_Fernsteuerung_aktiv 0 "inaktiv" 1 "aktiv" ;
VAL_ 1432 BCM_Soundklappe_Taster 0 "Taster_nicht_Betaetigt" 1 "Taster_Betaetigt" ;
VAL_ 1432 E_Sound_LED_Status 0 "LED_aus" 1 "LED_ein" 2 "LED_blinken" 3 "Fehler" ;
VAL_ 1432 Pilot_Taster 0 "Taste_nicht_betaetigt" 1 "Taste_entprellt_betaetigt" 2 "Init_oder_nicht_verbaut" 3 "Fehler" ;
VAL_ 1432 BCM1_eSound_Taster 0 "Taste_nicht_betaetigt" 1 "Taste_entprellt_betaetigt" 2 "Init_oder_nicht_verbaut" 3 "Fehler" ;
VAL_ 1432 BCM_FS_Programmwippe 0 "Taster_unbetaetigt" 1 "Taster_betaetigt" ;
VAL_ 1432 BCM_BFS_Programmwippe 0 "Taster_unbetaetigt" 1 "Taster_betaetigt" ;
VAL_ 1432 BCM_FS_Multif_Taster 0 "Taster_unbetaetigt" 1 "Taster_betaetigt" ;
VAL_ 1432 BCM_BFS_Multif_Taster 0 "Taster_unbetaetigt" 1 "Taster_betaetigt" ;
VAL_ 1432 BCM_FS_Massage_Taster 0 "Taster_unbetaetigt" 1 "Taster_betaetigt" ;
VAL_ 1432 BCM_BFS_Massage_Taster 0 "Taster_unbetaetigt" 1 "Taster_betaetigt" ;
VAL_ 1432 BCM_FS_Pneumatik_Verstellung 0 "keine_Verstellung" 1 "Pneumatikverstellung_aktiv" ;
VAL_ 1432 BCM_BFS_Pneumatik_Verstellung 0 "keine_Verstellung" 1 "Pneumatikverstellung_aktiv" ;
VAL_ 1432 LIM_Rear_Mode 0 "inaktiv" 1 "aktiv" ;
VAL_ 1432 BCM1_NR_Ride_Height_Up_Taster 0 "Taste_nicht_betaetigt" 1 "Taste_entprellt_betaetigt" 2 "Init_oder_nicht_verbaut" 3 "Fehler" ;
VAL_ 1432 BCM1_NR_Ride_Height_Down_Taster 0 "Taste_nicht_betaetigt" 1 "Taste_entprellt_betaetigt" 2 "Init_oder_nicht_verbaut" 3 "Fehler" ;
VAL_ 1432 LIM_S_Rollo_vo 0 "nicht_betaetigt" 1 "man_zu" 2 "auto_zu" 3 "man_auf" 4 "auto_auf" 5 "stop" 6 "fehler_schalter_haengt" 7 "fehler_schalter_unplausibel" ;
VAL_ 1432 LIM_S_Rollo_hi 0 "nicht_betaetigt" 1 "man_zu" 2 "auto_zu" 3 "man_auf" 4 "auto_auf" 5 "stop" 6 "fehler_schalter_haengt" 7 "fehler_schalter_unplausibel" ;
VAL_ 1432 LIM_S_SAD_Vo 0 "nicht_betaetigt" 1 "man_sl_zu" 2 "auto_sl_zu" 3 "man_sl_auf" 4 "auto_sl_auf" 5 "man_al_auf" 6 "auto_al_auf" 7 "man_al_zu" 8 "auto_al_zu" 9 "stop" 10 "Toggle_Taster_AL_betaetigt" 14 "fehler_schalter_haengt" 15 "fehler_schalter_unplausibel" ;
VAL_ 1432 LIM_S_SAD_hi 0 "nicht_betaetigt" 1 "man_sl_zu" 2 "auto_sl_zu" 3 "man_sl_auf" 4 "auto_sl_auf" 5 "man_al_auf" 6 "auto_al_auf" 7 "man_al_zu" 8 "auto_al_zu" 14 "fehler_schalter_haengt" 15 "fehler_schalter_unplausibel" ;
VAL_ 1462 BEB_hi_SAD_Rollo_AutoAuf 0 "Auto_Panoramadach_nicht_aktiv" 1 "Auto_Panoramadach_aktiv" ;
VAL_ 1462 BEB_hi_SAD_Rollo_AutoZu 0 "Automodus_schliessen_nicht_aktiv" 1 "Automodus_schliessen_aktiv" ;
VAL_ 1462 BEB_hi_SAD_Rollo_ManAuf 0 "Rollo_manuell_oeffnen_inaktiv" 1 "Rollo_manuell_oeffnen_aktiv" ;
VAL_ 1462 BEB_hi_SAD_Rollo_ManZu 0 "Rollo_schliessen_manuell_inaktiv" 1 "Rollo_schliessen_manuell_aktiv" ;
VAL_ 1462 BEB_hi_T_SIH_HL 0 "Taster_nicht_betaetigt" 1 "Taster_betaetigt" ;
VAL_ 1462 BEB_hi_T_SIH_HR 0 "Taster_nicht_betaetigt" 1 "Taster_betaetigt" ;
VAL_ 1462 BEB_hi_T_SIL_HL 0 "Taster_nicht_betaetigt" 1 "Taster_betaetigt" ;
VAL_ 1462 BEB_hi_T_SIL_HR 0 "Taster_nicht_betaetigt" 1 "Taster_betaetigt" ;
VAL_ 1462 SL1_Heckrollo_Taster 0 "Taste_unbetaetigt" 1 "Taste_betaetigt" 2 "Taste_nicht_verbaut" ;
VAL_ 1462 BEB_hi_SAD_Rollo_defekt 0 "inaktiv" 1 "aktiv" ;
VAL_ 1462 BEB_hi_SAD_Rollo_haengt 0 "inaktiv" 1 "aktiv" ;
VAL_ 1462 BEB_hi_T_Lueftung 0 "Taste_nicht_gedrueckt" 1 "Taste_gedrueckt" ;
VAL_ 1462 BEB_hi_T_Lueftung_oben 0 "Taste_nicht_gedrueckt" 1 "Taste_gedrueckt" ;
VAL_ 1462 BEB_hi_T_Lueftung_unten 0 "Taste_nicht_gedrueckt" 1 "Taste_gedrueckt" ;
VAL_ 1462 BEB_hi_T_Lueftung_LZ_links 0 "Taste_nicht_gedrueckt" 1 "Taste_gedrueckt" ;
VAL_ 1462 BEB_hi_T_Lueftung_LZ_rechts 0 "Taste_nicht_gedrueckt" 1 "Taste_gedrueckt" ;
VAL_ 1462 BEB_hi_T_Lueftung_RZ_links 0 "Taste_nicht_gedrueckt" 1 "Taste_gedrueckt" ;
VAL_ 1462 BEB_hi_T_Lueftung_RZ_rechts 0 "Taste_nicht_gedrueckt" 1 "Taste_gedrueckt" ;
VAL_ 1462 BEB_hi_ResponseError 0 "normal" 1 "Fehler" ;
VAL_ 1431 BED_Taster_VD_Oeffnen 0 "Taste_nicht_betaetigt" 1 "Taste_entprellt_betaetigt" 2 "Init_oder_nicht_verbaut" 3 "Fehler" ;
VAL_ 1431 BED_Taster_VD_Schliessen 0 "Taste_nicht_betaetigt" 1 "Taste_entprellt_betaetigt" 2 "Init_oder_nicht_verbaut" 3 "Fehler" ;
VAL_ 1431 BED_Taster_Windschott 0 "Taste_nicht_betaetigt" 1 "Taste_entprellt_betaetigt" 2 "Init_oder_nicht_verbaut" 3 "Fehler" ;
VAL_ 1431 BED_SAD_vo 0 "nicht_betaetigt" 1 "man_sl_zu" 2 "auto_sl_zu" 3 "man_sl_auf" 4 "auto_sl_auf" 5 "man_al_auf" 6 "auto_al_auf" 7 "man_al_zu" 8 "auto_al_zu" 14 "fehler_schalter_haengt" 15 "fehler_schalter_unplausibel" ;
VAL_ 1431 BED_Rollo_vo 0 "nicht_betaetigt" 1 "man_zu" 2 "auto_zu" 3 "man_auf" 4 "auto_auf" 6 "fehler_schalter_haengt" 7 "fehler_schalter_unplausibel" ;
VAL_ 1431 BED_Taster_Lift 0 "Taste_nicht_betaetigt" 1 "Taste_entprellt_betaetigt" 2 "Init_oder_nicht_verbaut" 3 "Fehler" ;
VAL_ 1431 SoSe_SunInt_2D_Re_Dash 254 "Init" 255 "Fehler" ;
VAL_ 1431 SoSe_SunInt_2D_Li_Dash 254 "Init" 255 "Fehler" ;
VAL_ 1431 BED_Taster_Fahrwerk 0 "Taste_nicht_betaetigt" 1 "Taste_entprellt_betaetigt" ;
VAL_ 870 BM_ZV_auf 0 "inaktiv" 1 "aktiv" ;
VAL_ 870 BM_ZV_zu 0 "inaktiv" 1 "aktiv" ;
VAL_ 870 BM_DWA_ein 0 "inaktiv" 1 "aktiv" ;
VAL_ 870 BM_DWA_Alarm 0 "inaktiv" 1 "aktiv" ;
VAL_ 870 BM_Crash 0 "inaktiv" 1 "aktiv" ;
VAL_ 870 BM_Panik 0 "inaktiv" 1 "aktiv" ;
VAL_ 870 BM_Not_Bremsung 0 "inaktiv" 1 "aktiv" ;
VAL_ 870 BM_GDO 0 "inaktiv" 1 "aktiv" ;
VAL_ 870 BM_Warnblinken 0 "inaktiv" 1 "aktiv" ;
VAL_ 870 BM_Taxi_Notalarm 0 "inaktiv" 1 "aktiv" ;
VAL_ 870 BM_Telematik 0 "inaktiv" 1 "aktiv" ;
VAL_ 870 BM_links 0 "inaktiv" 1 "aktiv" ;
VAL_ 870 BM_rechts 0 "inaktiv" 1 "aktiv" ;
VAL_ 870 Blinken_li_Fzg_Takt 0 "Blinker_links_ausgeschaltet" 1 "Blinker_links_eingeschaltet" ;
VAL_ 870 Blinken_re_Fzg_Takt 0 "Blinker_rechts_ausgeschaltet" 1 "Blinker_rechts_eingeschaltet" ;
VAL_ 870 Blinken_li_Kombi_Takt 0 "Blinkerkontrolllampe_links_ausgeschaltet" 1 "Blinkerkontrolllampe_links_eingeschaltet" ;
VAL_ 870 Blinken_re_Kombi_Takt 0 "Blinkerkontrolllampe_rechts_ausgeschaltet" 1 "Blinkerkontrolllampe_rechts_eingeschaltet" ;
VAL_ 870 BM_NBA_n_codiert_n_aktiv 0 "codiert_AND_kein_Fehler" 1 "nicht_codiert_OR_Fehler_erkannt" ;
VAL_ 870 BM_NBA_Status 0 "NBA_nicht_aktiv" 1 "BRL_Dunkelphase" 3 "BRL_Hellphase" ;
VAL_ 870 BM_WBT_Beleuchtung 0 "inaktiv" 1 "aktiv" ;
VAL_ 870 BM_HD_Oeffnung_angelernt 0 "keine_Quittierung" 1 "Quittierung" ;
VAL_ 870 BM_Autobahn 0 "inaktiv" 1 "aktiv" ;
VAL_ 870 BM_Rollenmodus_Blinken 0 "inaktiv" 1 "aktiv" ;
VAL_ 870 BM_Recas 0 "inaktiv" 1 "aktiv" ;
VAL_ 870 BM_Wischblinken 0 "inaktiv" 1 "aktiv" ;
VAL_ 870 BM_Telematik_Abbruchgrund 0 "Init" 1 "speed_out_of_range" 2 "defect" 3 "clamp_s_on" 4 "clamp_15_on" 5 "door_open" 6 "engine_hood_open" 7 "trunk_open" 8 "convertible_top_not_locked" 9 "horn_activated_by_user" 10 "Higher_Prioritiy_Function_active" 11 "Central_Lock_status_changed" 12 "Request_Dropped_by_Requester" 13 "Service_Duration_Expired" 14 "not_possible_due_to_coding" 15 "no_reason_or_unknown_timeout" ;
VAL_ 870 BM_PiloPa 0 "PiloPa_Blinkerquittierung_inaktiv" 1 "PiloPa_Blinkerquittierung_aktiv" ;
VAL_ 870 DWA_Alarmquelle 0 "kein_Ausloesegrund" 1 "Tuerkontakt_Fahrertuer" 2 "Tuerkontakt_Beifahrertuer" 3 "Tuerkontakt_hinten_links" 4 "Tuerkontakt_hinten_rechts" 5 "Motorhaubenkontakt_vorne" 6 "Kofferraum_hinten" 7 "Masseschleife_der_Heckscheibe" 8 "Innenraumueberwachung" 9 "Alarm_durch_Noteinstieg" 10 "Sounder" 11 "Neigungssensor" 12 "TSG_FT_am_CAN_Bus" 13 "TSG_BT_am_CAN_Bus" 14 "TSG_HFS_am_CAN_Bus" 15 "TSG_HBFS_am_CAN_Bus" 16 "Klemme_15" 17 "Klemme_15sig" 18 "frei" 19 "Anhaengerueberwachung" 20 "Scheinwerferueberwachung_links" 21 "Scheinwerferueberwachung_rechts" 22 "Handschuhkasten" 23 "Verdeckueberwachung" 24 "OBD_Alarm" 25 "Power_on_Reset" 30 "Init" 31 "Fehler" ;
VAL_ 401 BMS_IstStrom_02 4094 "Init" 4095 "Fehler" ;
VAL_ 401 BMS_IstSpannung 4094 "Init" 4095 "Fehler" ;
VAL_ 401 BMS_Spannung_ZwKr 2046 "Init" 2047 "Fehler" ;
VAL_ 401 BMS_SOC_HiRes 2046 "Init" 2047 "Fehler" ;
VAL_ 401 BMS_IstStrom_02_OffsetVZ 0 "Minus" 1 "Plus" ;
VAL_ 1482 BMS_Energieinhalt 2046 "Init" 2047 "Fehler" ;
VAL_ 1482 BMS_Ladevorgang_aktiv 0 "inaktiv" 1 "aktiv" ;
VAL_ 1482 BMS_Batteriediagnose 1 "Anzeige_Batterie" 4 "Anzeige_Batterie_OK" 5 "Anzeige_Batterie_Laden" 6 "Anzeige_Batterie_Pruefen" 7 "Fehler" ;
VAL_ 1482 BMS_Freig_max_Performanz 0 "Init" 1 "verfuegbar" 2 "nicht_verfuegbar" 3 "eingeschraenkt_verfuegbar" ;
VAL_ 1482 BMS_Balancing_Aktiv 0 "Init" 1 "aktiv" 2 "nicht_aktiv" ;
VAL_ 1482 BMS_MaxEnergieinhalt 2046 "Init" 2047 "Fehler" ;
VAL_ 1482 BMS_Ausgleichsladung_Anf 1 "Balancing_Request" ;
VAL_ 1482 BMS_Gesamtst_Spgfreiheit 0 "Funktion_nicht_aktiviert" 1 "HV_System_spannungsfrei" 2 "HV_System_nicht_spannungsfrei" 3 "Fehler_nicht_spannungsfrei" ;
VAL_ 1482 BMS_RIso_Ext 4094 "Init" 4095 "Fehler" ;
VAL_ 1482 BMS_KundenWarnung 0 "keine_Warnung" 1 "Warnung_Temperatur_Level1" 2 "Warnung_Temperatur_Level2" ;
VAL_ 1482 BMS_Fehler_KuehlkreislaufLeckage 0 "kein_Fehler" 1 "Fehler_KuehlkreislaufLeckage" ;
VAL_ 1111 BMS_Warnung_Stuetzung_NV 0 "Stuetzung_iO" 1 "Stuetzung_niO" 6 "Init" 7 "Fehler" ;
VAL_ 1111 BMS_RIso_GND_HVM 4094 "Init" 4095 "Fehler" ;
VAL_ 1111 BMS_RIso_GND_HVP 4094 "Init" 4095 "Fehler" ;
VAL_ 1111 BMS_Spannung_ZwKr2 2046 "Init" 2047 "Fehler" ;
VAL_ 823 CC_Einzelhindernis_01 0 "Init" 1 "Vertiefung_links" 2 "Erhoehung_links" 3 "Abfallende_Kante_links" 4 "Ansteigende_Kante_links" 5 "StossSchlag_links" 6 "Vertiefung_rechts" 7 "Erhoehung_rechts" 8 "Abfallende_Kante_rechts" 9 "Ansteigende_Kante_rechts" 10 "StossSchlag_rechts" 11 "Vertiefung_beidseitig" 12 "Erhoehung_beidseitig" 13 "Abfallende_Kante_beidseitig" 14 "Ansteigende_Kante_beidseitig" 15 "StossSchlagOderHindernis_untersc" ;
VAL_ 823 CC_CF_Einzelhindernis_01 0 "Init" 1 "Schlecht" 2 "Mittel" 3 "Gut" ;
VAL_ 823 CC_Einzelhindernis_02 0 "Keine_Information" 1 "SpeedBump1_Rechts" 2 "SpeedBump2_Rechts" 3 "SpeedBump3_Rechts" 4 "Schlagloch1_Rechts" 5 "Schlagloch2_Rechts" 6 "SpeedBump1_Links" 7 "SpeedBump2_Links" 8 "SpeedBump3_Links" 9 "Schlagloch1_Links" 10 "Schlagloch2_Links" 11 "SpeedBump1_Beidseitig" 12 "SpeedBump2_Beidseitig" 13 "SpeedBump3_Beidseitig" 14 "Schlagloch1_Beidseitig" 15 "Schlagloch2_Beidseitig" ;
VAL_ 823 CC_CF_Einzelhindernis_02 0 "Init" 1 "Schlecht" 2 "Mittel" 3 "Gut" ;
VAL_ 823 CC_Einzelhindernis_03 0 "Keine_Information" 1 "SpeedBump1_Rechts" 2 "SpeedBump2_Rechts" 3 "SpeedBump3_Rechts" 4 "Schlagloch1_Rechts" 5 "Schlagloch2_Rechts" 6 "SpeedBump1_Links" 7 "SpeedBump2_Links" 8 "SpeedBump3_Links" 9 "Schlagloch1_Links" 10 "Schlagloch2_Links" 11 "SpeedBump1_Beidseitig" 12 "SpeedBump2_Beidseitig" 13 "SpeedBump3_Beidseitig" 14 "Schlagloch1_Beidseitig" 15 "Schlagloch2_Beidseitig" ;
VAL_ 823 CC_CF_Einzelhindernis_03 0 "Init" 1 "Schlecht" 2 "Mittel" 3 "Gut" ;
VAL_ 823 CC_Einzelhindernis_04 0 "Keine_Information" 1 "SpeedBump1_Rechts" 2 "SpeedBump2_Rechts" 3 "SpeedBump3_Rechts" 4 "Schlagloch1_Rechts" 5 "Schlagloch2_Rechts" 6 "SpeedBump1_Links" 7 "SpeedBump2_Links" 8 "SpeedBump3_Links" 9 "Schlagloch1_Links" 10 "Schlagloch2_Links" 11 "SpeedBump1_Beidseitig" 12 "SpeedBump2_Beidseitig" 13 "SpeedBump3_Beidseitig" 14 "Schlagloch1_Beidseitig" 15 "Schlagloch2_Beidseitig" ;
VAL_ 823 CC_CF_Einzelhindernis_04 0 "Init" 1 "Schlecht" 2 "Mittel" 3 "Gut" ;
VAL_ 823 CC_Einzelhindernis_05 0 "Keine_Information" 1 "SpeedBump1_Rechts" 2 "SpeedBump2_Rechts" 3 "SpeedBump3_Rechts" 4 "Schlagloch1_Rechts" 5 "Schlagloch2_Rechts" 6 "SpeedBump1_Links" 7 "SpeedBump2_Links" 8 "SpeedBump3_Links" 9 "Schlagloch1_Links" 10 "Schlagloch2_Links" 11 "SpeedBump1_Beidseitig" 12 "SpeedBump2_Beidseitig" 13 "SpeedBump3_Beidseitig" 14 "Schlagloch1_Beidseitig" 15 "Schlagloch2_Beidseitig" ;
VAL_ 823 CC_CF_Einzelhindernis_05 0 "Init" 1 "Schlecht" 2 "Mittel" 3 "Gut" ;
VAL_ 823 CC_Einzelhindernis_06 0 "Keine_Information" 1 "SpeedBump1_Rechts" 2 "SpeedBump2_Rechts" 3 "SpeedBump3_Rechts" 4 "Schlagloch1_Rechts" 5 "Schlagloch2_Rechts" 6 "SpeedBump1_Links" 7 "SpeedBump2_Links" 8 "SpeedBump3_Links" 9 "Schlagloch1_Links" 10 "Schlagloch2_Links" 11 "SpeedBump1_Beidseitig" 12 "SpeedBump2_Beidseitig" 13 "SpeedBump3_Beidseitig" 14 "Schlagloch1_Beidseitig" 15 "Schlagloch2_Beidseitig" ;
VAL_ 823 CC_CF_Einzelhindernis_06 0 "Keine_Information" 1 "Hohe_Konfidenz" 2 "Mittlere_Konfidenz" 3 "Niedrige_Konfidenz" ;
VAL_ 823 CC_Einzelhindernis_07 0 "Keine_Information" 1 "SpeedBump1_Rechts" 2 "SpeedBump2_Rechts" 3 "SpeedBump3_Rechts" 4 "Schlagloch1_Rechts" 5 "Schlagloch2_Rechts" 6 "SpeedBump1_Links" 7 "SpeedBump2_Links" 8 "SpeedBump3_Links" 9 "Schlagloch1_Links" 10 "Schlagloch2_Links" 11 "SpeedBump1_Beidseitig" 12 "SpeedBump2_Beidseitig" 13 "SpeedBump3_Beidseitig" 14 "Schlagloch1_Beidseitig" 15 "Schlagloch2_Beidseitig" ;
VAL_ 823 CC_CF_Einzelhindernis_07 0 "Keine_Information" 1 "Hohe_Konfidenz" 2 "Mittlere_Konfidenz" 3 "Niedrige_Konfidenz" ;
VAL_ 823 CC_Einzelhindernis_08 0 "Keine_Information" 1 "SpeedBump1_Rechts" 2 "SpeedBump2_Rechts" 3 "SpeedBump3_Rechts" 4 "Schlagloch1_Rechts" 5 "Schlagloch2_Rechts" 6 "SpeedBump1_Links" 7 "SpeedBump2_Links" 8 "SpeedBump3_Links" 9 "Schlagloch1_Links" 10 "Schlagloch2_Links" 11 "SpeedBump1_Beidseitig" 12 "SpeedBump2_Beidseitig" 13 "SpeedBump3_Beidseitig" 14 "Schlagloch1_Beidseitig" 15 "Schlagloch2_Beidseitig" ;
VAL_ 823 CC_CF_Einzelhindernis_08 0 "Keine_Information" 1 "Hohe_Konfidenz" 2 "Mittlere_Konfidenz" 3 "Niedrige_Konfidenz" ;
VAL_ 824 CC_Strassenkategorie_01 0 "Keine_Strasseninformation" 1 "StrassenkatSGut_WelligkeitNiedri" 2 "StrassenkatSGut_WelligkeitNormal" 3 "StrassenkatSGut_WelligkeitHoch" 4 "StrassenkatGut_WelligkeitNiedrig" 5 "StrassenkatGut_WelligkeitNormal" 6 "StrassenkatGut_WelligkeitHoch" 7 "StrassenkatMittel_WelligkeitNied" 8 "StrassenkatMittel_WelligkeitNorm" 9 "StrassenkatMittel_WelligkeitHoch" 10 "StrassenkatSchlecht_WelligkeitNg" 11 "StrassenkatSchlecht_WelligkeitNm" 12 "StrassenkatSchlecht_WelligkeitHo" 13 "StrassenktSSchlecht_WelligkeitNg" 14 "StrassenktSSchlecht_WelligkeitNm" 15 "StrassenktSSchlecht_WelligkeitHo" ;
VAL_ 824 CC_CF_Strassenkategorie_01 0 "Init" 1 "Schlecht" 2 "Mittel" 3 "Gut" ;
VAL_ 824 CC_Strassenkategorie_02 0 "Keine_Information" 1 "Strassenzustand_1" 2 "Strassenzustand_2" 3 "Strassenzustand_3" 4 "Strassenzustand_4" 5 "Strassenzustand_5" 6 "Strassenzustand_6" 7 "Strassenzustand_7" 8 "Strassenzustand_8" 9 "Strassenzustand_9" 10 "Strassenzustand_10" 11 "Strassenzustand_11" 12 "Strassenzustand_12" 13 "Strassenzustand_13" 14 "Strassenzustand_14" 15 "Strassenzustand_15" ;
VAL_ 824 CC_CF_Strassenkategorie_02 0 "Init" 1 "Schlecht" 2 "Mittel" 3 "Gut" ;
VAL_ 824 CC_Strassenkategorie_03 0 "Keine_Information" 1 "Strassenzustand_1" 2 "Strassenzustand_2" 3 "Strassenzustand_3" 4 "Strassenzustand_4" 5 "Strassenzustand_5" 6 "Strassenzustand_6" 7 "Strassenzustand_7" 8 "Strassenzustand_8" 9 "Strassenzustand_9" 10 "Strassenzustand_10" 11 "Strassenzustand_11" 12 "Strassenzustand_12" 13 "Strassenzustand_13" 14 "Strassenzustand_14" 15 "Strassenzustand_15" ;
VAL_ 824 CC_CF_Strassenkategorie_03 0 "Init" 1 "Schlecht" 2 "Mittel" 3 "Gut" ;
VAL_ 824 CC_Strassenkategorie_04 0 "Keine_Information" 1 "Strassenzustand_1" 2 "Strassenzustand_2" 3 "Strassenzustand_3" 4 "Strassenzustand_4" 5 "Strassenzustand_5" 6 "Strassenzustand_6" 7 "Strassenzustand_7" 8 "Strassenzustand_8" 9 "Strassenzustand_9" 10 "Strassenzustand_10" 11 "Strassenzustand_11" 12 "Strassenzustand_12" 13 "Strassenzustand_13" 14 "Strassenzustand_14" 15 "Strassenzustand_15" ;
VAL_ 824 CC_CF_Strassenkategorie_04 0 "Init" 1 "Schlecht" 2 "Mittel" 3 "Gut" ;
VAL_ 824 CC_Strassenkategorie_05 0 "Keine_Information" 1 "Strassenzustand_1" 2 "Strassenzustand_2" 3 "Strassenzustand_3" 4 "Strassenzustand_4" 5 "Strassenzustand_5" 6 "Strassenzustand_6" 7 "Strassenzustand_7" 8 "Strassenzustand_8" 9 "Strassenzustand_9" 10 "Strassenzustand_10" 11 "Strassenzustand_11" 12 "Strassenzustand_12" 13 "Strassenzustand_13" 14 "Strassenzustand_14" 15 "Strassenzustand_15" ;
VAL_ 824 CC_CF_Strassenkategorie_05 0 "Keine_Information" 1 "Hohe_Konfidenz" 2 "Mittlere_Konfidenz" 3 "Niedrige_Konfidenz" ;
VAL_ 824 CC_Strassenkategorie_06 0 "Keine_Information" 1 "Strassenzustand_1" 2 "Strassenzustand_2" 3 "Strassenzustand_3" 4 "Strassenzustand_4" 5 "Strassenzustand_5" 6 "Strassenzustand_6" 7 "Strassenzustand_7" 8 "Strassenzustand_8" 9 "Strassenzustand_9" 10 "Strassenzustand_10" 11 "Strassenzustand_11" 12 "Strassenzustand_12" 13 "Strassenzustand_13" 14 "Strassenzustand_14" 15 "Strassenzustand_15" ;
VAL_ 824 CC_CF_Strassenkategorie_06 0 "Keine_Information" 1 "Hohe_Konfidenz" 2 "Mittlere_Konfidenz" 3 "Niedrige_Konfidenz" ;
VAL_ 824 CC_Strassenkategorie_07 0 "Keine_Information" 1 "Strassenzustand_1" 2 "Strassenzustand_2" 3 "Strassenzustand_3" 4 "Strassenzustand_4" 5 "Strassenzustand_5" 6 "Strassenzustand_6" 7 "Strassenzustand_7" 8 "Strassenzustand_8" 9 "Strassenzustand_9" 10 "Strassenzustand_10" 11 "Strassenzustand_11" 12 "Strassenzustand_12" 13 "Strassenzustand_13" 14 "Strassenzustand_14" 15 "Strassenzustand_15" ;
VAL_ 824 CC_CF_Strassenkategorie_07 0 "Keine_Information" 1 "Hohe_Konfidenz" 2 "Mittlere_Konfidenz" 3 "Niedrige_Konfidenz" ;
VAL_ 824 CC_Strassenkategorie_08 0 "Keine_Information" 1 "Strassenzustand_1" 2 "Strassenzustand_2" 3 "Strassenzustand_3" 4 "Strassenzustand_4" 5 "Strassenzustand_5" 6 "Strassenzustand_6" 7 "Strassenzustand_7" 8 "Strassenzustand_8" 9 "Strassenzustand_9" 10 "Strassenzustand_10" 11 "Strassenzustand_11" 12 "Strassenzustand_12" 13 "Strassenzustand_13" 14 "Strassenzustand_14" 15 "Strassenzustand_15" ;
VAL_ 824 CC_CF_Strassenkategorie_08 0 "Keine_Information" 1 "Hohe_Konfidenz" 2 "Mittlere_Konfidenz" 3 "Niedrige_Konfidenz" ;
VAL_ 901 CHA_Ziel_FahrPr_AGA 0 "keine_Funktion" 1 "Programm_1" 2 "Programm_2" 3 "Programm_3" 4 "Programm_4" 5 "Programm_5" 6 "Programm_6" 7 "Programm_7" 8 "Programm_8" 9 "Programm_9" 10 "Programm_10" 11 "Programm_11" 12 "Programm_12" 13 "Programm_13" 14 "Programm_14" 15 "Programm_15" ;
VAL_ 901 CHA_Ziel_FahrPr_ESP 0 "keine_Funktion" 1 "Programm_1" 2 "Programm_2" 3 "Programm_3" 4 "Programm_4" 5 "Programm_5" 6 "Programm_6" 7 "Programm_7" 8 "Programm_8" 9 "Programm_9" 10 "Programm_10" 11 "Programm_11" 12 "Programm_12" 13 "Programm_13" 14 "Programm_14" 15 "Programm_15" ;
VAL_ 901 CHA_Ziel_FahrPr_Freilauf 0 "keine_Funktion" 1 "Programm_1" 2 "Programm_2" 3 "Programm_3" 4 "Programm_4" 5 "Programm_5" 6 "Programm_6" 7 "Programm_7" 8 "Programm_8" 9 "Programm_9" 10 "Programm_10" 11 "Programm_11" 12 "Programm_12" 13 "Programm_13" 14 "Programm_14" 15 "Programm_15" ;
VAL_ 901 CHA_Fahrer_Umschaltung 0 "keine_oder_automatische_Umschaltung" 1 "manuelle_Umschaltung" ;
VAL_ 901 CHA_Fahrer_Umschaltung_BMA 0 "keine_oder_autom_Umschaltung" 1 "manuelle_Umschaltung" ;
VAL_ 901 CHA_Ziel_FahrPr_MO 0 "keine_Funktion" 1 "Programm_1" 2 "Programm_2" 3 "Programm_3" 4 "Programm_4" 5 "Programm_5" 6 "Programm_6" 7 "Programm_7" 8 "Programm_8" 9 "Programm_9" 10 "Programm_10" 11 "Programm_11" 12 "Programm_12" 13 "Programm_13" 14 "Programm_14" 15 "Programm_15" ;
VAL_ 901 CHA_Ziel_FahrPr_GE 0 "keine_Funktion" 1 "Programm_1" 2 "Programm_2" 3 "Programm_3" 4 "Programm_4" 5 "Programm_5" 6 "Programm_6" 7 "Programm_7" 8 "Programm_8" 9 "Programm_9" 10 "Programm_10" 11 "Programm_11" 12 "Programm_12" 13 "Programm_13" 14 "Programm_14" 15 "Programm_15" ;
VAL_ 901 CHA_Ziel_FahrPr_ALR 0 "keine_Funktion" 1 "Programm_1" 2 "Programm_2" 3 "Programm_3" 4 "Programm_4" 5 "Programm_5" 6 "Programm_6" 7 "Programm_7" 8 "Programm_8" 9 "Programm_9" 10 "Programm_10" 11 "Programm_11" 12 "Programm_12" 13 "Programm_13" 14 "Programm_14" 15 "Programm_15" ;
VAL_ 901 CHA_Ziel_FahrPr_MO_BZS 0 "keine_Funktion" 1 "Programm_1" 2 "Programm_2" 3 "Programm_3" 4 "Programm_4" 5 "Programm_5" 6 "Programm_6" 7 "Programm_7" 8 "Programm_8" 9 "Programm_9" 10 "Programm_10" 11 "Programm_11" 12 "Programm_12" 13 "Programm_13" 14 "Programm_14" 15 "Programm_15" ;
VAL_ 901 CHA_Ziel_FahrPr_DR 0 "keine_Funktion" 1 "Programm_1" 2 "Programm_2" 3 "Programm_3" 4 "Programm_4" 5 "Programm_5" 6 "Programm_6" 7 "Programm_7" 8 "Programm_8" 9 "Programm_9" 10 "Programm_10" 11 "Programm_11" 12 "Programm_12" 13 "Programm_13" 14 "Programm_14" 15 "Programm_15" ;
VAL_ 901 CHA_Ziel_FahrPr_VAQ 0 "keine_Funktion" 1 "Programm_1" 2 "Programm_2" 3 "Programm_3" 4 "Programm_4" 5 "Programm_5" 6 "Programm_6" 7 "Programm_7" 8 "Programm_8" 9 "Programm_9" 10 "Programm_10" 11 "Programm_11" 12 "Programm_12" 13 "Programm_13" 14 "Programm_14" 15 "Programm_15" ;
VAL_ 901 CHA_Ziel_FahrPr_AFS 0 "keine_Funktion" 1 "Programm_1" 2 "Programm_2" 3 "Programm_3" 4 "Programm_4" 5 "Programm_5" 6 "Programm_6" 7 "Programm_7" 8 "Programm_8" 9 "Programm_9" 10 "Programm_10" 11 "Programm_11" 12 "Programm_12" 13 "Programm_13" 14 "Programm_14" 15 "Programm_15" ;
VAL_ 901 CHA_Ziel_FahrPr_PreCrash 0 "keine_Funktion" 1 "Programm_1" 2 "Programm_2" 3 "Programm_3" 4 "Programm_4" 5 "Programm_5" 6 "Programm_6" 7 "Programm_7" 8 "Programm_8" 9 "Programm_9" 10 "Programm_10" 11 "Programm_11" 12 "Programm_12" 13 "Programm_13" 14 "Programm_14" 15 "Programm_15" ;
VAL_ 901 CHA_Ziel_FahrPr_EPS 0 "keine_Funktion" 1 "Programm_1" 2 "Programm_2" 3 "Programm_3" 4 "Programm_4" 5 "Programm_5" 6 "Programm_6" 7 "Programm_7" 8 "Programm_8" 9 "Programm_9" 10 "Programm_10" 11 "Programm_11" 12 "Programm_12" 13 "Programm_13" 14 "Programm_14" 15 "Programm_15" ;
VAL_ 901 CHA_Ziel_FahrPr_ACC 0 "keine_Funktion" 1 "Programm_1" 2 "Programm_2" 3 "Programm_3" 4 "Programm_4" 5 "Programm_5" 6 "Programm_6" 7 "Programm_7" 8 "Programm_8" 9 "Programm_9" 10 "Programm_10" 11 "Programm_11" 12 "Programm_12" 13 "Programm_13" 14 "Programm_14" 15 "Programm_15" ;
VAL_ 901 CHA_Ziel_FahrPr_SAK 0 "keine_Funktion" 1 "Programm_1" 2 "Programm_2" 3 "Programm_3" 4 "Programm_4" 5 "Programm_5" 6 "Programm_6" 7 "Programm_7" 8 "Programm_8" 9 "Programm_9" 10 "Programm_10" 11 "Programm_11" 12 "Programm_12" 13 "Programm_13" 14 "Programm_14" 15 "Programm_15" ;
VAL_ 901 CHA_Ziel_FahrPr_MO_StSt 0 "keine_Funktion" 1 "Programm_1" 2 "Programm_2" 3 "Programm_3" 4 "Programm_4" 5 "Programm_5" 6 "Programm_6" 7 "Programm_7" 8 "Programm_8" 9 "Programm_9" 10 "Programm_10" 11 "Programm_11" 12 "Programm_12" 13 "Programm_13" 14 "Programm_14" 15 "Programm_15" ;
VAL_ 902 CHA_Eco_Charisma_LED 0 "LED_aus_und_Blinken_aus" 1 "LED_ein_und_Blinken_aus" 2 "LED_ein_und_Blinken_ein_50_percent" 3 "reserviert" ;
VAL_ 902 CHA_Fahrer_Umschaltung 0 "keine_oder_automatische_Umschaltung" 1 "manuelle_Umschaltung" ;
VAL_ 902 CHA_EV_LED 0 "LED_aus" 1 "LED_an" ;
VAL_ 902 CHA_Ziel_FahrPr_AMB 0 "keine_Funktion" 1 "Programm_1" 2 "Programm_2" 3 "Programm_3" 4 "Programm_4" 5 "Programm_5" 6 "Programm_6" 7 "Programm_7" 8 "Programm_8" 9 "Programm_9" 10 "Programm_10" 11 "Programm_11" 12 "Programm_12" 13 "Programm_13" 14 "Programm_14" 15 "Programm_15" ;
VAL_ 902 CHA_Ziel_FahrPr_IVB 0 "keine_Funktion" 1 "Programm_1" 2 "Programm_2" 3 "Programm_3" 4 "Programm_4" 5 "Programm_5" 6 "Programm_6" 7 "Programm_7" 8 "Programm_8" 9 "Programm_9" 10 "Programm_10" 11 "Programm_11" 12 "Programm_12" 13 "Programm_13" 14 "Programm_14" 15 "Programm_15" ;
VAL_ 902 CHA_Kombi_Texte 0 "keine_Anzeige" 1 "Text_1" 2 "Text_2" 3 "Text_3" 4 "Text_4" 5 "Text_5" 6 "Text_6" 7 "Text_7" 8 "Text_8" 9 "Text_9" 10 "Text_10" 11 "Text_11" 12 "Text_12" 13 "Text_13" 14 "Text_14" 15 "Text_15" ;
VAL_ 902 CHA_Ziel_FahrPr_KL 0 "keine_Funktion" 1 "Programm_1" 2 "Programm_2" 3 "Programm_3" 4 "Programm_4" 5 "Programm_5" 6 "Programm_6" 7 "Programm_7" 8 "Programm_8" 9 "Programm_9" 10 "Programm_10" 11 "Programm_11" 12 "Programm_12" 13 "Programm_13" 14 "Programm_14" 15 "Programm_15" ;
VAL_ 902 CHA_Ziel_FahrPr_HSP 0 "keine_Funktion" 1 "Programm_1" 2 "Programm_2" 3 "Programm_3" 4 "Programm_4" 5 "Programm_5" 6 "Programm_6" 7 "Programm_7" 8 "Programm_8" 9 "Programm_9" 10 "Programm_10" 11 "Programm_11" 12 "Programm_12" 13 "Programm_13" 14 "Programm_14" 15 "Programm_15" ;
VAL_ 902 CHA_Drehschalter_Istmodus 0 "keine_Schalterstellung" 1 "Schalterstellung_1" 2 "Schalterstellung_2" 3 "Schalterstellung_3" 4 "Schalterstellung_4" 5 "Schalterstellung_5" 6 "Schalterstellung_6" 7 "Schalterstellung_7" 8 "Schalterstellung_8" 9 "Schalterstellung_9" 10 "Schalterstellung_10" 11 "Schalterstellung_11" 12 "Schalterstellung_12" 13 "Schalterstellung_13" 14 "Schalterstellung_14" 15 "Schalterstellung_15" ;
VAL_ 902 CHA_Ziel_FahrPr_RWB 0 "keine_Funktion" 1 "Programm_1" 2 "Programm_2" 3 "Programm_3" 4 "Programm_4" 5 "Programm_5" 6 "Programm_6" 7 "Programm_7" 8 "Programm_8" 9 "Programm_9" 10 "Programm_10" 11 "Programm_11" 12 "Programm_12" 13 "Programm_13" 14 "Programm_14" 15 "Programm_15" ;
VAL_ 902 CHA_Ziel_FahrPr_03_01 0 "keine_Funktion" 1 "Programm_1" 2 "Programm_2" 3 "Programm_3" 4 "Programm_4" 5 "Programm_5" 6 "Programm_6" 7 "Programm_7" 8 "Programm_8" 9 "Programm_9" 10 "Programm_10" 11 "Programm_11" 12 "Programm_12" 13 "Programm_13" 14 "Programm_14" 15 "Programm_15" ;
VAL_ 902 CHA_Ziel_FahrPr_03_02 0 "keine_Funktion" 1 "Programm_1" 2 "Programm_2" 3 "Programm_3" 4 "Programm_4" 5 "Programm_5" 6 "Programm_6" 7 "Programm_7" 8 "Programm_8" 9 "Programm_9" 10 "Programm_10" 11 "Programm_11" 12 "Programm_12" 13 "Programm_13" 14 "Programm_14" 15 "Programm_15" ;
VAL_ 902 CHA_Current_Mode 0 "keine_Funktion" 1 "Programm_1" 2 "Programm_2" 3 "Programm_3" 4 "Programm_4" 5 "Programm_5" 6 "Programm_6" 7 "Programm_7" 8 "Programm_8" 9 "Programm_9" 10 "Programm_10" 11 "Programm_11" 12 "Programm_12" 13 "Programm_13" 14 "Programm_14" 15 "Programm_15" ;
VAL_ 902 CHA_Charge_LED 0 "LED_aus" 1 "LED_ein" ;
VAL_ 902 CHA_Offroad_LED 0 "LED_aus" 1 "LED_ein" 2 "LED_blinken" 3 "Fehler" ;
VAL_ 902 CHA_Kombi_Texte_02 0 "Init" 1 "Text_1" 2 "Text_2" 3 "Text_3" 4 "Text_4" 5 "Text_5" 6 "Text_6" 7 "Text_7" 8 "Text_8" 9 "Text_9" 10 "Text_10" 11 "Text_11" 12 "Text_12" 13 "Text_13" 14 "Text_14" 15 "Text_15" ;
VAL_ 615 DR_Systemstatus 0 "Init oder kein Wert verfuegbar" 1 "Komfortabel" 2 "Normal" 3 "Sport 1" 4 "Sport 2" 5 "nicht funktionsfähig" 6 "Funktionseinschränkung aktiv" 7 "Notfahrfunktion" ;
VAL_ 615 DR_ESP_Zuschaltung 0 "keine_ESP_Beeinflussung" 1 "ESP_Zwangszuschaltung_gefordert" ;
VAL_ 615 DR_DynAGL_Anf_Entkopplung 0 "inaktiv" 1 "aktiv" ;
VAL_ 615 DR_DynAGL_Anf_im_Leerlauf 0 "inaktiv" 1 "aktiv" ;
VAL_ 615 EFP_Niveauzustand_Lift 0 "Init" 1 "gesenkt" 2 "heben" 3 "gehoben" 4 "senken" 5 "Fehler" ;
VAL_ 615 EFP_Verfuegbarkeit_Lift 0 "Init" 1 "verfuegbar" 2 "temporaer_nicht_verfuegbar" 3 "Fehler_Service_notwendig" 4 "Temperaturschutz" 5 "Fehler_Niveauplausibilisierung" ;
VAL_ 615 DR_Charisma_FahrPr 0 "keine_Funktion" 1 "Programm_1" 2 "Programm_2" 3 "Programm_3" 4 "Programm_4" 5 "Programm_5" 6 "Programm_6" 7 "Programm_7" 8 "Programm_8" 9 "Programm_9" 10 "Programm_10" 11 "Programm_11" 12 "Programm_12" 13 "Programm_13" 14 "Programm_14" 15 "Programm_15" ;
VAL_ 615 DR_Charisma_Status 0 "Init" 1 "verfuegbar" 2 "nicht_verfuegbar" 3 "asynchron_durch_Fahrerwunsch" ;
VAL_ 615 EFP_Vorlaufzeit_Lift 6 "Init" 7 "Fehler" ;
VAL_ 2617219614 DEV_ZR_Pwm_Debug_1 0 "nicht_angefordert" 1 "angefordert" ;
VAL_ 2617219614 DEV_ZR_Pwm_Debug_2 0 "nicht_angefordert" 1 "angefordert" ;
VAL_ 2617219614 DEV_ZR_Pwm_Debug_3 0 "nicht_angefordert" 1 "angefordert" ;
VAL_ 2617219614 DEV_ZR_Pwm_Debug_4 0 "nicht_angefordert" 1 "angefordert" ;
VAL_ 2617219605 ZR_KL_30F 254 "Init" 255 "Fehler" ;
VAL_ 2617219605 ZR_TempSens 254 "Init" 255 "Fehler" ;
VAL_ 2617219605 Reset_Counter 254 "Init" 255 "Fehler" ;
VAL_ 2617219605 MMI_State 0 "MMI_OFF" 1 "MMI_IOC" 2 "MMI_STDBY" 3 "MMI_ON" 4 "MMI_STDBY_PWR_SAVE" 5 "MMI_STDBY_RESTR" 6 "MMI_ON_DIAG" 7 "MMI_ON_TEL" 8 "MMI_ON_SWDL" 9 "MMI_ON_CUST_SWDL" 10 "MMI_STDBY_PWR_SAVE_1" 11 "MMI_STDBY_PWR_SAVE_2" 12 "MMI_STANDBY_CUST_SWDL" 13 "MMI_ONLINE_IOC" 14 "MMI_ONLINE" 15 "MMI_PHONE_IOC" 16 "MMI_PHONE" 17 "MMI_RTC" 18 "MMI_DCI" ;
VAL_ 2617219605 Tel_aktiv 0 "inaktiv" 1 "aktiv" ;
VAL_ 2617219605 Routeg_aktiv 0 "inaktiv" 1 "aktiv" ;
VAL_ 2617219605 ZR_LastOn 7 "Init" ;
VAL_ 2617219605 SI_MOST_Status 0 "MOST_sleep_(Licht_AUS)" 1 "MOST_aktiv_(Kommunikation_moeglich)" ;
VAL_ 2617219605 ZR_State_DU_1 0 "Disp_Off" 1 "Disp_On" 2 "LowPow" ;
VAL_ 2617219605 Tel_SIM_aktiv 0 "inaktiv" 1 "aktiv" ;
VAL_ 1714 DGN_Verlernzaehler 255 "ungültiger Zählerstand oder kein gültiger Fahrzyklus" ;
VAL_ 1714 KBI_Kilometerstand 1048574 "Init" 1048575 "Fehler" ;
VAL_ 1714 UH_Monat 0 "Init" 14 "Relatives_Datum" 15 "Fehler" ;
VAL_ 1714 UH_Tag 0 "Init" ;
VAL_ 1714 Kombi_02_alt 0 "aktuell" 1 "veraltet" ;
VAL_ 1714 Uhrzeit_01_alt 0 "aktuell" 1 "veraltet" ;
VAL_ 1520 DI_KL_58xd 254 "Init" 255 "Fehler" ;
VAL_ 1520 DI_KL_58xs 126 "Init" 127 "Fehler" ;
VAL_ 1520 DI_KL_58xt 126 "Init" 127 "Fehler" ;
VAL_ 1520 BCM1_Stellgroesse_Kl_58s 125 "Nicht_verbaut" 126 "Init" 127 "Fehler" ;
VAL_ 420 EA_Parken_beibehalten_HMS 0 "Parken_nicht_beibehalten" 1 "Parken_beibehalten" 2 "Init" 3 "Fehler" ;
VAL_ 420 EA_Warnruckprofil 0 "keine_Ruckanforderung" 1 "Profil_1" 2 "Profil_2" 3 "Profil_3" 4 "Profil_4" 5 "Profil_5" 6 "Profil_6" 7 "Profil_7" ;
VAL_ 420 EA_eCall_Anf 0 "Keine_Anforderung" 1 "Ausloesen_eCall" ;
VAL_ 420 EA_Funktionsstatus 0 "EA_INIT" 1 "EA_OFF" 2 "EA_STANDBY" 3 "EA_PHASE0_AKTIV" 4 "EA_PHASE1_AKTIV" 5 "EA_PHASE2_AKTIV" 6 "EA_PHASE3_AKTIV" 7 "EA_REVERSIBLER_FEHLER" 8 "EA_IRREVERSIBLER_FEHLER" ;
VAL_ 420 EA_Gurtstraffer_Anf 0 "Keine_Anforderung" 1 "Haptik_1" 2 "Haptik_2" 3 "Haptik_3" ;
VAL_ 420 EA_Anforderung_HMS 0 "keine_Anforderung" 1 "halten" 2 "parken" 3 "halten_Standby" 4 "anfahren" 5 "Loesen_ueber_Rampe" 6 "Parken_mit_P" ;
VAL_ 420 EA_Sollbeschleunigung 2046 "Neutralwert" 2047 "Fehler" ;
